VERSION "j1939-2025-03-v2.4-light"

NS_ :

BS_:

BU_:

BO_ 2364651518 HVESP3MS1: 8 Vector__XXX
 SG_ Hvesp3Module1OperationalStatus : 0|2@1+ (1,0) [0|3] "" Vector__XXX
 SG_ Hvesp3Module2OperationalStatus : 2|2@1+ (1,0) [0|3] "" Vector__XXX
 SG_ Hvesp3Module3OperationalStatus : 4|2@1+ (1,0) [0|3] "" Vector__XXX
 SG_ Hvesp3Module4OperationalStatus : 6|2@1+ (1,0) [0|3] "" Vector__XXX
 SG_ Hvesp3Module5OperationalStatus : 8|2@1+ (1,0) [0|3] "" Vector__XXX
 SG_ Hvesp3Module6OperationalStatus : 10|2@1+ (1,0) [0|3] "" Vector__XXX
 SG_ Hvesp3Module7OperationalStatus : 12|2@1+ (1,0) [0|3] "" Vector__XXX
 SG_ Hvesp3Module8OperationalStatus : 14|2@1+ (1,0) [0|3] "" Vector__XXX
 SG_ Hvesp3Module9OperationalStatus : 16|2@1+ (1,0) [0|3] "" Vector__XXX
 SG_ Hvesp3Module10OperationalStatus : 18|2@1+ (1,0) [0|3] "" Vector__XXX
 SG_ Hvesp3Module11OperationalStatus : 20|2@1+ (1,0) [0|3] "" Vector__XXX
 SG_ Hvesp3Module12OperationalStatus : 22|2@1+ (1,0) [0|3] "" Vector__XXX
 SG_ Hvesp3Module13OperationalStatus : 24|2@1+ (1,0) [0|3] "" Vector__XXX
 SG_ Hvesp3Module14OperationalStatus : 26|2@1+ (1,0) [0|3] "" Vector__XXX
 SG_ Hvesp3Module15OperationalStatus : 28|2@1+ (1,0) [0|3] "" Vector__XXX
 SG_ Hvesp3Module16OperationalStatus : 30|2@1+ (1,0) [0|3] "" Vector__XXX
 SG_ Hvesp3Module17OperationalStatus : 32|2@1+ (1,0) [0|3] "" Vector__XXX
 SG_ Hvesp3Module18OperationalStatus : 34|2@1+ (1,0) [0|3] "" Vector__XXX
 SG_ Hvesp3Module19OperationalStatus : 36|2@1+ (1,0) [0|3] "" Vector__XXX
 SG_ Hvesp3Module20OperationalStatus : 38|2@1+ (1,0) [0|3] "" Vector__XXX
 SG_ Hvesp3Module21OperationalStatus : 40|2@1+ (1,0) [0|3] "" Vector__XXX
 SG_ Hvesp3Module22OperationalStatus : 42|2@1+ (1,0) [0|3] "" Vector__XXX
 SG_ Hvesp3Module23OperationalStatus : 44|2@1+ (1,0) [0|3] "" Vector__XXX
 SG_ Hvesp3Module24OperationalStatus : 46|2@1+ (1,0) [0|3] "" Vector__XXX
 SG_ Hvesp3Module25OperationalStatus : 48|2@1+ (1,0) [0|3] "" Vector__XXX
 SG_ Hvesp3Module26OperationalStatus : 50|2@1+ (1,0) [0|3] "" Vector__XXX
 SG_ Hvesp3Module27OperationalStatus : 52|2@1+ (1,0) [0|3] "" Vector__XXX
 SG_ Hvesp3Module28OperationalStatus : 54|2@1+ (1,0) [0|3] "" Vector__XXX
 SG_ Hvesp3Module29OperationalStatus : 56|2@1+ (1,0) [0|3] "" Vector__XXX
 SG_ Hvesp3Module30OperationalStatus : 58|2@1+ (1,0) [0|3] "" Vector__XXX
 SG_ Hvesp3Module31OperationalStatus : 60|2@1+ (1,0) [0|3] "" Vector__XXX
 SG_ Hvesp3Module32OperationalStatus : 62|2@1+ (1,0) [0|3] "" Vector__XXX

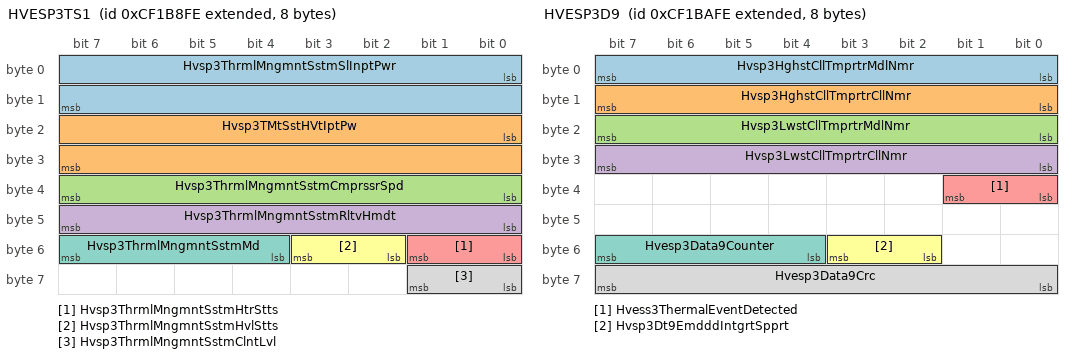
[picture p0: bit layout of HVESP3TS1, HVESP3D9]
BO_ 2364651774 HVESP3TS1: 8 Vector__XXX
 SG_ Hvsp3ThrmlMngmntSstmSlInptPwr : 0|16@1+ (0.5,0) [0|32127.5] "W" Vector__XXX
 SG_ Hvsp3TMtSstHVtIptPw : 16|16@1+ (0.5,0) [0|32127.5] "W" Vector__XXX
 SG_ Hvsp3ThrmlMngmntSstmCmprssrSpd : 32|8@1+ (32,0) [0|8000] "rpm" Vector__XXX
 SG_ Hvsp3ThrmlMngmntSstmRltvHmdt : 40|8@1+ (0.4,0) [0|100] "%" Vector__XXX
 SG_ Hvsp3ThrmlMngmntSstmHtrStts : 48|2@1+ (1,0) [0|3] "" Vector__XXX
 SG_ Hvsp3ThrmlMngmntSstmHvlStts : 50|2@1+ (1,0) [0|3] "" Vector__XXX
 SG_ Hvsp3ThrmlMngmntSstmMd : 52|4@1+ (1,0) [0|15] "" Vector__XXX
 SG_ Hvsp3ThrmlMngmntSstmClntLvl : 56|2@1+ (1,0) [0|3] "" Vector__XXX

BO_ 2364652030 HVESP3D8: 8 Vector__XXX
 SG_ Hvesp3AverageCellVoltage : 32|16@1+ (0.001,0) [0|64.255] "V" Vector__XXX
 SG_ Hvsp3HghstCllVltgMdlNmr : 0|8@1+ (1,0) [0|250] "count" Vector__XXX
 SG_ Hvsp3HghstCllVltgCllNmr : 8|8@1+ (1,0) [0|250] "count" Vector__XXX
 SG_ Hvsp3LwstCllVltgMdlNmr : 16|8@1+ (1,0) [0|250] "count" Vector__XXX
 SG_ Hvsp3LwstCllVltgCllNmr : 24|8@1+ (1,0) [0|250] "count" Vector__XXX

BO_ 2364652286 HVESP3D9: 8 Vector__XXX
 SG_ Hvsp3HghstCllTmprtrMdlNmr : 0|8@1+ (1,0) [0|250] "count" Vector__XXX
 SG_ Hvsp3HghstCllTmprtrCllNmr : 8|8@1+ (1,0) [0|250] "count" Vector__XXX
 SG_ Hvsp3LwstCllTmprtrMdlNmr : 16|8@1+ (1,0) [0|250] "count" Vector__XXX
 SG_ Hvsp3LwstCllTmprtrCllNmr : 24|8@1+ (1,0) [0|250] "count" Vector__XXX
 SG_ Hvess3ThermalEventDetected : 32|2@1+ (1,0) [0|3] "" Vector__XXX
 SG_ Hvsp3Dt9EmdddIntgrtSpprt : 50|2@1+ (1,0) [0|3] "" Vector__XXX
 SG_ Hvesp3Data9Counter : 52|4@1+ (1,0) [0|15] "" Vector__XXX
 SG_ Hvesp3Data9Crc : 56|8@1+ (1,0) [0|250] "count" Vector__XXX

BO_ 2364652542 HVESP3D10: 8 Vector__XXX
 SG_ Hvsp3HghstCllSttOfChrgMdlNmr : 0|8@1+ (1,0) [0|250] "count" Vector__XXX
 SG_ Hvsp3HghstCllSttOfChrgCllNmr : 8|8@1+ (1,0) [0|250] "count" Vector__XXX
 SG_ Hvsp3LwstCllSttOfChrgMdlNmr : 16|8@1+ (1,0) [0|250] "count" Vector__XXX
 SG_ Hvsp3LwstCllSttOfChrgCllNmr : 24|8@1+ (1,0) [0|250] "count" Vector__XXX
 SG_ Hvsp3HghVltgBsAtvIsltnTstRslts : 32|16@1+ (0.1,0) [0|6425.5] "OhmPerV" Vector__XXX
 SG_ Hvsp3HghVltgBsPssvIsltnTstRslts : 48|16@1+ (0.1,0) [0|6425.5] "OhmPerV" Vector__XXX

BO_ 2364652798 HVESP3D11: 8 Vector__XXX
 SG_ Hvesp3ActualChargeRate : 32|16@1+ (0.05,0) [0|3212.75] "kW" Vector__XXX
 SG_ Hvsp3BsVltgNgtvTChsssGrndVltg : 0|16@1+ (0.05,0) [0|3212.75] "V" Vector__XXX
 SG_ Hvsp3VltgLvlNgtvTChsssGrndVltg : 16|16@1+ (0.05,0) [0|3212.75] "V" Vector__XXX

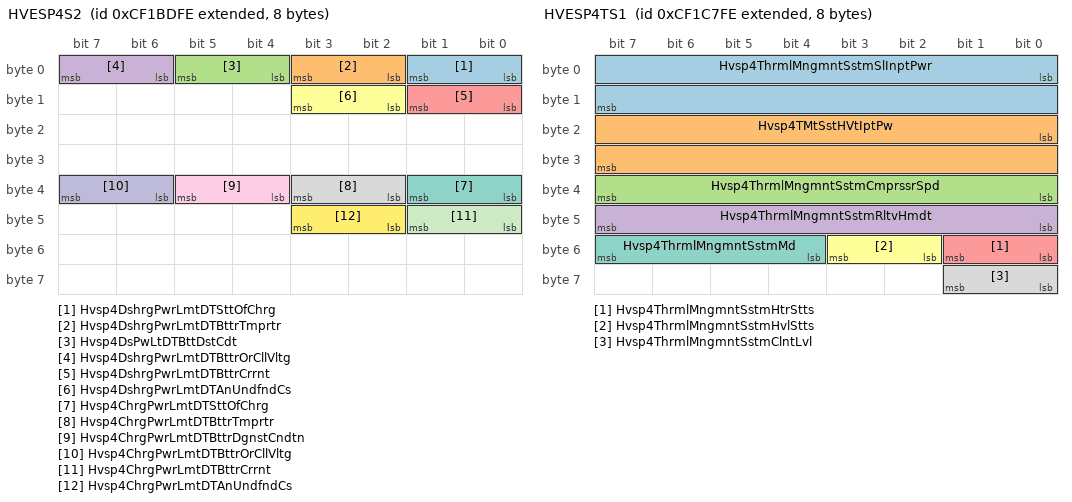
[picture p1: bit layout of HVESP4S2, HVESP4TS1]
BO_ 2364653054 HVESP4S2: 8 Vector__XXX
 SG_ Hvsp4DshrgPwrLmtDTSttOfChrg : 0|2@1+ (1,0) [0|3] "" Vector__XXX
 SG_ Hvsp4DshrgPwrLmtDTBttrTmprtr : 2|2@1+ (1,0) [0|3] "" Vector__XXX
 SG_ Hvsp4DsPwLtDTBttDstCdt : 4|2@1+ (1,0) [0|3] "" Vector__XXX
 SG_ Hvsp4DshrgPwrLmtDTBttrOrCllVltg : 6|2@1+ (1,0) [0|3] "" Vector__XXX
 SG_ Hvsp4DshrgPwrLmtDTBttrCrrnt : 8|2@1+ (1,0) [0|3] "" Vector__XXX
 SG_ Hvsp4DshrgPwrLmtDTAnUndfndCs : 10|2@1+ (1,0) [0|3] "" Vector__XXX
 SG_ Hvsp4ChrgPwrLmtDTSttOfChrg : 32|2@1+ (1,0) [0|3] "" Vector__XXX
 SG_ Hvsp4ChrgPwrLmtDTBttrTmprtr : 34|2@1+ (1,0) [0|3] "" Vector__XXX
 SG_ Hvsp4ChrgPwrLmtDTBttrDgnstCndtn : 36|2@1+ (1,0) [0|3] "" Vector__XXX
 SG_ Hvsp4ChrgPwrLmtDTBttrOrCllVltg : 38|2@1+ (1,0) [0|3] "" Vector__XXX
 SG_ Hvsp4ChrgPwrLmtDTBttrCrrnt : 40|2@1+ (1,0) [0|3] "" Vector__XXX
 SG_ Hvsp4ChrgPwrLmtDTAnUndfndCs : 42|2@1+ (1,0) [0|3] "" Vector__XXX

BO_ 2364653310 HVESP4D1: 8 Vector__XXX
 SG_ Hvesp4AvailableDischargePower : 0|16@1+ (0.05,0) [0|3212.75] "kW" Vector__XXX
 SG_ Hvesp4AvailableChargePower : 16|16@1+ (0.05,0) [0|3212.75] "kW" Vector__XXX
 SG_ Hvesp4VoltageLevel : 32|16@1+ (0.05,0) [0|3212.75] "V" Vector__XXX
 SG_ Hvesp4Current : 48|16@1+ (0.05,-1600) [-1600|1612.75] "A" Vector__XXX

BO_ 2364653566 HVESP4D2: 8 Vector__XXX
 SG_ Hvesp4FastUpdateStateOfCharge : 0|16@1+ (0.0015625,0) [0|100.3984375] "%" Vector__XXX
 SG_ Hvesp4HighestCellVoltage : 16|16@1+ (0.001,0) [0|64.255] "V" Vector__XXX
 SG_ Hvesp4LowestCellVoltage : 32|16@1+ (0.001,0) [0|64.255] "V" Vector__XXX
 SG_ Hvsp4CllVltgDffrntlStts : 48|4@1+ (1,0) [0|15] "" Vector__XXX

BO_ 2364653822 HVESP4D3: 8 Vector__XXX
 SG_ Hvesp4HighestCellTemperature : 0|16@1+ (0.03125,-273) [-273|1734.96875] "degC" Vector__XXX
 SG_ Hvesp4LowestCellTemperature : 16|16@1+ (0.03125,-273) [-273|1734.96875] "degC" Vector__XXX
 SG_ Hvesp4AverageCellTemperature : 32|16@1+ (0.03125,-273) [-273|1734.96875] "degC" Vector__XXX
 SG_ Hvsp4CllTmprtrDffrntlStts : 48|2@1+ (1,0) [0|3] "" Vector__XXX

BO_ 2364654078 HVESP4D4: 8 Vector__XXX
 SG_ Hvesp4DischargeCapacity : 0|16@1+ (0.01,0) [0|642.55] "Ah" Vector__XXX
 SG_ Hvesp4ChargeCapacity : 16|16@1+ (0.01,0) [0|642.55] "Ah" Vector__XXX
 SG_ Hvesp4CellBalancingCount : 32|16@1+ (1,0) [0|64255] "count" Vector__XXX

BO_ 2364654334 HVESP4D5: 8 Vector__XXX
 SG_ Hvesp4LowestCellStateOfCharge : 32|16@1+ (0.0015625,0) [0|100.3984375] "%" Vector__XXX
 SG_ Hvesp4HighestCellStateOfCharge : 48|16@1+ (0.0015625,0) [0|100.3984375] "%" Vector__XXX
 SG_ Hvsp4MxmmInstntnsDshrgCrrntLmt : 0|16@1+ (0.05,-1600) [-1600|0] "A" Vector__XXX
 SG_ Hvsp4MxmmInstntnsChrgCrrntLmt : 16|16@1+ (0.05,-1600) [0|1612.75] "A" Vector__XXX

BO_ 2364654590 HVESP4D6: 8 Vector__XXX
 SG_ Hvesp4BusVoltage : 0|16@1+ (0.05,0) [0|3212.75] "V" Vector__XXX
 SG_ Hvesp4IgnitionVoltage : 16|16@1+ (0.01,0) [0|642.55] "V" Vector__XXX
 SG_ Hvesp4IntakeCoolantTemperature : 32|8@1+ (1,-40) [-40|210] "degC" Vector__XXX
 SG_ Hvesp4OutletCoolantTemperature : 40|8@1+ (1,-40) [-40|210] "degC" Vector__XXX
 SG_ Hvesp4ElectronicsTemperature : 48|8@1+ (1,-40) [-40|210] "degC" Vector__XXX
 SG_ Hvesp4Temperature : 56|8@1+ (1,-40) [-40|210] "degC" Vector__XXX

BO_ 2364654846 HVESP4S1: 8 Vector__XXX
 SG_ Hvesp4HvilStatus : 20|2@1+ (1,0) [0|3] "" Vector__XXX
 SG_ Hvesp4InertiaSwitchStatus : 22|2@1+ (1,0) [0|3] "" Vector__XXX
 SG_ Hvesp4StateOfChargeStatus : 24|4@1+ (1,0) [0|15] "" Vector__XXX
 SG_ Hvesp4CellBalanceStatus : 28|2@1+ (1,0) [0|3] "" Vector__XXX
 SG_ Hvesp4CellBalancingActive : 30|2@1+ (1,0) [0|3] "" Vector__XXX
 SG_ Hvesp4InternalChargerStatus : 32|2@1+ (1,0) [0|3] "" Vector__XXX
 SG_ Hvesp4OperationalStatus : 44|4@1+ (1,0) [0|15] "" Vector__XXX
 SG_ Hvesp4Status1Counter : 52|4@1+ (1,0) [0|15] "" Vector__XXX
 SG_ Hvesp4Status1Crc : 56|8@1+ (1,0) [0|250] "count" Vector__XXX
 SG_ Hvsp4HghVltgBsPstvCnttrStt : 0|2@1+ (1,0) [0|3] "" Vector__XXX
 SG_ Hvsp4HghVltgBsNgtvCnttrStt : 2|2@1+ (1,0) [0|3] "" Vector__XXX
 SG_ Hvsp4HghVltgBsDsnntFrwrnng : 4|4@1+ (1,0) [0|15] "" Vector__XXX
 SG_ Hvsp4HghVltgBsPrChrgRlStt : 8|2@1+ (1,0) [0|3] "" Vector__XXX
 SG_ Hvsp4CntrOfPkCnttrStt : 10|2@1+ (1,0) [0|3] "" Vector__XXX
 SG_ Hvsp4HghVltgBsAtvIsltnTstStts : 12|4@1+ (1,0) [0|15] "" Vector__XXX
 SG_ Hvsp4HghVltgBsPssvIsltnTstStts : 16|4@1+ (1,0) [0|15] "" Vector__XXX
 SG_ Hvsp4HghVltgBsCnntnStts : 40|4@1+ (1,0) [0|15] "" Vector__XXX

BO_ 2364655102 HVESP4D7: 8 Vector__XXX
 SG_ Hvesp4DischargeEnergyCapacity : 0|24@1+ (0.001,0) [0|16449.535] "kWh" Vector__XXX
 SG_ Hvesp4ChargeEnergyCapacity : 24|24@1+ (0.001,0) [0|16449.535] "kWh" Vector__XXX
 SG_ Hvesp4MaximumChargeVoltageLimit : 48|16@1+ (0.05,0) [0|3212.75] "V" Vector__XXX

BO_ 2364655358 HVESP4MS1: 8 Vector__XXX
 SG_ Hvesp4Module1OperationalStatus : 0|2@1+ (1,0) [0|3] "" Vector__XXX
 SG_ Hvesp4Module2OperationalStatus : 2|2@1+ (1,0) [0|3] "" Vector__XXX
 SG_ Hvesp4Module3OperationalStatus : 4|2@1+ (1,0) [0|3] "" Vector__XXX
 SG_ Hvesp4Module4OperationalStatus : 6|2@1+ (1,0) [0|3] "" Vector__XXX
 SG_ Hvesp4Module5OperationalStatus : 8|2@1+ (1,0) [0|3] "" Vector__XXX
 SG_ Hvesp4Module6OperationalStatus : 10|2@1+ (1,0) [0|3] "" Vector__XXX
 SG_ Hvesp4Module7OperationalStatus : 12|2@1+ (1,0) [0|3] "" Vector__XXX
 SG_ Hvesp4Module8OperationalStatus : 14|2@1+ (1,0) [0|3] "" Vector__XXX
 SG_ Hvesp4Module9OperationalStatus : 16|2@1+ (1,0) [0|3] "" Vector__XXX
 SG_ Hvesp4Module10OperationalStatus : 18|2@1+ (1,0) [0|3] "" Vector__XXX
 SG_ Hvesp4Module11OperationalStatus : 20|2@1+ (1,0) [0|3] "" Vector__XXX
 SG_ Hvesp4Module12OperationalStatus : 22|2@1+ (1,0) [0|3] "" Vector__XXX
 SG_ Hvesp4Module13OperationalStatus : 24|2@1+ (1,0) [0|3] "" Vector__XXX
 SG_ Hvesp4Module14OperationalStatus : 26|2@1+ (1,0) [0|3] "" Vector__XXX
 SG_ Hvesp4Module15OperationalStatus : 28|2@1+ (1,0) [0|3] "" Vector__XXX
 SG_ Hvesp4Module16OperationalStatus : 30|2@1+ (1,0) [0|3] "" Vector__XXX
 SG_ Hvesp4Module17OperationalStatus : 32|2@1+ (1,0) [0|3] "" Vector__XXX
 SG_ Hvesp4Module18OperationalStatus : 34|2@1+ (1,0) [0|3] "" Vector__XXX
 SG_ Hvesp4Module19OperationalStatus : 36|2@1+ (1,0) [0|3] "" Vector__XXX
 SG_ Hvesp4Module20OperationalStatus : 38|2@1+ (1,0) [0|3] "" Vector__XXX
 SG_ Hvesp4Module21OperationalStatus : 40|2@1+ (1,0) [0|3] "" Vector__XXX
 SG_ Hvesp4Module22OperationalStatus : 42|2@1+ (1,0) [0|3] "" Vector__XXX
 SG_ Hvesp4Module23OperationalStatus : 44|2@1+ (1,0) [0|3] "" Vector__XXX
 SG_ Hvesp4Module24OperationalStatus : 46|2@1+ (1,0) [0|3] "" Vector__XXX
 SG_ Hvesp4Module25OperationalStatus : 48|2@1+ (1,0) [0|3] "" Vector__XXX
 SG_ Hvesp4Module26OperationalStatus : 50|2@1+ (1,0) [0|3] "" Vector__XXX
 SG_ Hvesp4Module27OperationalStatus : 52|2@1+ (1,0) [0|3] "" Vector__XXX
 SG_ Hvesp4Module28OperationalStatus : 54|2@1+ (1,0) [0|3] "" Vector__XXX
 SG_ Hvesp4Module29OperationalStatus : 56|2@1+ (1,0) [0|3] "" Vector__XXX
 SG_ Hvesp4Module30OperationalStatus : 58|2@1+ (1,0) [0|3] "" Vector__XXX
 SG_ Hvesp4Module31OperationalStatus : 60|2@1+ (1,0) [0|3] "" Vector__XXX
 SG_ Hvesp4Module32OperationalStatus : 62|2@1+ (1,0) [0|3] "" Vector__XXX

BO_ 2364655614 HVESP4TS1: 8 Vector__XXX
 SG_ Hvsp4ThrmlMngmntSstmSlInptPwr : 0|16@1+ (0.5,0) [0|32127.5] "W" Vector__XXX
 SG_ Hvsp4TMtSstHVtIptPw : 16|16@1+ (0.5,0) [0|32127.5] "W" Vector__XXX
 SG_ Hvsp4ThrmlMngmntSstmCmprssrSpd : 32|8@1+ (32,0) [0|8000] "rpm" Vector__XXX
 SG_ Hvsp4ThrmlMngmntSstmRltvHmdt : 40|8@1+ (0.4,0) [0|100] "%" Vector__XXX
 SG_ Hvsp4ThrmlMngmntSstmHtrStts : 48|2@1+ (1,0) [0|3] "" Vector__XXX
 SG_ Hvsp4ThrmlMngmntSstmHvlStts : 50|2@1+ (1,0) [0|3] "" Vector__XXX
 SG_ Hvsp4ThrmlMngmntSstmMd : 52|4@1+ (1,0) [0|15] "" Vector__XXX
 SG_ Hvsp4ThrmlMngmntSstmClntLvl : 56|2@1+ (1,0) [0|3] "" Vector__XXX

BO_ 2364655870 HVESP4D8: 8 Vector__XXX
 SG_ Hvesp4AverageCellVoltage : 32|16@1+ (0.001,0) [0|64.255] "V" Vector__XXX
 SG_ Hvsp4HghstCllVltgMdlNmr : 0|8@1+ (1,0) [0|250] "count" Vector__XXX
 SG_ Hvsp4HghstCllVltgCllNmr : 8|8@1+ (1,0) [0|250] "count" Vector__XXX
 SG_ Hvsp4LwstCllVltgMdlNmr : 16|8@1+ (1,0) [0|250] "count" Vector__XXX
 SG_ Hvsp4LwstCllVltgCllNmr : 24|8@1+ (1,0) [0|250] "count" Vector__XXX

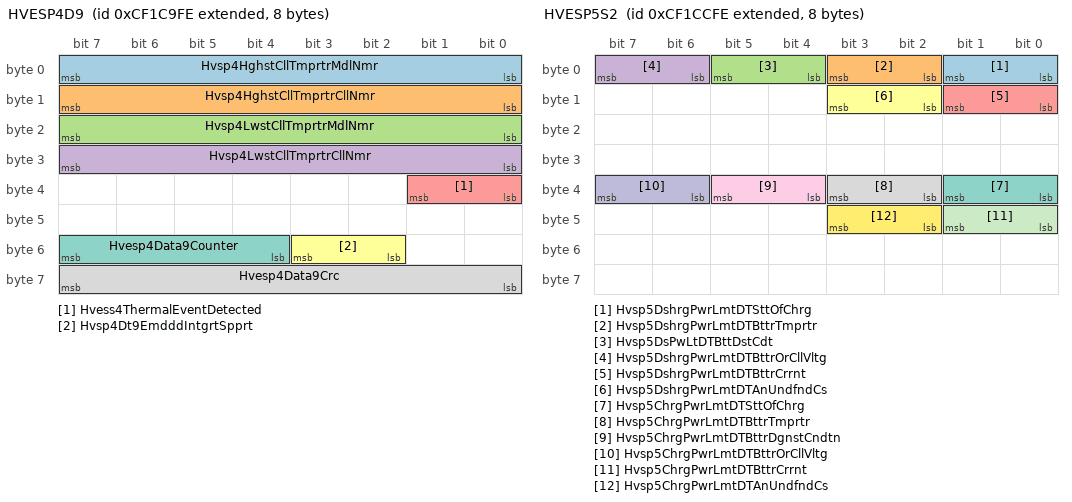
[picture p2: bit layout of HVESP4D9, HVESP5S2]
BO_ 2364656126 HVESP4D9: 8 Vector__XXX
 SG_ Hvsp4HghstCllTmprtrMdlNmr : 0|8@1+ (1,0) [0|250] "count" Vector__XXX
 SG_ Hvsp4HghstCllTmprtrCllNmr : 8|8@1+ (1,0) [0|250] "count" Vector__XXX
 SG_ Hvsp4LwstCllTmprtrMdlNmr : 16|8@1+ (1,0) [0|250] "count" Vector__XXX
 SG_ Hvsp4LwstCllTmprtrCllNmr : 24|8@1+ (1,0) [0|250] "count" Vector__XXX
 SG_ Hvess4ThermalEventDetected : 32|2@1+ (1,0) [0|3] "" Vector__XXX
 SG_ Hvsp4Dt9EmdddIntgrtSpprt : 50|2@1+ (1,0) [0|3] "" Vector__XXX
 SG_ Hvesp4Data9Counter : 52|4@1+ (1,0) [0|15] "" Vector__XXX
 SG_ Hvesp4Data9Crc : 56|8@1+ (1,0) [0|250] "count" Vector__XXX

BO_ 2364656382 HVESP4D10: 8 Vector__XXX
 SG_ Hvsp4HghstCllSttOfChrgMdlNmr : 0|8@1+ (1,0) [0|250] "count" Vector__XXX
 SG_ Hvsp4HghstCllSttOfChrgCllNmr : 8|8@1+ (1,0) [0|250] "count" Vector__XXX
 SG_ Hvsp4LwstCllSttOfChrgMdlNmr : 16|8@1+ (1,0) [0|250] "count" Vector__XXX
 SG_ Hvsp4LwstCllSttOfChrgCllNmr : 24|8@1+ (1,0) [0|250] "count" Vector__XXX
 SG_ Hvsp4HghVltgBsAtvIsltnTstRslts : 32|16@1+ (0.1,0) [0|6425.5] "OhmPerV" Vector__XXX
 SG_ Hvsp4HghVltgBsPssvIsltnTstRslts : 48|16@1+ (0.1,0) [0|6425.5] "OhmPerV" Vector__XXX

BO_ 2364656638 HVESP4D11: 8 Vector__XXX
 SG_ Hvesp4ActualChargeRate : 32|16@1+ (0.05,0) [0|3212.75] "kW" Vector__XXX
 SG_ Hvsp4BsVltgNgtvTChsssGrndVltg : 0|16@1+ (0.05,0) [0|3212.75] "V" Vector__XXX
 SG_ Hvsp4VltgLvlNgtvTChsssGrndVltg : 16|16@1+ (0.05,0) [0|3212.75] "V" Vector__XXX

BO_ 2364656894 HVESP5S2: 8 Vector__XXX
 SG_ Hvsp5DshrgPwrLmtDTSttOfChrg : 0|2@1+ (1,0) [0|3] "" Vector__XXX
 SG_ Hvsp5DshrgPwrLmtDTBttrTmprtr : 2|2@1+ (1,0) [0|3] "" Vector__XXX
 SG_ Hvsp5DsPwLtDTBttDstCdt : 4|2@1+ (1,0) [0|3] "" Vector__XXX
 SG_ Hvsp5DshrgPwrLmtDTBttrOrCllVltg : 6|2@1+ (1,0) [0|3] "" Vector__XXX
 SG_ Hvsp5DshrgPwrLmtDTBttrCrrnt : 8|2@1+ (1,0) [0|3] "" Vector__XXX
 SG_ Hvsp5DshrgPwrLmtDTAnUndfndCs : 10|2@1+ (1,0) [0|3] "" Vector__XXX
 SG_ Hvsp5ChrgPwrLmtDTSttOfChrg : 32|2@1+ (1,0) [0|3] "" Vector__XXX
 SG_ Hvsp5ChrgPwrLmtDTBttrTmprtr : 34|2@1+ (1,0) [0|3] "" Vector__XXX
 SG_ Hvsp5ChrgPwrLmtDTBttrDgnstCndtn : 36|2@1+ (1,0) [0|3] "" Vector__XXX
 SG_ Hvsp5ChrgPwrLmtDTBttrOrCllVltg : 38|2@1+ (1,0) [0|3] "" Vector__XXX
 SG_ Hvsp5ChrgPwrLmtDTBttrCrrnt : 40|2@1+ (1,0) [0|3] "" Vector__XXX
 SG_ Hvsp5ChrgPwrLmtDTAnUndfndCs : 42|2@1+ (1,0) [0|3] "" Vector__XXX

BO_ 2364657150 HVESP5D1: 8 Vector__XXX
 SG_ Hvesp5AvailableDischargePower : 0|16@1+ (0.05,0) [0|3212.75] "kW" Vector__XXX
 SG_ Hvesp5AvailableChargePower : 16|16@1+ (0.05,0) [0|3212.75] "kW" Vector__XXX
 SG_ Hvesp5VoltageLevel : 32|16@1+ (0.05,0) [0|3212.75] "V" Vector__XXX
 SG_ Hvesp5Current : 48|16@1+ (0.05,-1600) [-1600|1612.75] "A" Vector__XXX

BO_ 2364657406 HVESP5D2: 8 Vector__XXX
 SG_ Hvesp5FastUpdateStateOfCharge : 0|16@1+ (0.0015625,0) [0|100.3984375] "%" Vector__XXX
 SG_ Hvesp5HighestCellVoltage : 16|16@1+ (0.001,0) [0|64.255] "V" Vector__XXX
 SG_ Hvesp5LowestCellVoltage : 32|16@1+ (0.001,0) [0|64.255] "V" Vector__XXX
 SG_ Hvsp5CllVltgDffrntlStts : 48|4@1+ (1,0) [0|15] "" Vector__XXX

BO_ 2364657662 HVESP5D3: 8 Vector__XXX
 SG_ Hvesp5HighestCellTemperature : 0|16@1+ (0.03125,-273) [-273|1734.96875] "degC" Vector__XXX
 SG_ Hvesp5LowestCellTemperature : 16|16@1+ (0.03125,-273) [-273|1734.96875] "degC" Vector__XXX
 SG_ Hvesp5AverageCellTemperature : 32|16@1+ (0.03125,-273) [-273|1734.96875] "degC" Vector__XXX
 SG_ Hvsp5CllTmprtrDffrntlStts : 48|2@1+ (1,0) [0|3] "" Vector__XXX

BO_ 2364657918 HVESP5D4: 8 Vector__XXX
 SG_ Hvesp5DischargeCapacity : 0|16@1+ (0.01,0) [0|642.55] "Ah" Vector__XXX
 SG_ Hvesp5ChargeCapacity : 16|16@1+ (0.01,0) [0|642.55] "Ah" Vector__XXX
 SG_ Hvesp5CellBalancingCount : 32|16@1+ (1,0) [0|64255] "count" Vector__XXX

BO_ 2364658174 HVESP5D5: 8 Vector__XXX
 SG_ Hvesp5LowestCellStateOfCharge : 32|16@1+ (0.0015625,0) [0|100.3984375] "%" Vector__XXX
 SG_ Hvesp5HighestCellStateOfCharge : 48|16@1+ (0.0015625,0) [0|100.3984375] "%" Vector__XXX
 SG_ Hvsp5MxmmInstntnsDshrgCrrntLmt : 0|16@1+ (0.05,-1600) [-1600|0] "A" Vector__XXX
 SG_ Hvsp5MxmmInstntnsChrgCrrntLmt : 16|16@1+ (0.05,-1600) [0|1612.75] "A" Vector__XXX

BO_ 2364658430 HVESP5D6: 8 Vector__XXX
 SG_ Hvesp5BusVoltage : 0|16@1+ (0.05,0) [0|3212.75] "V" Vector__XXX
 SG_ Hvesp5IgnitionVoltage : 16|16@1+ (0.01,0) [0|642.55] "V" Vector__XXX
 SG_ Hvesp5IntakeCoolantTemperature : 32|8@1+ (1,-40) [-40|210] "degC" Vector__XXX
 SG_ Hvesp5OutletCoolantTemperature : 40|8@1+ (1,-40) [-40|210] "degC" Vector__XXX
 SG_ Hvesp5ElectronicsTemperature : 48|8@1+ (1,-40) [-40|210] "degC" Vector__XXX
 SG_ Hvesp5Temperature : 56|8@1+ (1,-40) [-40|210] "degC" Vector__XXX

BO_ 2364658686 HVESP5S1: 8 Vector__XXX
 SG_ Hvesp5HvilStatus : 20|2@1+ (1,0) [0|3] "" Vector__XXX
 SG_ Hvesp5InertiaSwitchStatus : 22|2@1+ (1,0) [0|3] "" Vector__XXX
 SG_ Hvesp5StateOfChargeStatus : 24|4@1+ (1,0) [0|15] "" Vector__XXX
 SG_ Hvesp5CellBalanceStatus : 28|2@1+ (1,0) [0|3] "" Vector__XXX
 SG_ Hvesp5CellBalancingActive : 30|2@1+ (1,0) [0|3] "" Vector__XXX
 SG_ Hvesp5InternalChargerStatus : 32|2@1+ (1,0) [0|3] "" Vector__XXX
 SG_ Hvesp5OperationalStatus : 44|4@1+ (1,0) [0|15] "" Vector__XXX
 SG_ Hvesp5Status1Counter : 52|4@1+ (1,0) [0|15] "" Vector__XXX
 SG_ Hvesp5Status1Crc : 56|8@1+ (1,0) [0|250] "count" Vector__XXX
 SG_ Hvsp5HghVltgBsPstvCnttrStt : 0|2@1+ (1,0) [0|3] "" Vector__XXX
 SG_ Hvsp5HghVltgBsNgtvCnttrStt : 2|2@1+ (1,0) [0|3] "" Vector__XXX
 SG_ Hvsp5HghVltgBsDsnntFrwrnng : 4|4@1+ (1,0) [0|15] "" Vector__XXX
 SG_ Hvsp5HghVltgBsPrChrgRlStt : 8|2@1+ (1,0) [0|3] "" Vector__XXX
 SG_ Hvsp5CntrOfPkCnttrStt : 10|2@1+ (1,0) [0|3] "" Vector__XXX
 SG_ Hvsp5HghVltgBsAtvIsltnTstStts : 12|4@1+ (1,0) [0|15] "" Vector__XXX
 SG_ Hvsp5HghVltgBsPssvIsltnTstStts : 16|4@1+ (1,0) [0|15] "" Vector__XXX
 SG_ Hvsp5HghVltgBsCnntnStts : 40|4@1+ (1,0) [0|15] "" Vector__XXX

BO_ 2364658942 HVESP5D7: 8 Vector__XXX
 SG_ Hvesp5DischargeEnergyCapacity : 0|24@1+ (0.001,0) [0|16449.535] "kWh" Vector__XXX
 SG_ Hvesp5ChargeEnergyCapacity : 24|24@1+ (0.001,0) [0|16449.535] "kWh" Vector__XXX
 SG_ Hvesp5MaximumChargeVoltageLimit : 48|16@1+ (0.05,0) [0|3212.75] "V" Vector__XXX

BO_ 2364659198 HVESP5MS1: 8 Vector__XXX
 SG_ Hvesp5Module1OperationalStatus : 0|2@1+ (1,0) [0|3] "" Vector__XXX
 SG_ Hvesp5Module2OperationalStatus : 2|2@1+ (1,0) [0|3] "" Vector__XXX
 SG_ Hvesp5Module3OperationalStatus : 4|2@1+ (1,0) [0|3] "" Vector__XXX
 SG_ Hvesp5Module4OperationalStatus : 6|2@1+ (1,0) [0|3] "" Vector__XXX
 SG_ Hvesp5Module5OperationalStatus : 8|2@1+ (1,0) [0|3] "" Vector__XXX
 SG_ Hvesp5Module6OperationalStatus : 10|2@1+ (1,0) [0|3] "" Vector__XXX
 SG_ Hvesp5Module7OperationalStatus : 12|2@1+ (1,0) [0|3] "" Vector__XXX
 SG_ Hvesp5Module8OperationalStatus : 14|2@1+ (1,0) [0|3] "" Vector__XXX
 SG_ Hvesp5Module9OperationalStatus : 16|2@1+ (1,0) [0|3] "" Vector__XXX
 SG_ Hvesp5Module10OperationalStatus : 18|2@1+ (1,0) [0|3] "" Vector__XXX
 SG_ Hvesp5Module11OperationalStatus : 20|2@1+ (1,0) [0|3] "" Vector__XXX
 SG_ Hvesp5Module12OperationalStatus : 22|2@1+ (1,0) [0|3] "" Vector__XXX
 SG_ Hvesp5Module13OperationalStatus : 24|2@1+ (1,0) [0|3] "" Vector__XXX
 SG_ Hvesp5Module14OperationalStatus : 26|2@1+ (1,0) [0|3] "" Vector__XXX
 SG_ Hvesp5Module15OperationalStatus : 28|2@1+ (1,0) [0|3] "" Vector__XXX
 SG_ Hvesp5Module16OperationalStatus : 30|2@1+ (1,0) [0|3] "" Vector__XXX
 SG_ Hvesp5Module17OperationalStatus : 32|2@1+ (1,0) [0|3] "" Vector__XXX
 SG_ Hvesp5Module18OperationalStatus : 34|2@1+ (1,0) [0|3] "" Vector__XXX
 SG_ Hvesp5Module19OperationalStatus : 36|2@1+ (1,0) [0|3] "" Vector__XXX
 SG_ Hvesp5Module20OperationalStatus : 38|2@1+ (1,0) [0|3] "" Vector__XXX
 SG_ Hvesp5Module21OperationalStatus : 40|2@1+ (1,0) [0|3] "" Vector__XXX
 SG_ Hvesp5Module22OperationalStatus : 42|2@1+ (1,0) [0|3] "" Vector__XXX
 SG_ Hvesp5Module23OperationalStatus : 44|2@1+ (1,0) [0|3] "" Vector__XXX
 SG_ Hvesp5Module24OperationalStatus : 46|2@1+ (1,0) [0|3] "" Vector__XXX
 SG_ Hvesp5Module25OperationalStatus : 48|2@1+ (1,0) [0|3] "" Vector__XXX
 SG_ Hvesp5Module26OperationalStatus : 50|2@1+ (1,0) [0|3] "" Vector__XXX
 SG_ Hvesp5Module27OperationalStatus : 52|2@1+ (1,0) [0|3] "" Vector__XXX
 SG_ Hvesp5Module28OperationalStatus : 54|2@1+ (1,0) [0|3] "" Vector__XXX
 SG_ Hvesp5Module29OperationalStatus : 56|2@1+ (1,0) [0|3] "" Vector__XXX
 SG_ Hvesp5Module30OperationalStatus : 58|2@1+ (1,0) [0|3] "" Vector__XXX
 SG_ Hvesp5Module31OperationalStatus : 60|2@1+ (1,0) [0|3] "" Vector__XXX
 SG_ Hvesp5Module32OperationalStatus : 62|2@1+ (1,0) [0|3] "" Vector__XXX

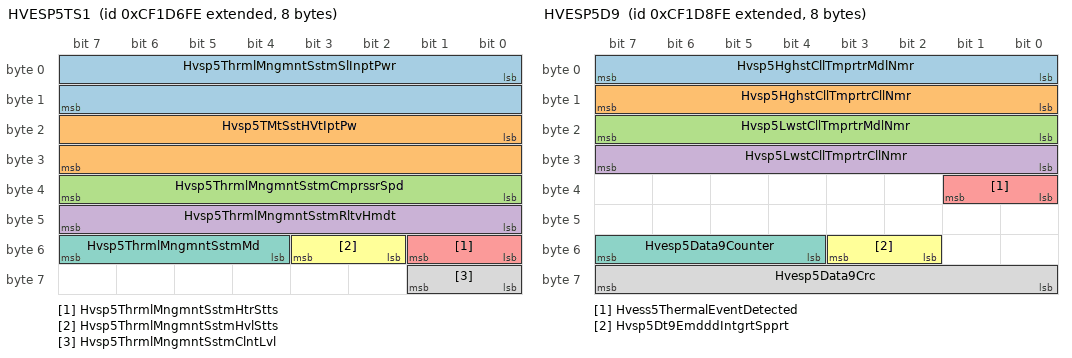
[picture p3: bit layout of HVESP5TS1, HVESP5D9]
BO_ 2364659454 HVESP5TS1: 8 Vector__XXX
 SG_ Hvsp5ThrmlMngmntSstmSlInptPwr : 0|16@1+ (0.5,0) [0|32127.5] "W" Vector__XXX
 SG_ Hvsp5TMtSstHVtIptPw : 16|16@1+ (0.5,0) [0|32127.5] "W" Vector__XXX
 SG_ Hvsp5ThrmlMngmntSstmCmprssrSpd : 32|8@1+ (32,0) [0|8000] "rpm" Vector__XXX
 SG_ Hvsp5ThrmlMngmntSstmRltvHmdt : 40|8@1+ (0.4,0) [0|100] "%" Vector__XXX
 SG_ Hvsp5ThrmlMngmntSstmHtrStts : 48|2@1+ (1,0) [0|3] "" Vector__XXX
 SG_ Hvsp5ThrmlMngmntSstmHvlStts : 50|2@1+ (1,0) [0|3] "" Vector__XXX
 SG_ Hvsp5ThrmlMngmntSstmMd : 52|4@1+ (1,0) [0|15] "" Vector__XXX
 SG_ Hvsp5ThrmlMngmntSstmClntLvl : 56|2@1+ (1,0) [0|3] "" Vector__XXX

BO_ 2364659710 HVESP5D8: 8 Vector__XXX
 SG_ Hvesp5AverageCellVoltage : 32|16@1+ (0.001,0) [0|64.255] "V" Vector__XXX
 SG_ Hvsp5HghstCllVltgMdlNmr : 0|8@1+ (1,0) [0|250] "count" Vector__XXX
 SG_ Hvsp5HghstCllVltgCllNmr : 8|8@1+ (1,0) [0|250] "count" Vector__XXX
 SG_ Hvsp5LwstCllVltgMdlNmr : 16|8@1+ (1,0) [0|250] "count" Vector__XXX
 SG_ Hvsp5LwstCllVltgCllNmr : 24|8@1+ (1,0) [0|250] "count" Vector__XXX

BO_ 2364659966 HVESP5D9: 8 Vector__XXX
 SG_ Hvsp5HghstCllTmprtrMdlNmr : 0|8@1+ (1,0) [0|250] "count" Vector__XXX
 SG_ Hvsp5HghstCllTmprtrCllNmr : 8|8@1+ (1,0) [0|250] "count" Vector__XXX
 SG_ Hvsp5LwstCllTmprtrMdlNmr : 16|8@1+ (1,0) [0|250] "count" Vector__XXX
 SG_ Hvsp5LwstCllTmprtrCllNmr : 24|8@1+ (1,0) [0|250] "count" Vector__XXX
 SG_ Hvess5ThermalEventDetected : 32|2@1+ (1,0) [0|3] "" Vector__XXX
 SG_ Hvsp5Dt9EmdddIntgrtSpprt : 50|2@1+ (1,0) [0|3] "" Vector__XXX
 SG_ Hvesp5Data9Counter : 52|4@1+ (1,0) [0|15] "" Vector__XXX
 SG_ Hvesp5Data9Crc : 56|8@1+ (1,0) [0|250] "count" Vector__XXX

BO_ 2364660222 HVESP5D10: 8 Vector__XXX
 SG_ Hvsp5HghstCllSttOfChrgMdlNmr : 0|8@1+ (1,0) [0|250] "count" Vector__XXX
 SG_ Hvsp5HghstCllSttOfChrgCllNmr : 8|8@1+ (1,0) [0|250] "count" Vector__XXX
 SG_ Hvsp5LwstCllSttOfChrgMdlNmr : 16|8@1+ (1,0) [0|250] "count" Vector__XXX
 SG_ Hvsp5LwstCllSttOfChrgCllNmr : 24|8@1+ (1,0) [0|250] "count" Vector__XXX
 SG_ Hvsp5HghVltgBsAtvIsltnTstRslts : 32|16@1+ (0.1,0) [0|6425.5] "OhmPerV" Vector__XXX
 SG_ Hvsp5HghVltgBsPssvIsltnTstRslts : 48|16@1+ (0.1,0) [0|6425.5] "OhmPerV" Vector__XXX

BO_ 2364660478 HVESP5D11: 8 Vector__XXX
 SG_ Hvesp5ActualChargeRate : 32|16@1+ (0.05,0) [0|3212.75] "kW" Vector__XXX
 SG_ Hvsp5BsVltgNgtvTChsssGrndVltg : 0|16@1+ (0.05,0) [0|3212.75] "V" Vector__XXX
 SG_ Hvsp5VltgLvlNgtvTChsssGrndVltg : 16|16@1+ (0.05,0) [0|3212.75] "V" Vector__XXX

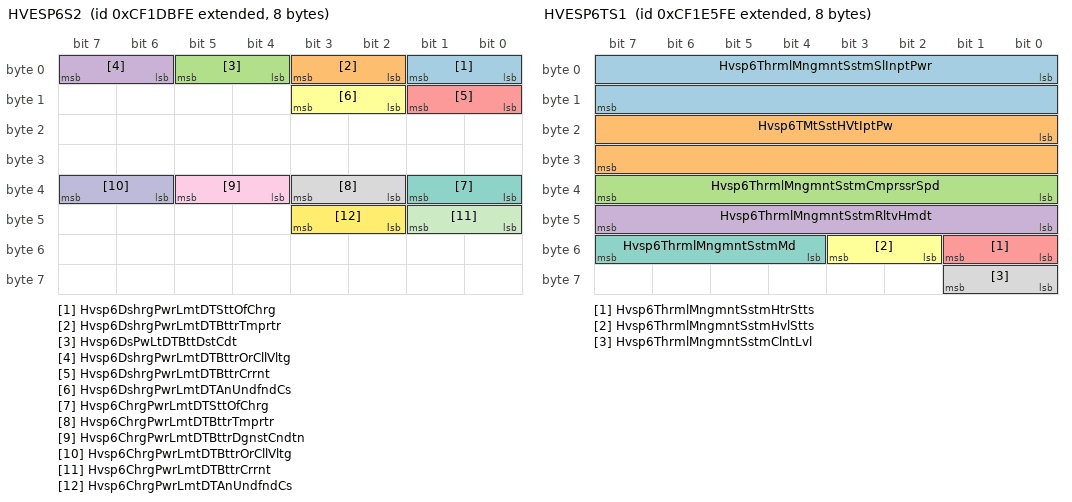
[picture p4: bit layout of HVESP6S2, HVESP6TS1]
BO_ 2364660734 HVESP6S2: 8 Vector__XXX
 SG_ Hvsp6DshrgPwrLmtDTSttOfChrg : 0|2@1+ (1,0) [0|3] "" Vector__XXX
 SG_ Hvsp6DshrgPwrLmtDTBttrTmprtr : 2|2@1+ (1,0) [0|3] "" Vector__XXX
 SG_ Hvsp6DsPwLtDTBttDstCdt : 4|2@1+ (1,0) [0|3] "" Vector__XXX
 SG_ Hvsp6DshrgPwrLmtDTBttrOrCllVltg : 6|2@1+ (1,0) [0|3] "" Vector__XXX
 SG_ Hvsp6DshrgPwrLmtDTBttrCrrnt : 8|2@1+ (1,0) [0|3] "" Vector__XXX
 SG_ Hvsp6DshrgPwrLmtDTAnUndfndCs : 10|2@1+ (1,0) [0|3] "" Vector__XXX
 SG_ Hvsp6ChrgPwrLmtDTSttOfChrg : 32|2@1+ (1,0) [0|3] "" Vector__XXX
 SG_ Hvsp6ChrgPwrLmtDTBttrTmprtr : 34|2@1+ (1,0) [0|3] "" Vector__XXX
 SG_ Hvsp6ChrgPwrLmtDTBttrDgnstCndtn : 36|2@1+ (1,0) [0|3] "" Vector__XXX
 SG_ Hvsp6ChrgPwrLmtDTBttrOrCllVltg : 38|2@1+ (1,0) [0|3] "" Vector__XXX
 SG_ Hvsp6ChrgPwrLmtDTBttrCrrnt : 40|2@1+ (1,0) [0|3] "" Vector__XXX
 SG_ Hvsp6ChrgPwrLmtDTAnUndfndCs : 42|2@1+ (1,0) [0|3] "" Vector__XXX

BO_ 2364660990 HVESP6D1: 8 Vector__XXX
 SG_ Hvesp6AvailableDischargePower : 0|16@1+ (0.05,0) [0|3212.75] "kW" Vector__XXX
 SG_ Hvesp6AvailableChargePower : 16|16@1+ (0.05,0) [0|3212.75] "kW" Vector__XXX
 SG_ Hvesp6VoltageLevel : 32|16@1+ (0.05,0) [0|3212.75] "V" Vector__XXX
 SG_ Hvesp6Current : 48|16@1+ (0.05,-1600) [-1600|1612.75] "A" Vector__XXX

BO_ 2364661246 HVESP6D2: 8 Vector__XXX
 SG_ Hvesp6FastUpdateStateOfCharge : 0|16@1+ (0.0015625,0) [0|100.3984375] "%" Vector__XXX
 SG_ Hvesp6HighestCellVoltage : 16|16@1+ (0.001,0) [0|64.255] "V" Vector__XXX
 SG_ Hvesp6LowestCellVoltage : 32|16@1+ (0.001,0) [0|64.255] "V" Vector__XXX
 SG_ Hvsp6CllVltgDffrntlStts : 48|4@1+ (1,0) [0|15] "" Vector__XXX

BO_ 2364661502 HVESP6D3: 8 Vector__XXX
 SG_ Hvesp6HighestCellTemperature : 0|16@1+ (0.03125,-273) [-273|1734.96875] "degC" Vector__XXX
 SG_ Hvesp6LowestCellTemperature : 16|16@1+ (0.03125,-273) [-273|1734.96875] "degC" Vector__XXX
 SG_ Hvesp6AverageCellTemperature : 32|16@1+ (0.03125,-273) [-273|1734.96875] "degC" Vector__XXX
 SG_ Hvsp6CllTmprtrDffrntlStts : 48|2@1+ (1,0) [0|3] "" Vector__XXX

BO_ 2364661758 HVESP6D4: 8 Vector__XXX
 SG_ Hvesp6DischargeCapacity : 0|16@1+ (0.01,0) [0|642.55] "Ah" Vector__XXX
 SG_ Hvesp6ChargeCapacity : 16|16@1+ (0.01,0) [0|642.55] "Ah" Vector__XXX
 SG_ Hvesp6CellBalancingCount : 32|16@1+ (1,0) [0|64255] "count" Vector__XXX

BO_ 2364662014 HVESP6D5: 8 Vector__XXX
 SG_ Hvesp6LowestCellStateOfCharge : 32|16@1+ (0.0015625,0) [0|100.3984375] "%" Vector__XXX
 SG_ Hvesp6HighestCellStateOfCharge : 48|16@1+ (0.0015625,0) [0|100.3984375] "%" Vector__XXX
 SG_ Hvsp6MxmmInstntnsDshrgCrrntLmt : 0|16@1+ (0.05,-1600) [-1600|0] "A" Vector__XXX
 SG_ Hvsp6MxmmInstntnsChrgCrrntLmt : 16|16@1+ (0.05,-1600) [0|1612.75] "A" Vector__XXX

BO_ 2364662270 HVESP6D6: 8 Vector__XXX
 SG_ Hvesp6BusVoltage : 0|16@1+ (0.05,0) [0|3212.75] "V" Vector__XXX
 SG_ Hvesp6IgnitionVoltage : 16|16@1+ (0.01,0) [0|642.55] "V" Vector__XXX
 SG_ Hvesp6IntakeCoolantTemperature : 32|8@1+ (1,-40) [-40|210] "degC" Vector__XXX
 SG_ Hvesp6OutletCoolantTemperature : 40|8@1+ (1,-40) [-40|210] "degC" Vector__XXX
 SG_ Hvesp6ElectronicsTemperature : 48|8@1+ (1,-40) [-40|210] "degC" Vector__XXX
 SG_ Hvesp6Temperature : 56|8@1+ (1,-40) [-40|210] "degC" Vector__XXX

BO_ 2364662526 HVESP6S1: 8 Vector__XXX
 SG_ Hvesp6HvilStatus : 20|2@1+ (1,0) [0|3] "" Vector__XXX
 SG_ Hvesp6InertiaSwitchStatus : 22|2@1+ (1,0) [0|3] "" Vector__XXX
 SG_ Hvesp6StateOfChargeStatus : 24|4@1+ (1,0) [0|15] "" Vector__XXX
 SG_ Hvesp6CellBalanceStatus : 28|2@1+ (1,0) [0|3] "" Vector__XXX
 SG_ Hvesp6CellBalancingActive : 30|2@1+ (1,0) [0|3] "" Vector__XXX
 SG_ Hvesp6InternalChargerStatus : 32|2@1+ (1,0) [0|3] "" Vector__XXX
 SG_ Hvesp6OperationalStatus : 44|4@1+ (1,0) [0|15] "" Vector__XXX
 SG_ Hvesp6Status1Counter : 52|4@1+ (1,0) [0|15] "" Vector__XXX
 SG_ Hvesp6Status1Crc : 56|8@1+ (1,0) [0|250] "count" Vector__XXX
 SG_ Hvsp6HghVltgBsPstvCnttrStt : 0|2@1+ (1,0) [0|3] "" Vector__XXX
 SG_ Hvsp6HghVltgBsNgtvCnttrStt : 2|2@1+ (1,0) [0|3] "" Vector__XXX
 SG_ Hvsp6HghVltgBsDsnntFrwrnng : 4|4@1+ (1,0) [0|15] "" Vector__XXX
 SG_ Hvsp6HghVltgBsPrChrgRlStt : 8|2@1+ (1,0) [0|3] "" Vector__XXX
 SG_ Hvsp6CntrOfPkCnttrStt : 10|2@1+ (1,0) [0|3] "" Vector__XXX
 SG_ Hvsp6HghVltgBsAtvIsltnTstStts : 12|4@1+ (1,0) [0|15] "" Vector__XXX
 SG_ Hvsp6HghVltgBsPssvIsltnTstStts : 16|4@1+ (1,0) [0|15] "" Vector__XXX
 SG_ Hvsp6HghVltgBsCnntnStts : 40|4@1+ (1,0) [0|15] "" Vector__XXX

BO_ 2364662782 HVESP6D7: 8 Vector__XXX
 SG_ Hvesp6DischargeEnergyCapacity : 0|24@1+ (0.001,0) [0|16449.535] "kWh" Vector__XXX
 SG_ Hvesp6ChargeEnergyCapacity : 24|24@1+ (0.001,0) [0|16449.535] "kWh" Vector__XXX
 SG_ Hvesp6MaximumChargeVoltageLimit : 48|16@1+ (0.05,0) [0|3212.75] "V" Vector__XXX

BO_ 2364663038 HVESP6MS1: 8 Vector__XXX
 SG_ Hvesp6Module1OperationalStatus : 0|2@1+ (1,0) [0|3] "" Vector__XXX
 SG_ Hvesp6Module2OperationalStatus : 2|2@1+ (1,0) [0|3] "" Vector__XXX
 SG_ Hvesp6Module3OperationalStatus : 4|2@1+ (1,0) [0|3] "" Vector__XXX
 SG_ Hvesp6Module4OperationalStatus : 6|2@1+ (1,0) [0|3] "" Vector__XXX
 SG_ Hvesp6Module5OperationalStatus : 8|2@1+ (1,0) [0|3] "" Vector__XXX
 SG_ Hvesp6Module6OperationalStatus : 10|2@1+ (1,0) [0|3] "" Vector__XXX
 SG_ Hvesp6Module7OperationalStatus : 12|2@1+ (1,0) [0|3] "" Vector__XXX
 SG_ Hvesp6Module8OperationalStatus : 14|2@1+ (1,0) [0|3] "" Vector__XXX
 SG_ Hvesp6Module9OperationalStatus : 16|2@1+ (1,0) [0|3] "" Vector__XXX
 SG_ Hvesp6Module10OperationalStatus : 18|2@1+ (1,0) [0|3] "" Vector__XXX
 SG_ Hvesp6Module11OperationalStatus : 20|2@1+ (1,0) [0|3] "" Vector__XXX
 SG_ Hvesp6Module12OperationalStatus : 22|2@1+ (1,0) [0|3] "" Vector__XXX
 SG_ Hvesp6Module13OperationalStatus : 24|2@1+ (1,0) [0|3] "" Vector__XXX
 SG_ Hvesp6Module14OperationalStatus : 26|2@1+ (1,0) [0|3] "" Vector__XXX
 SG_ Hvesp6Module15OperationalStatus : 28|2@1+ (1,0) [0|3] "" Vector__XXX
 SG_ Hvesp6Module16OperationalStatus : 30|2@1+ (1,0) [0|3] "" Vector__XXX
 SG_ Hvesp6Module17OperationalStatus : 32|2@1+ (1,0) [0|3] "" Vector__XXX
 SG_ Hvesp6Module18OperationalStatus : 34|2@1+ (1,0) [0|3] "" Vector__XXX
 SG_ Hvesp6Module19OperationalStatus : 36|2@1+ (1,0) [0|3] "" Vector__XXX
 SG_ Hvesp6Module20OperationalStatus : 38|2@1+ (1,0) [0|3] "" Vector__XXX
 SG_ Hvesp6Module21OperationalStatus : 40|2@1+ (1,0) [0|3] "" Vector__XXX
 SG_ Hvesp6Module22OperationalStatus : 42|2@1+ (1,0) [0|3] "" Vector__XXX
 SG_ Hvesp6Module23OperationalStatus : 44|2@1+ (1,0) [0|3] "" Vector__XXX
 SG_ Hvesp6Module24OperationalStatus : 46|2@1+ (1,0) [0|3] "" Vector__XXX
 SG_ Hvesp6Module25OperationalStatus : 48|2@1+ (1,0) [0|3] "" Vector__XXX
 SG_ Hvesp6Module26OperationalStatus : 50|2@1+ (1,0) [0|3] "" Vector__XXX
 SG_ Hvesp6Module27OperationalStatus : 52|2@1+ (1,0) [0|3] "" Vector__XXX
 SG_ Hvesp6Module28OperationalStatus : 54|2@1+ (1,0) [0|3] "" Vector__XXX
 SG_ Hvesp6Module29OperationalStatus : 56|2@1+ (1,0) [0|3] "" Vector__XXX
 SG_ Hvesp6Module30OperationalStatus : 58|2@1+ (1,0) [0|3] "" Vector__XXX
 SG_ Hvesp6Module31OperationalStatus : 60|2@1+ (1,0) [0|3] "" Vector__XXX
 SG_ Hvesp6Module32OperationalStatus : 62|2@1+ (1,0) [0|3] "" Vector__XXX

BO_ 2364663294 HVESP6TS1: 8 Vector__XXX
 SG_ Hvsp6ThrmlMngmntSstmSlInptPwr : 0|16@1+ (0.5,0) [0|32127.5] "W" Vector__XXX
 SG_ Hvsp6TMtSstHVtIptPw : 16|16@1+ (0.5,0) [0|32127.5] "W" Vector__XXX
 SG_ Hvsp6ThrmlMngmntSstmCmprssrSpd : 32|8@1+ (32,0) [0|8000] "rpm" Vector__XXX
 SG_ Hvsp6ThrmlMngmntSstmRltvHmdt : 40|8@1+ (0.4,0) [0|100] "%" Vector__XXX
 SG_ Hvsp6ThrmlMngmntSstmHtrStts : 48|2@1+ (1,0) [0|3] "" Vector__XXX
 SG_ Hvsp6ThrmlMngmntSstmHvlStts : 50|2@1+ (1,0) [0|3] "" Vector__XXX
 SG_ Hvsp6ThrmlMngmntSstmMd : 52|4@1+ (1,0) [0|15] "" Vector__XXX
 SG_ Hvsp6ThrmlMngmntSstmClntLvl : 56|2@1+ (1,0) [0|3] "" Vector__XXX

BO_ 2364663550 HVESP6D8: 8 Vector__XXX
 SG_ Hvesp6AverageCellVoltage : 32|16@1+ (0.001,0) [0|64.255] "V" Vector__XXX
 SG_ Hvsp6HghstCllVltgMdlNmr : 0|8@1+ (1,0) [0|250] "count" Vector__XXX
 SG_ Hvsp6HghstCllVltgCllNmr : 8|8@1+ (1,0) [0|250] "count" Vector__XXX
 SG_ Hvsp6LwstCllVltgMdlNmr : 16|8@1+ (1,0) [0|250] "count" Vector__XXX
 SG_ Hvsp6LwstCllVltgCllNmr : 24|8@1+ (1,0) [0|250] "count" Vector__XXX

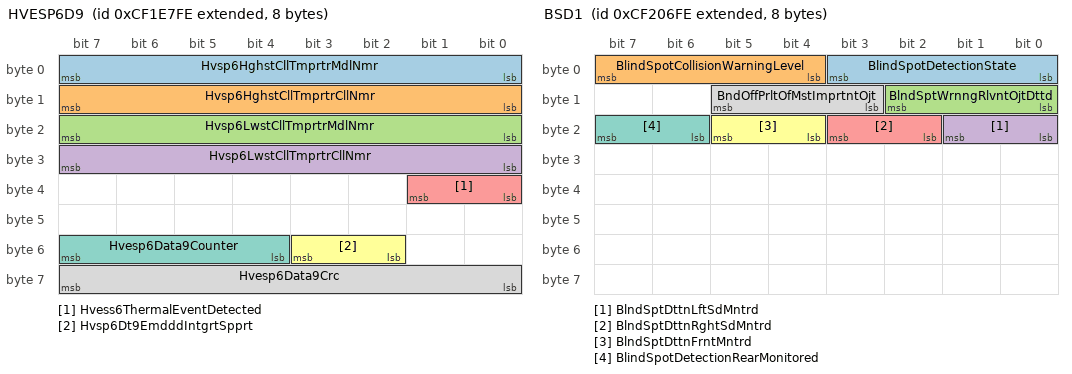
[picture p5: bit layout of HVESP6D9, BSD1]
BO_ 2364663806 HVESP6D9: 8 Vector__XXX
 SG_ Hvsp6HghstCllTmprtrMdlNmr : 0|8@1+ (1,0) [0|250] "count" Vector__XXX
 SG_ Hvsp6HghstCllTmprtrCllNmr : 8|8@1+ (1,0) [0|250] "count" Vector__XXX
 SG_ Hvsp6LwstCllTmprtrMdlNmr : 16|8@1+ (1,0) [0|250] "count" Vector__XXX
 SG_ Hvsp6LwstCllTmprtrCllNmr : 24|8@1+ (1,0) [0|250] "count" Vector__XXX
 SG_ Hvess6ThermalEventDetected : 32|2@1+ (1,0) [0|3] "" Vector__XXX
 SG_ Hvsp6Dt9EmdddIntgrtSpprt : 50|2@1+ (1,0) [0|3] "" Vector__XXX
 SG_ Hvesp6Data9Counter : 52|4@1+ (1,0) [0|15] "" Vector__XXX
 SG_ Hvesp6Data9Crc : 56|8@1+ (1,0) [0|250] "count" Vector__XXX

BO_ 2364664062 HVESP6D10: 8 Vector__XXX
 SG_ Hvsp6HghstCllSttOfChrgMdlNmr : 0|8@1+ (1,0) [0|250] "count" Vector__XXX
 SG_ Hvsp6HghstCllSttOfChrgCllNmr : 8|8@1+ (1,0) [0|250] "count" Vector__XXX
 SG_ Hvsp6LwstCllSttOfChrgMdlNmr : 16|8@1+ (1,0) [0|250] "count" Vector__XXX
 SG_ Hvsp6LwstCllSttOfChrgCllNmr : 24|8@1+ (1,0) [0|250] "count" Vector__XXX
 SG_ Hvsp6HghVltgBsAtvIsltnTstRslts : 32|16@1+ (0.1,0) [0|6425.5] "OhmPerV" Vector__XXX
 SG_ Hvsp6HghVltgBsPssvIsltnTstRslts : 48|16@1+ (0.1,0) [0|6425.5] "OhmPerV" Vector__XXX

BO_ 2364664318 HVESP6D11: 8 Vector__XXX
 SG_ Hvesp6ActualChargeRate : 32|16@1+ (0.05,0) [0|3212.75] "kW" Vector__XXX
 SG_ Hvsp6BsVltgNgtvTChsssGrndVltg : 0|16@1+ (0.05,0) [0|3212.75] "V" Vector__XXX
 SG_ Hvsp6VltgLvlNgtvTChsssGrndVltg : 16|16@1+ (0.05,0) [0|3212.75] "V" Vector__XXX

BO_ 2364664574 MG3IMF1: 8 Vector__XXX
 SG_ MtrGnrtr3InvrtrMdFdk1Cntr : 8|4@1+ (1,0) [0|15] "" Vector__XXX
 SG_ MtrGnrtr3InvrtrCntrlLmtsOvrrdMd : 12|4@1+ (1,0) [0|15] "" Vector__XXX
 SG_ MtrGnrtr3InvrtrCntrlStpntMd : 16|5@1+ (1,0) [0|31] "" Vector__XXX
 SG_ MtrGnrtr3InvrtrMdFdk1Cr : 0|8@1+ (1,0) [0|250] "count" Vector__XXX
 SG_ MtrGnrtr3InvrtrHvlStts : 21|2@1+ (1,0) [0|3] "" Vector__XXX

BO_ 2565991422 MG3ILAP: 8 Vector__XXX
 SG_ MtrGnrtr3InvrtrLmtsAtvPwrCntr : 8|4@1+ (1,0) [0|15] "" Vector__XXX
 SG_ MtGt3IvtLtsAtvMPwMx : 12|12@1+ (0.0625,-125) [-125|125.9375] "%" Vector__XXX
 SG_ MtGt3IvtLtsAtvMPwM : 24|12@1+ (0.0625,-125) [-125|125.9375] "%" Vector__XXX
 SG_ MtrGnrtr3InvrtrLmtsAtvPwrCr : 0|8@1+ (1,0) [0|250] "count" Vector__XXX
 SG_ MtGt3IvtLtsAtvDSdPwMx : 36|12@1+ (0.0625,-125) [-125|125.9375] "%" Vector__XXX
 SG_ MtGt3IvtLtsAtvDSdPwM : 48|12@1+ (0.0625,-125) [-125|125.9375] "%" Vector__XXX

BO_ 2565991678 MG3ILAM: 8 Vector__XXX
 SG_ MtrGnrtr3InvrtrLmtsAtvMhnlCntr : 8|4@1+ (1,0) [0|15] "" Vector__XXX
 SG_ MtrGnrtr3InvrtrLmtsAtvTrqMxmm : 12|12@1+ (0.0625,-125) [-125|125.9375] "%" Vector__XXX
 SG_ MtrGnrtr3InvrtrLmtsAtvTrqMnmm : 24|12@1+ (0.0625,-125) [-125|125.9375] "%" Vector__XXX
 SG_ MtrGnrtr3InvrtrLmtsAtvSpdMxmm : 36|12@1+ (0.0625,-125) [-125|125.9375] "%" Vector__XXX
 SG_ MtrGnrtr3InvrtrLmtsAtvSpdMnmm : 48|12@1+ (0.0625,-125) [-125|125.9375] "%" Vector__XXX
 SG_ MtrGnrtr3InvrtrLmtsAtvMhnlCr : 0|8@1+ (1,0) [0|250] "count" Vector__XXX

BO_ 2565991934 MG3ILADC: 8 Vector__XXX
 SG_ MtrGnrtr3InvrtrLmtsAtvDSdCr : 0|8@1+ (1,0) [0|250] "count" Vector__XXX
 SG_ MtrGnrtr3InvrtrLmtsAtvDSdCntr : 8|4@1+ (1,0) [0|15] "" Vector__XXX
 SG_ MtGt3IvtLtsAtvDSdVtMx : 12|12@1+ (0.0625,-125) [-125|125.9375] "%" Vector__XXX
 SG_ MtGt3IvtLtsAtvDSdVtM : 24|12@1+ (0.0625,-125) [-125|125.9375] "%" Vector__XXX
 SG_ MtGt3IvtLtsAtvDSdCtMx : 36|12@1+ (0.0625,-125) [-125|125.9375] "%" Vector__XXX
 SG_ MtGt3IvtLtsAtvDSdCtM : 48|12@1+ (0.0625,-125) [-125|125.9375] "%" Vector__XXX

BO_ 2565992190 MG3ILV: 8 Vector__XXX
 SG_ MtrGnrtr3InvrtrSwthdIgntnVltg : 0|16@1+ (0.05,0) [0|3212.75] "V" Vector__XXX
 SG_ MtrGnrtr3InvrtrUnswthdSlVltg : 16|16@1+ (0.05,0) [0|3212.75] "V" Vector__XXX

BO_ 2565992446 MG3IS2: 8 Vector__XXX
 SG_ MtrGnrtr3InvrtrStts2Cntr : 8|4@1+ (1,0) [0|15] "" Vector__XXX
 SG_ MtrGnrtr3AvllMxmmTrq : 12|12@1+ (0.0625,-125) [-125|125.9375] "%" Vector__XXX
 SG_ MtrGnrtr3AvllMnmmTrq : 24|12@1+ (0.0625,-125) [-125|125.9375] "%" Vector__XXX
 SG_ MtrGnrtr3InvrtrStts2Cr : 0|8@1+ (1,0) [0|250] "count" Vector__XXX

BO_ 2565992702 MG3IRLA1: 8 Vector__XXX
 SG_ MtrGnrtr3InvrtrRtLmtsAtv1Cntr : 8|4@1+ (1,0) [0|15] "" Vector__XXX
 SG_ MtGt3IvtRtLtsAtvAstSpdRtLt : 12|12@1+ (0.25,0) [0|1003.75] "%/s" Vector__XXX
 SG_ MtGt3IvtRtLtsAtvAstTqRtLt : 24|12@1+ (2,0) [0|8030] "%/s" Vector__XXX
 SG_ MtrGnrtr3InvrtrRtLmtsAtv1Cr : 0|8@1+ (1,0) [0|250] "count" Vector__XXX

BO_ 2364666366 MG4IMF1: 8 Vector__XXX
 SG_ MtrGnrtr4InvrtrMdFdk1Cntr : 8|4@1+ (1,0) [0|15] "" Vector__XXX
 SG_ MtrGnrtr4InvrtrCntrlLmtsOvrrdMd : 12|4@1+ (1,0) [0|15] "" Vector__XXX
 SG_ MtrGnrtr4InvrtrCntrlStpntMd : 16|5@1+ (1,0) [0|31] "" Vector__XXX
 SG_ MtrGnrtr4InvrtrMdFdk1Cr : 0|8@1+ (1,0) [0|250] "count" Vector__XXX
 SG_ MtrGnrtr4InvrtrHvlStts : 21|2@1+ (1,0) [0|3] "" Vector__XXX

BO_ 2565993214 MG4ILAP: 8 Vector__XXX
 SG_ MtrGnrtr4InvrtrLmtsAtvPwrCntr : 8|4@1+ (1,0) [0|15] "" Vector__XXX
 SG_ MtGt4IvtLtsAtvMPwMx : 12|12@1+ (0.0625,-125) [-125|125.9375] "%" Vector__XXX
 SG_ MtGt4IvtLtsAtvMPwM : 24|12@1+ (0.0625,-125) [-125|125.9375] "%" Vector__XXX
 SG_ MtrGnrtr4InvrtrLmtsAtvPwrCr : 0|8@1+ (1,0) [0|250] "count" Vector__XXX
 SG_ MtGt4IvtLtsAtvDSdPwMx : 36|12@1+ (0.0625,-125) [-125|125.9375] "%" Vector__XXX
 SG_ MtGt4IvtLtsAtvDSdPwM : 48|12@1+ (0.0625,-125) [-125|125.9375] "%" Vector__XXX

BO_ 2565993470 MG4ILAM: 8 Vector__XXX
 SG_ MtrGnrtr4InvrtrLmtsAtvMhnlCntr : 8|4@1+ (1,0) [0|15] "" Vector__XXX
 SG_ MtrGnrtr4InvrtrLmtsAtvTrqMxmm : 12|12@1+ (0.0625,-125) [-125|125.9375] "%" Vector__XXX
 SG_ MtrGnrtr4InvrtrLmtsAtvTrqMnmm : 24|12@1+ (0.0625,-125) [-125|125.9375] "%" Vector__XXX
 SG_ MtrGnrtr4InvrtrLmtsAtvSpdMxmm : 36|12@1+ (0.0625,-125) [-125|125.9375] "%" Vector__XXX
 SG_ MtrGnrtr4InvrtrLmtsAtvSpdMnmm : 48|12@1+ (0.0625,-125) [-125|125.9375] "%" Vector__XXX
 SG_ MtrGnrtr4InvrtrLmtsAtvMhnlCr : 0|8@1+ (1,0) [0|250] "count" Vector__XXX

BO_ 2565993726 MG4ILADC: 8 Vector__XXX
 SG_ MtrGnrtr4InvrtrLmtsAtvDSdCr : 0|8@1+ (1,0) [0|250] "count" Vector__XXX
 SG_ MtrGnrtr4InvrtrLmtsAtvDSdCntr : 8|4@1+ (1,0) [0|15] "" Vector__XXX
 SG_ MtGt4IvtLtsAtvDSdVtMx : 12|12@1+ (0.0625,-125) [-125|125.9375] "%" Vector__XXX
 SG_ MtGt4IvtLtsAtvDSdVtM : 24|12@1+ (0.0625,-125) [-125|125.9375] "%" Vector__XXX
 SG_ MtGt4IvtLtsAtvDSdCtMx : 36|12@1+ (0.0625,-125) [-125|125.9375] "%" Vector__XXX
 SG_ MtGt4IvtLtsAtvDSdCtM : 48|12@1+ (0.0625,-125) [-125|125.9375] "%" Vector__XXX

BO_ 2565993982 MG4ILV: 8 Vector__XXX
 SG_ MtrGnrtr4InvrtrSwthdIgntnVltg : 0|16@1+ (0.05,0) [0|3212.75] "V" Vector__XXX
 SG_ MtrGnrtr4InvrtrUnswthdSlVltg : 16|16@1+ (0.05,0) [0|3212.75] "V" Vector__XXX

BO_ 2565994238 MG4IS2: 8 Vector__XXX
 SG_ MtrGnrtr4InvrtrStts2Cntr : 8|4@1+ (1,0) [0|15] "" Vector__XXX
 SG_ MtrGnrtr4AvllMxmmTrq : 12|12@1+ (0.0625,-125) [-125|125.9375] "%" Vector__XXX
 SG_ MtrGnrtr4AvllMnmmTrq : 24|12@1+ (0.0625,-125) [-125|125.9375] "%" Vector__XXX
 SG_ MtrGnrtr4InvrtrStts2Cr : 0|8@1+ (1,0) [0|250] "count" Vector__XXX

BO_ 2565994494 MG4IRLA1: 8 Vector__XXX
 SG_ MtrGnrtr4InvrtrRtLmtsAtv1Cntr : 8|4@1+ (1,0) [0|15] "" Vector__XXX
 SG_ MtGt4IvtRtLtsAtvAstSpdRtLt : 12|12@1+ (0.25,0) [0|1003.75] "%/s" Vector__XXX
 SG_ MtGt4IvtRtLtsAtvAstTqRtLt : 24|12@1+ (2,0) [0|8030] "%/s" Vector__XXX
 SG_ MtrGnrtr4InvrtrRtLmtsAtv1Cr : 0|8@1+ (1,0) [0|250] "count" Vector__XXX

BO_ 2364668158 MG5IMF1: 8 Vector__XXX
 SG_ MtrGnrtr5InvrtrMdFdk1Cntr : 8|4@1+ (1,0) [0|15] "" Vector__XXX
 SG_ MtrGnrtr5InvrtrCntrlLmtsOvrrdMd : 12|4@1+ (1,0) [0|15] "" Vector__XXX
 SG_ MtrGnrtr5InvrtrCntrlStpntMd : 16|5@1+ (1,0) [0|31] "" Vector__XXX
 SG_ MtrGnrtr5InvrtrMdFdk1Cr : 0|8@1+ (1,0) [0|250] "count" Vector__XXX
 SG_ MtrGnrtr5InvrtrHvlStts : 21|2@1+ (1,0) [0|3] "" Vector__XXX

BO_ 2565995006 MG5ILAP: 8 Vector__XXX
 SG_ MtrGnrtr5InvrtrLmtsAtvPwrCntr : 8|4@1+ (1,0) [0|15] "" Vector__XXX
 SG_ MtGt5IvtLtsAtvMPwMx : 12|12@1+ (0.0625,-125) [-125|125.9375] "%" Vector__XXX
 SG_ MtGt5IvtLtsAtvMPwM : 24|12@1+ (0.0625,-125) [-125|125.9375] "%" Vector__XXX
 SG_ MtrGnrtr5InvrtrLmtsAtvPwrCr : 0|8@1+ (1,0) [0|250] "count" Vector__XXX
 SG_ MtGt5IvtLtsAtvDSdPwMx : 36|12@1+ (0.0625,-125) [-125|125.9375] "%" Vector__XXX
 SG_ MtGt5IvtLtsAtvDSdPwM : 48|12@1+ (0.0625,-125) [-125|125.9375] "%" Vector__XXX

BO_ 2565995262 MG5ILAM: 8 Vector__XXX
 SG_ MtrGnrtr5InvrtrLmtsAtvMhnlCntr : 8|4@1+ (1,0) [0|15] "" Vector__XXX
 SG_ MtrGnrtr5InvrtrLmtsAtvTrqMxmm : 12|12@1+ (0.0625,-125) [-125|125.9375] "%" Vector__XXX
 SG_ MtrGnrtr5InvrtrLmtsAtvTrqMnmm : 24|12@1+ (0.0625,-125) [-125|125.9375] "%" Vector__XXX
 SG_ MtrGnrtr5InvrtrLmtsAtvSpdMxmm : 36|12@1+ (0.0625,-125) [-125|125.9375] "%" Vector__XXX
 SG_ MtrGnrtr5InvrtrLmtsAtvSpdMnmm : 48|12@1+ (0.0625,-125) [-125|125.9375] "%" Vector__XXX
 SG_ MtrGnrtr5InvrtrLmtsAtvMhnlCr : 0|8@1+ (1,0) [0|250] "count" Vector__XXX

BO_ 2565995518 MG5ILADC: 8 Vector__XXX
 SG_ MtrGnrtr5InvrtrLmtsAtvDSdCr : 0|8@1+ (1,0) [0|250] "count" Vector__XXX
 SG_ MtrGnrtr5InvrtrLmtsAtvDSdCntr : 8|4@1+ (1,0) [0|15] "" Vector__XXX
 SG_ MtGt5IvtLtsAtvDSdVtMx : 12|12@1+ (0.0625,-125) [-125|125.9375] "%" Vector__XXX
 SG_ MtGt5IvtLtsAtvDSdVtM : 24|12@1+ (0.0625,-125) [-125|125.9375] "%" Vector__XXX
 SG_ MtGt5IvtLtsAtvDSdCtMx : 36|12@1+ (0.0625,-125) [-125|125.9375] "%" Vector__XXX
 SG_ MtGt5IvtLtsAtvDSdCtM : 48|12@1+ (0.0625,-125) [-125|125.9375] "%" Vector__XXX

BO_ 2565995774 MG5ILV: 8 Vector__XXX
 SG_ MtrGnrtr5InvrtrSwthdIgntnVltg : 0|16@1+ (0.05,0) [0|3212.75] "V" Vector__XXX
 SG_ MtrGnrtr5InvrtrUnswthdSlVltg : 16|16@1+ (0.05,0) [0|3212.75] "V" Vector__XXX

BO_ 2565996030 MG5IS2: 8 Vector__XXX
 SG_ MtrGnrtr5InvrtrStts2Cntr : 8|4@1+ (1,0) [0|15] "" Vector__XXX
 SG_ MtrGnrtr5AvllMxmmTrq : 12|12@1+ (0.0625,-125) [-125|125.9375] "%" Vector__XXX
 SG_ MtrGnrtr5AvllMnmmTrq : 24|12@1+ (0.0625,-125) [-125|125.9375] "%" Vector__XXX
 SG_ MtrGnrtr5InvrtrStts2Cr : 0|8@1+ (1,0) [0|250] "count" Vector__XXX

BO_ 2565996286 MG5IRLA1: 8 Vector__XXX
 SG_ MtrGnrtr5InvrtrRtLmtsAtv1Cntr : 8|4@1+ (1,0) [0|15] "" Vector__XXX
 SG_ MtGt5IvtRtLtsAtvAstSpdRtLt : 12|12@1+ (0.25,0) [0|1003.75] "%/s" Vector__XXX
 SG_ MtGt5IvtRtLtsAtvAstTqRtLt : 24|12@1+ (2,0) [0|8030] "%/s" Vector__XXX
 SG_ MtrGnrtr5InvrtrRtLmtsAtv1Cr : 0|8@1+ (1,0) [0|250] "count" Vector__XXX

BO_ 2364669950 MG6IMF1: 8 Vector__XXX
 SG_ MtrGnrtr6InvrtrMdFdk1Cntr : 8|4@1+ (1,0) [0|15] "" Vector__XXX
 SG_ MtrGnrtr6InvrtrCntrlLmtsOvrrdMd : 12|4@1+ (1,0) [0|15] "" Vector__XXX
 SG_ MtrGnrtr6InvrtrCntrlStpntMd : 16|5@1+ (1,0) [0|31] "" Vector__XXX
 SG_ MtrGnrtr6InvrtrMdFdk1Cr : 0|8@1+ (1,0) [0|250] "count" Vector__XXX
 SG_ MtrGnrtr6InvrtrHvlStts : 21|2@1+ (1,0) [0|3] "" Vector__XXX

BO_ 2565996798 MG6ILAP: 8 Vector__XXX
 SG_ MtrGnrtr6InvrtrLmtsAtvPwrCntr : 8|4@1+ (1,0) [0|15] "" Vector__XXX
 SG_ MtGt6IvtLtsAtvMPwMx : 12|12@1+ (0.0625,-125) [-125|125.9375] "%" Vector__XXX
 SG_ MtGt6IvtLtsAtvMPwM : 24|12@1+ (0.0625,-125) [-125|125.9375] "%" Vector__XXX
 SG_ MtrGnrtr6InvrtrLmtsAtvPwrCr : 0|8@1+ (1,0) [0|250] "count" Vector__XXX
 SG_ MtGt6IvtLtsAtvDSdPwMx : 36|12@1+ (0.0625,-125) [-125|125.9375] "%" Vector__XXX
 SG_ MtGt6IvtLtsAtvDSdPwM : 48|12@1+ (0.0625,-125) [-125|125.9375] "%" Vector__XXX

BO_ 2565997054 MG6ILAM: 8 Vector__XXX
 SG_ MtrGnrtr6InvrtrLmtsAtvMhnlCntr : 8|4@1+ (1,0) [0|15] "" Vector__XXX
 SG_ MtrGnrtr6InvrtrLmtsAtvTrqMxmm : 12|12@1+ (0.0625,-125) [-125|125.9375] "%" Vector__XXX
 SG_ MtrGnrtr6InvrtrLmtsAtvTrqMnmm : 24|12@1+ (0.0625,-125) [-125|125.9375] "%" Vector__XXX
 SG_ MtrGnrtr6InvrtrLmtsAtvSpdMxmm : 36|12@1+ (0.0625,-125) [-125|125.9375] "%" Vector__XXX
 SG_ MtrGnrtr6InvrtrLmtsAtvSpdMnmm : 48|12@1+ (0.0625,-125) [-125|125.9375] "%" Vector__XXX
 SG_ MtrGnrtr6InvrtrLmtsAtvMhnlCr : 0|8@1+ (1,0) [0|250] "count" Vector__XXX

BO_ 2565997310 MG6ILADC: 8 Vector__XXX
 SG_ MtrGnrtr6InvrtrLmtsAtvDSdCr : 0|8@1+ (1,0) [0|250] "count" Vector__XXX
 SG_ MtrGnrtr6InvrtrLmtsAtvDSdCntr : 8|4@1+ (1,0) [0|15] "" Vector__XXX
 SG_ MtGt6IvtLtsAtvDSdVtMx : 12|12@1+ (0.0625,-125) [-125|125.9375] "%" Vector__XXX
 SG_ MtGt6IvtLtsAtvDSdVtM : 24|12@1+ (0.0625,-125) [-125|125.9375] "%" Vector__XXX
 SG_ MtGt6IvtLtsAtvDSdCtMx : 36|12@1+ (0.0625,-125) [-125|125.9375] "%" Vector__XXX
 SG_ MtGt6IvtLtsAtvDSdCtM : 48|12@1+ (0.0625,-125) [-125|125.9375] "%" Vector__XXX

BO_ 2565997566 MG6ILV: 8 Vector__XXX
 SG_ MtrGnrtr6InvrtrSwthdIgntnVltg : 0|16@1+ (0.05,0) [0|3212.75] "V" Vector__XXX
 SG_ MtrGnrtr6InvrtrUnswthdSlVltg : 16|16@1+ (0.05,0) [0|3212.75] "V" Vector__XXX

BO_ 2565997822 MG6IS2: 8 Vector__XXX
 SG_ MtrGnrtr6InvrtrStts2Cntr : 8|4@1+ (1,0) [0|15] "" Vector__XXX
 SG_ MtrGnrtr6AvllMxmmTrq : 12|12@1+ (0.0625,-125) [-125|125.9375] "%" Vector__XXX
 SG_ MtrGnrtr6AvllMnmmTrq : 24|12@1+ (0.0625,-125) [-125|125.9375] "%" Vector__XXX
 SG_ MtrGnrtr6InvrtrStts2Cr : 0|8@1+ (1,0) [0|250] "count" Vector__XXX

BO_ 2565998078 MG6IRLA1: 8 Vector__XXX
 SG_ MtrGnrtr6InvrtrRtLmtsAtv1Cntr : 8|4@1+ (1,0) [0|15] "" Vector__XXX
 SG_ MtGt6IvtRtLtsAtvAstSpdRtLt : 12|12@1+ (0.25,0) [0|1003.75] "%/s" Vector__XXX
 SG_ MtGt6IvtRtLtsAtvAstTqRtLt : 24|12@1+ (2,0) [0|8030] "%/s" Vector__XXX
 SG_ MtrGnrtr6InvrtrRtLmtsAtv1Cr : 0|8@1+ (1,0) [0|250] "count" Vector__XXX

BO_ 2364671742 BSD1: 8 Vector__XXX
 SG_ BlindSpotDetectionState : 0|4@1+ (1,0) [0|15] "" Vector__XXX
 SG_ BlindSpotCollisionWarningLevel : 4|4@1+ (1,0) [0|15] "" Vector__XXX
 SG_ BlndSptWrnngRlvntOjtDttd : 8|3@1+ (1,0) [0|7] "" Vector__XXX
 SG_ BlndSptDttnLftSdMntrd : 16|2@1+ (1,0) [0|3] "" Vector__XXX
 SG_ BlndSptDttnRghtSdMntrd : 18|2@1+ (1,0) [0|3] "" Vector__XXX
 SG_ BlndSptDttnFrntMntrd : 20|2@1+ (1,0) [0|3] "" Vector__XXX
 SG_ BlindSpotDetectionRearMonitored : 22|2@1+ (1,0) [0|3] "" Vector__XXX
 SG_ BndOffPrltOfMstImprtntOjt : 11|3@1+ (1,0) [0|7] "" Vector__XXX

BO_ 2364671998 WINCH1: 8 Vector__XXX
 SG_ WinchMotorEncoderPosition : 0|16@1+ (1,0) [0|32767] "count" Vector__XXX
 SG_ WinchRevolutionCounter : 16|16@1+ (1,-32128) [-32128|32127] "count" Vector__XXX
 SG_ WinchMotorSpeed : 32|16@1+ (0.125,0) [0|8031.875] "rpm" Vector__XXX
 SG_ WinchMotorDirection : 48|2@1+ (1,0) [0|3] "" Vector__XXX
 SG_ WinchMotorOverspeed : 50|2@1+ (1,0) [0|3] "" Vector__XXX

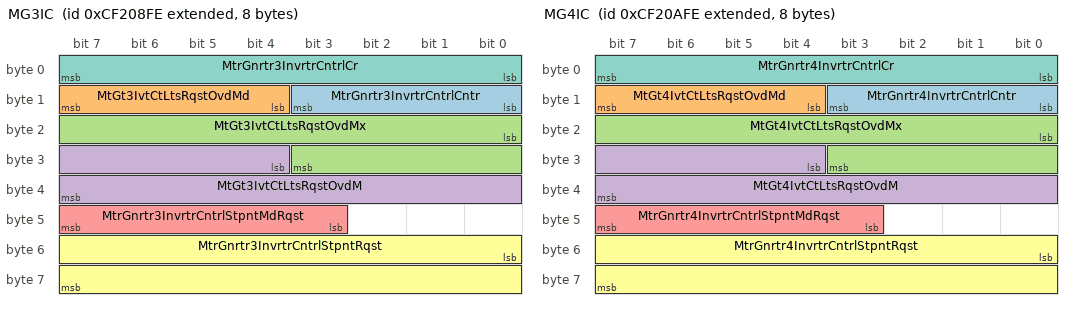
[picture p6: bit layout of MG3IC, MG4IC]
BO_ 2364672254 MG3IC: 8 Vector__XXX
 SG_ MtrGnrtr3InvrtrCntrlCntr : 8|4@1+ (1,0) [0|15] "" Vector__XXX
 SG_ MtGt3IvtCtLtsRqstOvdMd : 12|4@1+ (1,0) [0|15] "" Vector__XXX
 SG_ MtGt3IvtCtLtsRqstOvdMx : 16|12@1+ (0.0625,-125) [-125|125.9375] "%" Vector__XXX
 SG_ MtGt3IvtCtLtsRqstOvdM : 28|12@1+ (0.0625,-125) [-125|125.9375] "%" Vector__XXX
 SG_ MtrGnrtr3InvrtrCntrlStpntMdRqst : 43|5@1+ (1,0) [0|31] "" Vector__XXX
 SG_ MtrGnrtr3InvrtrCntrlStpntRqst : 48|16@1+ (0.00390625,-125) [-125|125.99609375] "%" Vector__XXX
 SG_ MtrGnrtr3InvrtrCntrlCr : 0|8@1+ (1,0) [0|250] "count" Vector__XXX

BO_ 2565999102 MG3IRLR1: 8 Vector__XXX
 SG_ MtrGnrtr3InvrtrRtLmtsRqst1Cntr : 8|4@1+ (1,0) [0|15] "" Vector__XXX
 SG_ MtGt3IvtRtLtsRqstAstSpdRtLt : 12|12@1+ (0.25,0) [0|1003.75] "%/s" Vector__XXX
 SG_ MtGt3IvtRtLtsRqstAstTqRtLt : 24|12@1+ (2,0) [0|8030] "%/s" Vector__XXX
 SG_ MtrGnrtr3InvrtrRtLmtsRqst1Cr : 0|8@1+ (1,0) [0|250] "count" Vector__XXX

BO_ 2364672766 MG4IC: 8 Vector__XXX
 SG_ MtrGnrtr4InvrtrCntrlCntr : 8|4@1+ (1,0) [0|15] "" Vector__XXX
 SG_ MtGt4IvtCtLtsRqstOvdMd : 12|4@1+ (1,0) [0|15] "" Vector__XXX
 SG_ MtGt4IvtCtLtsRqstOvdMx : 16|12@1+ (0.0625,-125) [-125|125.9375] "%" Vector__XXX
 SG_ MtGt4IvtCtLtsRqstOvdM : 28|12@1+ (0.0625,-125) [-125|125.9375] "%" Vector__XXX
 SG_ MtrGnrtr4InvrtrCntrlStpntMdRqst : 43|5@1+ (1,0) [0|31] "" Vector__XXX
 SG_ MtrGnrtr4InvrtrCntrlStpntRqst : 48|16@1+ (0.00390625,-125) [-125|125.99609375] "%" Vector__XXX
 SG_ MtrGnrtr4InvrtrCntrlCr : 0|8@1+ (1,0) [0|250] "count" Vector__XXX

BO_ 2565999614 MG4IRLR1: 8 Vector__XXX
 SG_ MtrGnrtr4InvrtrRtLmtsRqst1Cntr : 8|4@1+ (1,0) [0|15] "" Vector__XXX
 SG_ MtGt4IvtRtLtsRqstAstSpdRtLt : 12|12@1+ (0.25,0) [0|1003.75] "%/s" Vector__XXX
 SG_ MtGt4IvtRtLtsRqstAstTqRtLt : 24|12@1+ (2,0) [0|8030] "%/s" Vector__XXX
 SG_ MtrGnrtr4InvrtrRtLmtsRqst1Cr : 0|8@1+ (1,0) [0|250] "count" Vector__XXX

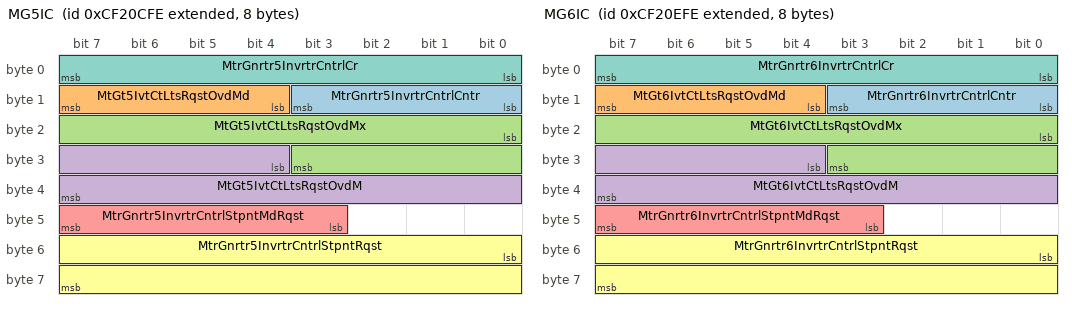
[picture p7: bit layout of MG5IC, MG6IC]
BO_ 2364673278 MG5IC: 8 Vector__XXX
 SG_ MtrGnrtr5InvrtrCntrlCntr : 8|4@1+ (1,0) [0|15] "" Vector__XXX
 SG_ MtGt5IvtCtLtsRqstOvdMd : 12|4@1+ (1,0) [0|15] "" Vector__XXX
 SG_ MtGt5IvtCtLtsRqstOvdMx : 16|12@1+ (0.0625,-125) [-125|125.9375] "%" Vector__XXX
 SG_ MtGt5IvtCtLtsRqstOvdM : 28|12@1+ (0.0625,-125) [-125|125.9375] "%" Vector__XXX
 SG_ MtrGnrtr5InvrtrCntrlStpntMdRqst : 43|5@1+ (1,0) [0|31] "" Vector__XXX
 SG_ MtrGnrtr5InvrtrCntrlStpntRqst : 48|16@1+ (0.00390625,-125) [-125|125.99609375] "%" Vector__XXX
 SG_ MtrGnrtr5InvrtrCntrlCr : 0|8@1+ (1,0) [0|250] "count" Vector__XXX

BO_ 2566000126 MG5IRLR1: 8 Vector__XXX
 SG_ MtrGnrtr5InvrtrRtLmtsRqst1Cntr : 8|4@1+ (1,0) [0|15] "" Vector__XXX
 SG_ MtGt5IvtRtLtsRqstAstSpdRtLt : 12|12@1+ (0.25,0) [0|1003.75] "%/s" Vector__XXX
 SG_ MtGt5IvtRtLtsRqstAstTqRtLt : 24|12@1+ (2,0) [0|8030] "%/s" Vector__XXX
 SG_ MtrGnrtr5InvrtrRtLmtsRqst1Cr : 0|8@1+ (1,0) [0|250] "count" Vector__XXX

BO_ 2364673790 MG6IC: 8 Vector__XXX
 SG_ MtrGnrtr6InvrtrCntrlCntr : 8|4@1+ (1,0) [0|15] "" Vector__XXX
 SG_ MtGt6IvtCtLtsRqstOvdMd : 12|4@1+ (1,0) [0|15] "" Vector__XXX
 SG_ MtGt6IvtCtLtsRqstOvdMx : 16|12@1+ (0.0625,-125) [-125|125.9375] "%" Vector__XXX
 SG_ MtGt6IvtCtLtsRqstOvdM : 28|12@1+ (0.0625,-125) [-125|125.9375] "%" Vector__XXX
 SG_ MtrGnrtr6InvrtrCntrlStpntMdRqst : 43|5@1+ (1,0) [0|31] "" Vector__XXX
 SG_ MtrGnrtr6InvrtrCntrlStpntRqst : 48|16@1+ (0.00390625,-125) [-125|125.99609375] "%" Vector__XXX
 SG_ MtrGnrtr6InvrtrCntrlCr : 0|8@1+ (1,0) [0|250] "count" Vector__XXX

BO_ 2566000638 MG6IRLR1: 8 Vector__XXX
 SG_ MtrGnrtr6InvrtrRtLmtsRqst1Cntr : 8|4@1+ (1,0) [0|15] "" Vector__XXX
 SG_ MtGt6IvtRtLtsRqstAstSpdRtLt : 12|12@1+ (0.25,0) [0|1003.75] "%/s" Vector__XXX
 SG_ MtGt6IvtRtLtsRqstAstTqRtLt : 24|12@1+ (2,0) [0|8030] "%/s" Vector__XXX
 SG_ MtrGnrtr6InvrtrRtLmtsRqst1Cr : 0|8@1+ (1,0) [0|250] "count" Vector__XXX

BO_ 2566574078 EVCCD1: 12 Vector__XXX
 SG_ EvccControlPilotMaximumVoltage : 0|16@1+ (0.05,-1606) [-1606|1606.75] "V" Vector__XXX
 SG_ EvccControlPilotMinimumVoltage : 16|16@1+ (0.05,-1606) [-1606|1606.75] "V" Vector__XXX
 SG_ EvccControlPilotPwmFrequency : 32|16@1+ (1,0) [0|64255] "Hz" Vector__XXX
 SG_ EvccControlPilotDutyCycle : 48|8@1+ (0.5,0) [0|100] "%" Vector__XXX
 SG_ EvccControlPilotState : 56|4@1+ (1,0) [0|15] "" Vector__XXX
 SG_ EvccControlPilotSubState : 60|4@1+ (1,0) [0|15] "" Vector__XXX
 SG_ EvccProximityCircuitVoltage : 64|16@1+ (0.01,0) [0|642.55] "V" Vector__XXX
 SG_ EvccInletConnectorTemperature : 80|8@1+ (1,-40) [-40|210] "degC" Vector__XXX
 SG_ EvccCompatibilityCode : 88|4@1+ (1,0) [0|15] "" Vector__XXX

BO_ 2499465470 CDC2: 8 Vector__XXX
 SG_ Mirror1LeftRightSelection : 0|3@1+ (1,0) [0|7] "" Vector__XXX
 SG_ Mirror2LeftRightSelection : 3|3@1+ (1,0) [0|7] "" Vector__XXX
 SG_ MirrorPrimarySecondarySelection : 8|3@1+ (1,0) [0|7] "" Vector__XXX

BO_ 2499465726 EAI2: 8 Vector__XXX
 SG_ EngnClndrTmprtrAvrg : 0|16@1+ (0.03125,-273) [-273|1734.96875] "degC" Vector__XXX
 SG_ EngnClndrBnk1TmprtrAvrg : 16|16@1+ (0.03125,-273) [-273|1734.96875] "degC" Vector__XXX
 SG_ EngnClndrBnk2TmprtrAvrg : 32|16@1+ (0.03125,-273) [-273|1734.96875] "degC" Vector__XXX

BO_ 2566574846 TCI81: 8 Vector__XXX
 SG_ EngnTrhrgr3OlTmprtr : 0|16@1+ (0.03125,-273) [-273|1734.96875] "degC" Vector__XXX
 SG_ EngnTrhrgr4OlTmprtr : 16|16@1+ (0.03125,-273) [-273|1734.96875] "degC" Vector__XXX
 SG_ EngnTrhrgr5OlTmprtr : 32|16@1+ (0.03125,-273) [-273|1734.96875] "degC" Vector__XXX
 SG_ EngnTrhrgr6OlTmprtr : 48|16@1+ (0.03125,-273) [-273|1734.96875] "degC" Vector__XXX

BO_ 2566575102 ADSC1: 8 Vector__XXX
 SG_ Ts1CntrlPrpsP7InhtCmmnd : 0|2@1+ (1,0) [0|3] "" Vector__XXX
 SG_ AdsVehicleSpeedControlConsent : 2|2@1+ (1,0) [0|3] "" Vector__XXX
 SG_ Adsc1EmbeddedIntegritySupport : 50|2@1+ (1,0) [0|3] "" Vector__XXX
 SG_ Adsc1Counter : 52|4@1+ (1,0) [0|15] "" Vector__XXX
 SG_ Adsc1Crc : 56|8@1+ (1,0) [0|250] "count" Vector__XXX

BO_ 2566575358 EVSEACS2: 8 Vector__XXX
 SG_ EvseAcRmsCurrent : 0|16@1+ (0.05,-1600) [-1600|1612.75] "A" Vector__XXX
 SG_ EvseAcRmsVoltage : 16|16@1+ (0.05,0) [0|3212.75] "V" Vector__XXX

BO_ 2566575614 EVSEACS1: 8 Vector__XXX
 SG_ EvseAcRmsCurrentLimitL1 : 0|16@1+ (0.0625,0) [0|4015.9375] "A" Vector__XXX
 SG_ EvseAcRmsCurrentLimitL2 : 16|16@1+ (0.0625,0) [0|4015.9375] "A" Vector__XXX
 SG_ EvseAcRmsCurrentLimitL3 : 32|16@1+ (0.0625,0) [0|4015.9375] "A" Vector__XXX
 SG_ EvseAcRmsCurrentLimitNeutral : 48|16@1+ (0.0625,0) [0|4015.9375] "A" Vector__XXX

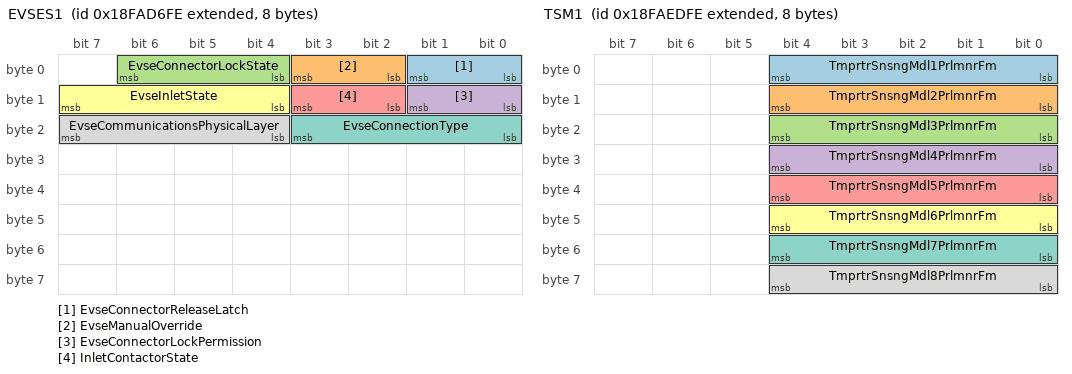
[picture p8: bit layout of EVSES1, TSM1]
BO_ 2566575870 EVSES1: 8 Vector__XXX
 SG_ EvseConnectorReleaseLatch : 0|2@1+ (1,0) [0|3] "" Vector__XXX
 SG_ EvseManualOverride : 2|2@1+ (1,0) [0|3] "" Vector__XXX
 SG_ EvseConnectorLockState : 4|3@1+ (1,0) [0|7] "" Vector__XXX
 SG_ EvseConnectorLockPermission : 8|2@1+ (1,0) [0|3] "" Vector__XXX
 SG_ InletContactorState : 10|2@1+ (1,0) [0|3] "" Vector__XXX
 SG_ EvseInletState : 12|4@1+ (1,0) [0|15] "" Vector__XXX
 SG_ EvseConnectionType : 16|4@1+ (1,0) [0|15] "" Vector__XXX
 SG_ EvseCommunicationsPhysicalLayer : 20|4@1+ (1,0) [0|15] "" Vector__XXX

BO_ 2566581758 TSM1: 8 Vector__XXX
 SG_ TmprtrSnsngMdl1PrlmnrFm : 0|5@1+ (1,0) [0|31] "" Vector__XXX
 SG_ TmprtrSnsngMdl2PrlmnrFm : 8|5@1+ (1,0) [0|31] "" Vector__XXX
 SG_ TmprtrSnsngMdl3PrlmnrFm : 16|5@1+ (1,0) [0|31] "" Vector__XXX
 SG_ TmprtrSnsngMdl4PrlmnrFm : 24|5@1+ (1,0) [0|31] "" Vector__XXX
 SG_ TmprtrSnsngMdl5PrlmnrFm : 32|5@1+ (1,0) [0|31] "" Vector__XXX
 SG_ TmprtrSnsngMdl6PrlmnrFm : 40|5@1+ (1,0) [0|31] "" Vector__XXX
 SG_ TmprtrSnsngMdl7PrlmnrFm : 48|5@1+ (1,0) [0|31] "" Vector__XXX
 SG_ TmprtrSnsngMdl8PrlmnrFm : 56|5@1+ (1,0) [0|31] "" Vector__XXX

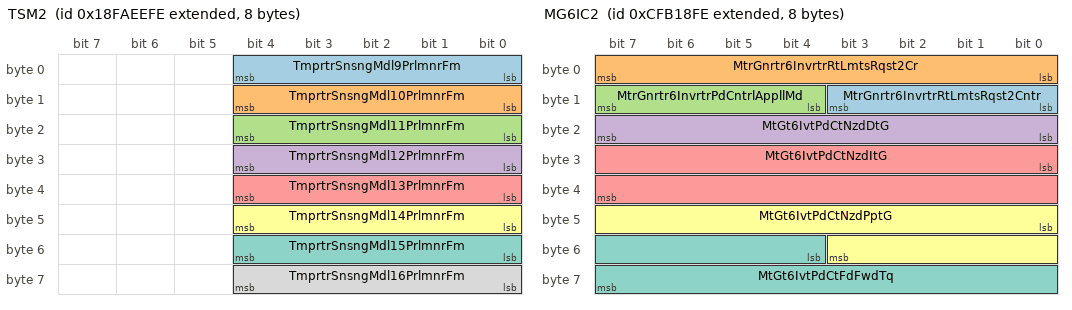
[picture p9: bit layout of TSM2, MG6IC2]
BO_ 2566582014 TSM2: 8 Vector__XXX
 SG_ TmprtrSnsngMdl9PrlmnrFm : 0|5@1+ (1,0) [0|31] "" Vector__XXX
 SG_ TmprtrSnsngMdl10PrlmnrFm : 8|5@1+ (1,0) [0|31] "" Vector__XXX
 SG_ TmprtrSnsngMdl11PrlmnrFm : 16|5@1+ (1,0) [0|31] "" Vector__XXX
 SG_ TmprtrSnsngMdl12PrlmnrFm : 24|5@1+ (1,0) [0|31] "" Vector__XXX
 SG_ TmprtrSnsngMdl13PrlmnrFm : 32|5@1+ (1,0) [0|31] "" Vector__XXX
 SG_ TmprtrSnsngMdl14PrlmnrFm : 40|5@1+ (1,0) [0|31] "" Vector__XXX
 SG_ TmprtrSnsngMdl15PrlmnrFm : 48|5@1+ (1,0) [0|31] "" Vector__XXX
 SG_ TmprtrSnsngMdl16PrlmnrFm : 56|5@1+ (1,0) [0|31] "" Vector__XXX

BO_ 2566582270 A2SCRSI3: 8 Vector__XXX
 SG_ Aftrtrtmnt2SrNrmlzdCnvrsnEffn : 0|8@1+ (0.4,0) [0|100] "%" Vector__XXX

BO_ 2566582526 A1SCRSI3: 8 Vector__XXX
 SG_ Aftrtrtmnt1SrNrmlzdCnvrsnEffn : 0|8@1+ (0.4,0) [0|100] "%" Vector__XXX
 SG_ Atttt1DsExstFdUsdTsOptC : 8|16@1+ (0.1,0) [0|6425.5] "l" Vector__XXX

BO_ 2566582782 PSATL: 12 Vector__XXX
 SG_ HrdLftmPrplsnSstmAtvTm : 0|32@1+ (1,0) [0|4211081215] "s" Vector__XXX
 SG_ HrdLftmIdlPrplsnSstmAtvTm : 32|32@1+ (1,0) [0|4211081215] "s" Vector__XXX
 SG_ HrdLftmUrnPrplsnSstmAtvTm : 64|32@1+ (1,0) [0|4211081215] "s" Vector__XXX

BO_ 2566583038 PSATS: 8 Vector__XXX
 SG_ HrdStrd100HrRntPrplsnSstmAtvTm : 0|16@1+ (10,0) [0|642550] "s" Vector__XXX
 SG_ HrdStrd100HrIdlPrplsnSstmAtvTm : 16|16@1+ (10,0) [0|642550] "s" Vector__XXX
 SG_ HrdStrd100HrUrnPrplsnSstmAtvTm : 32|16@1+ (10,0) [0|642550] "s" Vector__XXX

BO_ 2566583294 PSATA: 8 Vector__XXX
 SG_ HrdAtv100HrPrplsnSstmAtvTm : 0|16@1+ (10,0) [0|642550] "s" Vector__XXX
 SG_ HrdAtv100HrIdlPrplsnSstmAtvTm : 16|16@1+ (10,0) [0|642550] "s" Vector__XXX
 SG_ HrdAtv100HrUrnPrplsnSstmAtvTm : 32|16@1+ (10,0) [0|642550] "s" Vector__XXX

BO_ 2566583550 HCDIOL: 32 Vector__XXX
 SG_ HdLtDstTvdICDptOptWtEO : 0|32@1+ (5,0) [0|21055406075] "m" Vector__XXX
 SG_ HdLtDstTvdICDptOptWtER : 32|32@1+ (5,0) [0|21055406075] "m" Vector__XXX
 SG_ HdLtDstTvdIDvStCIsOpt : 64|32@1+ (5,0) [0|21055406075] "m" Vector__XXX
 SG_ HrdLftmFlCnsmdInChrgDpltngOprtn : 96|32@1+ (0.5,0) [0|2105540607.5] "l" Vector__XXX
 SG_ HdLtFCsdIDvStCIsOpt : 128|32@1+ (0.5,0) [0|2105540607.5] "l" Vector__XXX
 SG_ HdLtGdECsdICDptOptWtEO : 160|32@1+ (1,0) [0|4211081215] "kWh" Vector__XXX
 SG_ HdLtGdECsdICDptOptWtER : 192|32@1+ (1,0) [0|4211081215] "kWh" Vector__XXX
 SG_ HrdLftmGrdEnrgIntThBttr : 224|32@1+ (1,0) [0|4211081215] "kWh" Vector__XXX

BO_ 2566583806 HCDIOS: 16 Vector__XXX
 SG_ HdStd100HDstTvdICDptOptWtEO : 0|16@1+ (0.25,0) [0|16063.75] "km" Vector__XXX
 SG_ HdStd100HDstTvdICDptOptWtER : 16|16@1+ (0.25,0) [0|16063.75] "km" Vector__XXX
 SG_ HdStd100HDstTvdIDvStCIsOpt : 32|16@1+ (0.25,0) [0|16063.75] "km" Vector__XXX
 SG_ HdStd100HFCsdICDptOpt : 48|16@1+ (0.5,0) [0|32127.5] "l" Vector__XXX
 SG_ HdStd100HFCsdIDvStCIsOpt : 64|16@1+ (0.5,0) [0|32127.5] "l" Vector__XXX
 SG_ HdStd100HGdECsdICDptOptWtEO : 80|16@1+ (1,0) [0|64255] "kWh" Vector__XXX
 SG_ HdStd100HGdECsdICDptOptWtER : 96|16@1+ (1,0) [0|64255] "kWh" Vector__XXX
 SG_ HrdStrd100HrGrdEnrgIntThBttr : 112|16@1+ (1,0) [0|64255] "kWh" Vector__XXX

BO_ 2566584062 HCDIOA: 16 Vector__XXX
 SG_ HdAtv100HDstTvdICDptOptWtEO : 0|16@1+ (0.25,0) [0|16063.75] "km" Vector__XXX
 SG_ HdAtv100HDstTvdICDptOptWtER : 16|16@1+ (0.25,0) [0|16063.75] "km" Vector__XXX
 SG_ HdAtv100HDstTvdIDvStCIsOpt : 32|16@1+ (0.25,0) [0|16063.75] "km" Vector__XXX
 SG_ HdAtv100HFCsdICDptOpt : 48|16@1+ (0.5,0) [0|32127.5] "l" Vector__XXX
 SG_ HdAtv100HFCsdIDvStCIsOpt : 64|16@1+ (0.5,0) [0|32127.5] "l" Vector__XXX
 SG_ HdAtv100HGdECsdICDptOptWtEO : 80|16@1+ (1,0) [0|64255] "kWh" Vector__XXX
 SG_ HdAtv100HGdECsdICDptOptWtER : 96|16@1+ (1,0) [0|64255] "kWh" Vector__XXX
 SG_ HrdAtv100HrGrdEnrgIntThBttr : 112|16@1+ (1,0) [0|64255] "kWh" Vector__XXX

BO_ 2566584318 AT1HI3: 32 Vector__XXX
 SG_ Atttt1TtERtWtNDDv : 192|32@1+ (1,0) [0|4211081215] "s" Vector__XXX
 SG_ Atttt1DpRtCptSttEVDst1 : 0|32@1+ (5,0) [0|21055406075] "m" Vector__XXX
 SG_ Atttt1DpRtCptEdEVDst1 : 32|32@1+ (5,0) [0|21055406075] "m" Vector__XXX
 SG_ Atttt1DpRtCptSttEVDst2 : 64|32@1+ (5,0) [0|21055406075] "m" Vector__XXX
 SG_ Atttt1DpRtCptEdEVDst2 : 96|32@1+ (0.125,0) [0|526385151.875] "km" Vector__XXX
 SG_ Atttt1DpRtCptSttEVDst3 : 128|32@1+ (5,0) [0|21055406075] "m" Vector__XXX
 SG_ Atttt1DpRtCptEdEVDst3 : 160|32@1+ (5,0) [0|21055406075] "m" Vector__XXX
 SG_ Atttt1TtTSItTptBw200Css : 224|32@1+ (1,0) [0|4211081215] "s" Vector__XXX

BO_ 2566584830 ATNXMS2: 8 Vector__XXX
 SG_ Aftrtrtmnt1Sr2InltNxMssFlw : 0|16@1+ (0.0001,0) [0|6.4255] "g/s" Vector__XXX
 SG_ Aftrtrtmnt1Sr2OtltNxMssFlw : 16|16@1+ (0.0001,0) [0|6.4255] "g/s" Vector__XXX
 SG_ Aftrtrtmnt1Sr2MdldNh3StrgLvl : 32|16@1+ (1,0) [0|64255] "mg/l" Vector__XXX
 SG_ Aftrtrtmnt1Sr2TrgtNh3StrgLvl : 48|16@1+ (1,0) [0|64255] "mg/l" Vector__XXX

BO_ 2566585086 ATNXMS1: 8 Vector__XXX
 SG_ Aftrtrtmnt1Sr1EngnExhstNxMssFlw : 0|16@1+ (0.0001,0) [0|6.4255] "g/s" Vector__XXX
 SG_ Aftrtrtmnt1Sr1TlppNxMssFlw : 16|16@1+ (0.0001,0) [0|6.4255] "g/s" Vector__XXX
 SG_ Aftrtrtmnt1Sr1MdldAtlStrgLvl : 32|16@1+ (1,0) [0|64255] "mg/l" Vector__XXX
 SG_ Aftrtrtmnt1Sr1TrgtNh3StrgLvl : 48|16@1+ (1,0) [0|64255] "mg/l" Vector__XXX

BO_ 2566585342 EVAP1: 8 Vector__XXX
 SG_ EvapSystemPurgePressure : 0|16@1+ (4,0) [0|257020] "Pa" Vector__XXX
 SG_ EvapSystemVaporPressure : 16|16@1+ (4,0) [0|257020] "Pa" Vector__XXX
 SG_ EvapSystemPurgeValveCommand : 32|8@1+ (0.4,0) [0|100] "%" Vector__XXX
 SG_ EvapSystemPurgeValvePosition : 40|8@1+ (0.4,0) [0|100] "%" Vector__XXX

BO_ 2566585598 GHGTL: 52 Vector__XXX
 SG_ GhgTrkngLftmEngnRnTm : 0|32@1+ (1,0) [0|4211081215] "s" Vector__XXX
 SG_ GhgTrkngLftmVhlDstn : 32|32@1+ (5,0) [0|21055406075] "m" Vector__XXX
 SG_ GhgTrkngLftmVhlFlCnsmptn : 64|32@1+ (0.05,0) [0|210554060.75] "l" Vector__XXX
 SG_ GhgTrkngLftmEngnFlCnsmptn : 96|32@1+ (0.05,0) [0|210554060.75] "l" Vector__XXX
 SG_ GhgTrkngLftmEngnOtptEnrg : 128|32@1+ (1,0) [0|4211081215] "kWh" Vector__XXX
 SG_ GhgTrkngLftmPstvKntEnrgNmrtr : 160|32@1+ (5,0) [0|21055406075] "(km*km)/(h*h)" Vector__XXX
 SG_ GhgTrkngLftmUrnSpdRnTm : 192|32@1+ (1,0) [0|4211081215] "s" Vector__XXX
 SG_ GhgTrackingLifetimeIdleRunTime : 224|32@1+ (1,0) [0|4211081215] "s" Vector__XXX
 SG_ GhgTrkngLftmEngnIdlFlCnsmptn : 256|32@1+ (0.05,0) [0|210554060.75] "l" Vector__XXX
 SG_ GhgTrkngLftmEngnPwrTkOffRnTm : 288|32@1+ (1,0) [0|4211081215] "s" Vector__XXX
 SG_ GhgTrkngLftmStpStrtThnlgRnTm : 384|32@1+ (1,0) [0|4211081215] "s" Vector__XXX
 SG_ GTLtEPwTOFCspt : 320|32@1+ (0.05,0) [0|210554060.75] "l" Vector__XXX
 SG_ GTLtAttEStdwTAtvtCt : 352|32@1+ (1,0) [0|4211081215] "count" Vector__XXX

BO_ 2566585854 GHGTS1: 28 Vector__XXX
 SG_ GhgTrkngStrd100HrEngnRnTm : 0|16@1+ (10,0) [0|642550] "s" Vector__XXX
 SG_ GhgTrkngStrd100HrVhlDstn : 16|16@1+ (0.25,0) [0|16063.75] "km" Vector__XXX
 SG_ GhgTrkngStrd100HrVhlFlCnsmptn : 32|16@1+ (0.5,0) [0|32127.5] "l" Vector__XXX
 SG_ GhgTrkngStrd100HrEngnFlCnsmptn : 48|16@1+ (0.5,0) [0|32127.5] "l" Vector__XXX
 SG_ GhgTrkngStrd100HrEngnOtptEnrg : 64|16@1+ (1,0) [0|64255] "kWh" Vector__XXX
 SG_ GhgTrkngStrd100HrUrnSpdRnTm : 112|16@1+ (10,0) [0|642550] "s" Vector__XXX
 SG_ GhgTrkngStrd100HrIdlRnTm : 128|16@1+ (10,0) [0|642550] "s" Vector__XXX
 SG_ GTStd100HPstvKtENt : 80|32@1+ (1,0) [0|4211081215] "(km*km)/(h*h)" Vector__XXX
 SG_ GTStd100HEIdFCspt : 144|16@1+ (0.5,0) [0|32127.5] "l" Vector__XXX
 SG_ GTStd100HEPwTORT : 160|16@1+ (10,0) [0|642550] "s" Vector__XXX
 SG_ GTStd100HEPwTOFCspt : 176|16@1+ (0.5,0) [0|32127.5] "l" Vector__XXX
 SG_ GTStd100HAttEStdwTAtvtCt : 192|16@1+ (1,0) [0|64255] "count" Vector__XXX
 SG_ GTStd100HStpSttTRT : 208|16@1+ (10,0) [0|642550] "s" Vector__XXX

BO_ 2566586110 GHGTA1: 28 Vector__XXX
 SG_ GhgTrkngAtv100HrEngnRnTm : 0|16@1+ (10,0) [0|642550] "s" Vector__XXX
 SG_ GhgTrkngAtv100HrVhlDstn : 16|16@1+ (0.25,0) [0|16063.75] "km" Vector__XXX
 SG_ GhgTrkngAtv100HrVhlFlCnsmptn : 32|16@1+ (0.5,0) [0|32127.5] "l" Vector__XXX
 SG_ GhgTrkngAtv100HrEngnFlCnsmptn : 48|16@1+ (0.5,0) [0|32127.5] "l" Vector__XXX
 SG_ GhgTrkngAtv100HrEngnOtptEnrg : 64|16@1+ (1,0) [0|64255] "kWh" Vector__XXX
 SG_ GhgTrkngAtv100HrUrnSpdRnTm : 112|16@1+ (10,0) [0|642550] "s" Vector__XXX
 SG_ GhgTrkngAtv100HrIdlRnTm : 128|16@1+ (10,0) [0|642550] "s" Vector__XXX
 SG_ GTAtv100HPstvKtENt : 80|32@1+ (1,0) [0|4211081215] "(km*km)/(h*h)" Vector__XXX
 SG_ GTAtv100HEIdFCspt : 144|16@1+ (0.5,0) [0|32127.5] "l" Vector__XXX
 SG_ GTAtv100HEPwTORT : 160|16@1+ (10,0) [0|642550] "s" Vector__XXX
 SG_ GTAtv100HEPwTOFCspt : 176|16@1+ (0.5,0) [0|32127.5] "l" Vector__XXX
 SG_ GTAtv100HAttEStdwTAtvtCt : 192|16@1+ (1,0) [0|64255] "count" Vector__XXX
 SG_ GTAtv100HStpSttTRT : 208|16@1+ (10,0) [0|642550] "s" Vector__XXX

BO_ 2566587134 NTFCEA: 68 Vector__XXX
 SG_ NxTEAtvtLtFCsptB1Tt : 0|32@1+ (0.05,0) [0|210554060.75] "l" Vector__XXX
 SG_ NxTrkngEngnAtvtLftmFlCnsmptnBn2 : 32|32@1+ (0.05,0) [0|210554060.75] "l" Vector__XXX
 SG_ NxTrkngEngnAtvtLftmFlCnsmptnBn3 : 64|32@1+ (0.05,0) [0|210554060.75] "l" Vector__XXX
 SG_ NxTrkngEngnAtvtLftmFlCnsmptnBn4 : 96|32@1+ (0.05,0) [0|210554060.75] "l" Vector__XXX
 SG_ NxTrkngEngnAtvtLftmFlCnsmptnBn5 : 128|32@1+ (0.05,0) [0|210554060.75] "l" Vector__XXX
 SG_ NxTrkngEngnAtvtLftmFlCnsmptnBn6 : 160|32@1+ (0.05,0) [0|210554060.75] "l" Vector__XXX
 SG_ NxTrkngEngnAtvtLftmFlCnsmptnBn7 : 192|32@1+ (0.05,0) [0|210554060.75] "l" Vector__XXX
 SG_ NxTrkngEngnAtvtLftmFlCnsmptnBn8 : 224|32@1+ (0.05,0) [0|210554060.75] "l" Vector__XXX
 SG_ NxTrkngEngnAtvtLftmFlCnsmptnBn9 : 256|32@1+ (0.05,0) [0|210554060.75] "l" Vector__XXX
 SG_ NxTEAtvtLtFCsptB10 : 288|32@1+ (0.05,0) [0|210554060.75] "l" Vector__XXX
 SG_ NxTEAtvtLtFCsptB11 : 320|32@1+ (0.05,0) [0|210554060.75] "l" Vector__XXX
 SG_ NxTEAtvtLtFCsptB12 : 352|32@1+ (0.05,0) [0|210554060.75] "l" Vector__XXX
 SG_ NxTEAtvtLtFCsptB13 : 384|32@1+ (0.05,0) [0|210554060.75] "l" Vector__XXX
 SG_ NxTEAtvtLtFCsptB14 : 416|32@1+ (0.05,0) [0|210554060.75] "l" Vector__XXX
 SG_ NxTEAtvtLtFCsptB15NtB : 448|32@1+ (0.05,0) [0|210554060.75] "l" Vector__XXX
 SG_ NxTEAtvtLtFCsptB16RB : 480|32@1+ (0.05,0) [0|210554060.75] "l" Vector__XXX
 SG_ NxTEAtvtLtFCsptB17MOB : 512|32@1+ (0.05,0) [0|210554060.75] "l" Vector__XXX

BO_ 2566587390 NTEHEA: 68 Vector__XXX
 SG_ NxTEAtvtLtERTB1Tt : 0|32@1+ (1,0) [0|4211081215] "s" Vector__XXX
 SG_ NxTrkngEngnAtvtLftmEngnRnTmBn2 : 32|32@1+ (1,0) [0|4211081215] "s" Vector__XXX
 SG_ NxTrkngEngnAtvtLftmEngnRnTmBn3 : 64|32@1+ (1,0) [0|4211081215] "s" Vector__XXX
 SG_ NxTrkngEngnAtvtLftmEngnRnTmBn4 : 96|32@1+ (1,0) [0|4211081215] "s" Vector__XXX
 SG_ NxTrkngEngnAtvtLftmEngnRnTmBn5 : 128|32@1+ (1,0) [0|4211081215] "s" Vector__XXX
 SG_ NxTrkngEngnAtvtLftmEngnRnTmBn6 : 160|32@1+ (1,0) [0|4211081215] "s" Vector__XXX
 SG_ NxTrkngEngnAtvtLftmEngnRnTmBn7 : 192|32@1+ (1,0) [0|4211081215] "s" Vector__XXX
 SG_ NxTrkngEngnAtvtLftmEngnRnTmBn8 : 224|32@1+ (1,0) [0|4211081215] "s" Vector__XXX
 SG_ NxTrkngEngnAtvtLftmEngnRnTmBn9 : 256|32@1+ (1,0) [0|4211081215] "s" Vector__XXX
 SG_ NxTrkngEngnAtvtLftmEngnRnTmBn10 : 288|32@1+ (1,0) [0|4211081215] "s" Vector__XXX
 SG_ NxTrkngEngnAtvtLftmEngnRnTmBn11 : 320|32@1+ (1,0) [0|4211081215] "s" Vector__XXX
 SG_ NxTrkngEngnAtvtLftmEngnRnTmBn12 : 352|32@1+ (1,0) [0|4211081215] "s" Vector__XXX
 SG_ NxTrkngEngnAtvtLftmEngnRnTmBn13 : 384|32@1+ (1,0) [0|4211081215] "s" Vector__XXX
 SG_ NxTrkngEngnAtvtLftmEngnRnTmBn14 : 416|32@1+ (1,0) [0|4211081215] "s" Vector__XXX
 SG_ NxTEAtvtLtERTB15NtB : 448|32@1+ (1,0) [0|4211081215] "s" Vector__XXX
 SG_ NxTEAtvtLtERTB16RB : 480|32@1+ (1,0) [0|4211081215] "s" Vector__XXX
 SG_ NxTEAtvtLtERTB17MOB : 512|32@1+ (1,0) [0|4211081215] "s" Vector__XXX

BO_ 2566587646 NTVMEA: 68 Vector__XXX
 SG_ NxTEAtvtLtVDstB1Tt : 0|32@1+ (5,0) [0|21055406075] "m" Vector__XXX
 SG_ NxTrkngEngnAtvtLftmVhlDstnBn2 : 32|32@1+ (5,0) [0|21055406075] "m" Vector__XXX
 SG_ NxTrkngEngnAtvtLftmVhlDstnBn3 : 64|32@1+ (5,0) [0|21055406075] "m" Vector__XXX
 SG_ NxTrkngEngnAtvtLftmVhlDstnBn4 : 96|32@1+ (5,0) [0|21055406075] "m" Vector__XXX
 SG_ NxTrkngEngnAtvtLftmVhlDstnBn5 : 128|32@1+ (5,0) [0|21055406075] "m" Vector__XXX
 SG_ NxTrkngEngnAtvtLftmVhlDstnBn6 : 160|32@1+ (5,0) [0|21055406075] "m" Vector__XXX
 SG_ NxTrkngEngnAtvtLftmVhlDstnBn7 : 192|32@1+ (5,0) [0|21055406075] "m" Vector__XXX
 SG_ NxTrkngEngnAtvtLftmVhlDstnBn8 : 224|32@1+ (5,0) [0|21055406075] "m" Vector__XXX
 SG_ NxTrkngEngnAtvtLftmVhlDstnBn9 : 256|32@1+ (5,0) [0|21055406075] "m" Vector__XXX
 SG_ NxTrkngEngnAtvtLftmVhlDstnBn10 : 288|32@1+ (5,0) [0|21055406075] "m" Vector__XXX
 SG_ NxTrkngEngnAtvtLftmVhlDstnBn11 : 320|32@1+ (5,0) [0|21055406075] "m" Vector__XXX
 SG_ NxTrkngEngnAtvtLftmVhlDstnBn12 : 352|32@1+ (5,0) [0|21055406075] "m" Vector__XXX
 SG_ NxTrkngEngnAtvtLftmVhlDstnBn13 : 384|32@1+ (5,0) [0|21055406075] "m" Vector__XXX
 SG_ NxTrkngEngnAtvtLftmVhlDstnBn14 : 416|32@1+ (5,0) [0|21055406075] "m" Vector__XXX
 SG_ NxTEAtvtLtVDstB15NtB : 448|32@1+ (5,0) [0|21055406075] "m" Vector__XXX
 SG_ NxTEAtvtLtVDstB16RB : 480|32@1+ (5,0) [0|21055406075] "m" Vector__XXX
 SG_ NxTEAtvtLtVDstB17MOB : 512|32@1+ (5,0) [0|21055406075] "m" Vector__XXX

BO_ 2566587902 NTEEEA: 68 Vector__XXX
 SG_ NxTEAtvtLtEOtptEB1Tt : 0|32@1+ (1,0) [0|4211081215] "kWh" Vector__XXX
 SG_ NxTEAtvtLtEOtptEB2 : 32|32@1+ (1,0) [0|4211081215] "kWh" Vector__XXX
 SG_ NxTEAtvtLtEOtptEB3 : 64|32@1+ (1,0) [0|4211081215] "kWh" Vector__XXX
 SG_ NxTEAtvtLtEOtptEB4 : 96|32@1+ (1,0) [0|4211081215] "kWh" Vector__XXX
 SG_ NxTEAtvtLtEOtptEB5 : 128|32@1+ (1,0) [0|4211081215] "kWh" Vector__XXX
 SG_ NxTEAtvtLtEOtptEB6 : 160|32@1+ (1,0) [0|4211081215] "kWh" Vector__XXX
 SG_ NxTEAtvtLtEOtptEB7 : 192|32@1+ (1,0) [0|4211081215] "kWh" Vector__XXX
 SG_ NxTEAtvtLtEOtptEB8 : 224|32@1+ (1,0) [0|4211081215] "kWh" Vector__XXX
 SG_ NxTEAtvtLtEOtptEB9 : 256|32@1+ (1,0) [0|4211081215] "kWh" Vector__XXX
 SG_ NxTEAtvtLtEOtptEB10 : 288|32@1+ (1,0) [0|4211081215] "kWh" Vector__XXX
 SG_ NxTEAtvtLtEOtptEB11 : 320|32@1+ (1,0) [0|4211081215] "kWh" Vector__XXX
 SG_ NxTEAtvtLtEOtptEB12 : 352|32@1+ (1,0) [0|4211081215] "kWh" Vector__XXX
 SG_ NxTEAtvtLtEOtptEB13 : 384|32@1+ (1,0) [0|4211081215] "kWh" Vector__XXX
 SG_ NxTEAtvtLtEOtptEB14 : 416|32@1+ (1,0) [0|4211081215] "kWh" Vector__XXX
 SG_ NxTEAtvtLtEOtptEB15NtB : 448|32@1+ (1,0) [0|4211081215] "kWh" Vector__XXX
 SG_ NxTEAtvtLtEOtptEB16RB : 480|32@1+ (1,0) [0|4211081215] "kWh" Vector__XXX
 SG_ NxTEAtvtLtEOtptEB17MOB : 512|32@1+ (1,0) [0|4211081215] "kWh" Vector__XXX

BO_ 2566588158 NTFCV: 68 Vector__XXX
 SG_ NxTrkngVldNxLftmFlCnsmptnBn1Ttl : 0|32@1+ (0.05,0) [0|210554060.75] "l" Vector__XXX
 SG_ NxTrkngVldNxLftmFlCnsmptnBn2 : 32|32@1+ (0.05,0) [0|210554060.75] "l" Vector__XXX
 SG_ NxTrkngVldNxLftmFlCnsmptnBn3 : 64|32@1+ (0.05,0) [0|210554060.75] "l" Vector__XXX
 SG_ NxTrkngVldNxLftmFlCnsmptnBn4 : 96|32@1+ (0.05,0) [0|210554060.75] "l" Vector__XXX
 SG_ NxTrkngVldNxLftmFlCnsmptnBn5 : 128|32@1+ (0.05,0) [0|210554060.75] "l" Vector__XXX
 SG_ NxTrkngVldNxLftmFlCnsmptnBn6 : 160|32@1+ (0.05,0) [0|210554060.75] "l" Vector__XXX
 SG_ NxTrkngVldNxLftmFlCnsmptnBn7 : 192|32@1+ (0.05,0) [0|210554060.75] "l" Vector__XXX
 SG_ NxTrkngVldNxLftmFlCnsmptnBn8 : 224|32@1+ (0.05,0) [0|210554060.75] "l" Vector__XXX
 SG_ NxTrkngVldNxLftmFlCnsmptnBn9 : 256|32@1+ (0.05,0) [0|210554060.75] "l" Vector__XXX
 SG_ NxTrkngVldNxLftmFlCnsmptnBn10 : 288|32@1+ (0.05,0) [0|210554060.75] "l" Vector__XXX
 SG_ NxTrkngVldNxLftmFlCnsmptnBn11 : 320|32@1+ (0.05,0) [0|210554060.75] "l" Vector__XXX
 SG_ NxTrkngVldNxLftmFlCnsmptnBn12 : 352|32@1+ (0.05,0) [0|210554060.75] "l" Vector__XXX
 SG_ NxTrkngVldNxLftmFlCnsmptnBn13 : 384|32@1+ (0.05,0) [0|210554060.75] "l" Vector__XXX
 SG_ NxTrkngVldNxLftmFlCnsmptnBn14 : 416|32@1+ (0.05,0) [0|210554060.75] "l" Vector__XXX
 SG_ NxTVdNxLtFCsptB15NtB : 448|32@1+ (0.05,0) [0|210554060.75] "l" Vector__XXX
 SG_ NxTVdNxLtFCsptB16RB : 480|32@1+ (0.05,0) [0|210554060.75] "l" Vector__XXX
 SG_ NxTVdNxLtFCsptB17MOB : 512|32@1+ (0.05,0) [0|210554060.75] "l" Vector__XXX

BO_ 2566588414 NTEHV: 68 Vector__XXX
 SG_ NxTrkngVldNxLftmEngnRnTmBn1Ttl : 0|32@1+ (1,0) [0|4211081215] "s" Vector__XXX
 SG_ NxTrkngVldNxLftmEngnRnTmBn2 : 32|32@1+ (1,0) [0|4211081215] "s" Vector__XXX
 SG_ NxTrkngVldNxLftmEngnRnTmBn3 : 64|32@1+ (1,0) [0|4211081215] "s" Vector__XXX
 SG_ NxTrkngVldNxLftmEngnRnTmBn4 : 96|32@1+ (1,0) [0|4211081215] "s" Vector__XXX
 SG_ NxTrkngVldNxLftmEngnRnTmBn5 : 128|32@1+ (1,0) [0|4211081215] "s" Vector__XXX
 SG_ NxTrkngVldNxLftmEngnRnTmBn6 : 160|32@1+ (1,0) [0|4211081215] "s" Vector__XXX
 SG_ NxTrkngVldNxLftmEngnRnTmBn7 : 192|32@1+ (1,0) [0|4211081215] "s" Vector__XXX
 SG_ NxTrkngVldNxLftmEngnRnTmBn8 : 224|32@1+ (1,0) [0|4211081215] "s" Vector__XXX
 SG_ NxTrkngVldNxLftmEngnRnTmBn9 : 256|32@1+ (1,0) [0|4211081215] "s" Vector__XXX
 SG_ NxTrkngVldNxLftmEngnRnTmBn10 : 288|32@1+ (1,0) [0|4211081215] "s" Vector__XXX
 SG_ NxTrkngVldNxLftmEngnRnTmBn11 : 320|32@1+ (1,0) [0|4211081215] "s" Vector__XXX
 SG_ NxTrkngVldNxLftmEngnRnTmBn12 : 352|32@1+ (1,0) [0|4211081215] "s" Vector__XXX
 SG_ NxTrkngVldNxLftmEngnRnTmBn13 : 384|32@1+ (1,0) [0|4211081215] "s" Vector__XXX
 SG_ NxTrkngVldNxLftmEngnRnTmBn14 : 416|32@1+ (1,0) [0|4211081215] "s" Vector__XXX
 SG_ NxTVdNxLtERTB15NtB : 448|32@1+ (1,0) [0|4211081215] "s" Vector__XXX
 SG_ NxTVdNxLtERTB16RB : 480|32@1+ (1,0) [0|4211081215] "s" Vector__XXX
 SG_ NxTVdNxLtERTB17MOB : 512|32@1+ (1,0) [0|4211081215] "s" Vector__XXX

BO_ 2566588670 NTVMV: 68 Vector__XXX
 SG_ NxTrkngVldNxLftmVhlDstnBn1Ttl : 0|32@1+ (5,0) [0|21055406075] "m" Vector__XXX
 SG_ NxTrkngVldNxLftmVhlDstnBn2 : 32|32@1+ (5,0) [0|21055406075] "m" Vector__XXX
 SG_ NxTrkngVldNxLftmVhlDstnBn3 : 64|32@1+ (5,0) [0|21055406075] "m" Vector__XXX
 SG_ NxTrkngVldNxLftmVhlDstnBn4 : 96|32@1+ (5,0) [0|21055406075] "m" Vector__XXX
 SG_ NxTrkngVldNxLftmVhlDstnBn5 : 128|32@1+ (5,0) [0|21055406075] "m" Vector__XXX
 SG_ NxTrkngVldNxLftmVhlDstnBn6 : 160|32@1+ (5,0) [0|21055406075] "m" Vector__XXX
 SG_ NxTrkngVldNxLftmVhlDstnBn7 : 192|32@1+ (5,0) [0|21055406075] "m" Vector__XXX
 SG_ NxTrkngVldNxLftmVhlDstnBn8 : 224|32@1+ (5,0) [0|21055406075] "m" Vector__XXX
 SG_ NxTrkngVldNxLftmVhlDstnBn9 : 256|32@1+ (5,0) [0|21055406075] "m" Vector__XXX
 SG_ NxTrkngVldNxLftmVhlDstnBn10 : 288|32@1+ (5,0) [0|21055406075] "m" Vector__XXX
 SG_ NxTrkngVldNxLftmVhlDstnBn11 : 320|32@1+ (5,0) [0|21055406075] "m" Vector__XXX
 SG_ NxTrkngVldNxLftmVhlDstnBn12 : 352|32@1+ (5,0) [0|21055406075] "m" Vector__XXX
 SG_ NxTrkngVldNxLftmVhlDstnBn13 : 384|32@1+ (5,0) [0|21055406075] "m" Vector__XXX
 SG_ NxTrkngVldNxLftmVhlDstnBn14 : 416|32@1+ (5,0) [0|21055406075] "m" Vector__XXX
 SG_ NxTrkngVldNxLftmVhlDstnBn15NtBn : 448|32@1+ (5,0) [0|21055406075] "m" Vector__XXX
 SG_ NxTVdNxLtVDstB16RB : 480|32@1+ (5,0) [0|21055406075] "m" Vector__XXX
 SG_ NxTVdNxLtVDstB17MOB : 512|32@1+ (5,0) [0|21055406075] "m" Vector__XXX

BO_ 2566588926 NTEEV: 68 Vector__XXX
 SG_ NxTVdNxLtEOtptEB1Tt : 0|32@1+ (1,0) [0|4211081215] "kWh" Vector__XXX
 SG_ NxTrkngVldNxLftmEngnOtptEnrgBn2 : 32|32@1+ (1,0) [0|4211081215] "kWh" Vector__XXX
 SG_ NxTrkngVldNxLftmEngnOtptEnrgBn3 : 64|32@1+ (1,0) [0|4211081215] "kWh" Vector__XXX
 SG_ NxTrkngVldNxLftmEngnOtptEnrgBn4 : 96|32@1+ (1,0) [0|4211081215] "kWh" Vector__XXX
 SG_ NxTrkngVldNxLftmEngnOtptEnrgBn5 : 128|32@1+ (1,0) [0|4211081215] "kWh" Vector__XXX
 SG_ NxTrkngVldNxLftmEngnOtptEnrgBn6 : 160|32@1+ (1,0) [0|4211081215] "kWh" Vector__XXX
 SG_ NxTrkngVldNxLftmEngnOtptEnrgBn7 : 192|32@1+ (1,0) [0|4211081215] "kWh" Vector__XXX
 SG_ NxTrkngVldNxLftmEngnOtptEnrgBn8 : 224|32@1+ (1,0) [0|4211081215] "kWh" Vector__XXX
 SG_ NxTrkngVldNxLftmEngnOtptEnrgBn9 : 256|32@1+ (1,0) [0|4211081215] "kWh" Vector__XXX
 SG_ NxTVdNxLtEOtptEB10 : 288|32@1+ (1,0) [0|4211081215] "kWh" Vector__XXX
 SG_ NxTVdNxLtEOtptEB11 : 320|32@1+ (1,0) [0|4211081215] "kWh" Vector__XXX
 SG_ NxTVdNxLtEOtptEB12 : 352|32@1+ (1,0) [0|4211081215] "kWh" Vector__XXX
 SG_ NxTVdNxLtEOtptEB13 : 384|32@1+ (1,0) [0|4211081215] "kWh" Vector__XXX
 SG_ NxTVdNxLtEOtptEB14 : 416|32@1+ (1,0) [0|4211081215] "kWh" Vector__XXX
 SG_ NxTVdNxLtEOtptEB15NtB : 448|32@1+ (1,0) [0|4211081215] "kWh" Vector__XXX
 SG_ NxTVdNxLtEOtptEB16RB : 480|32@1+ (1,0) [0|4211081215] "kWh" Vector__XXX
 SG_ NxTVdNxLtEOtptEB17MOB : 512|32@1+ (1,0) [0|4211081215] "kWh" Vector__XXX

BO_ 2566589182 NTENV: 68 Vector__XXX
 SG_ NxTVdNxLtEOtNxMssB1Tt : 0|32@1+ (1,0) [0|4211081215] "g" Vector__XXX
 SG_ NxTrkngVldNxLftmEngnOtNxMssBn2 : 32|32@1+ (1,0) [0|4211081215] "g" Vector__XXX
 SG_ NxTrkngVldNxLftmEngnOtNxMssBn3 : 64|32@1+ (1,0) [0|4211081215] "g" Vector__XXX
 SG_ NxTrkngVldNxLftmEngnOtNxMssBn4 : 96|32@1+ (1,0) [0|4211081215] "g" Vector__XXX
 SG_ NxTrkngVldNxLftmEngnOtNxMssBn5 : 128|32@1+ (1,0) [0|4211081215] "g" Vector__XXX
 SG_ NxTrkngVldNxLftmEngnOtNxMssBn6 : 160|32@1+ (1,0) [0|4211081215] "g" Vector__XXX
 SG_ NxTrkngVldNxLftmEngnOtNxMssBn7 : 192|32@1+ (1,0) [0|4211081215] "g" Vector__XXX
 SG_ NxTrkngVldNxLftmEngnOtNxMssBn8 : 224|32@1+ (1,0) [0|4211081215] "g" Vector__XXX
 SG_ NxTrkngVldNxLftmEngnOtNxMssBn9 : 256|32@1+ (1,0) [0|4211081215] "g" Vector__XXX
 SG_ NxTrkngVldNxLftmEngnOtNxMssBn10 : 288|32@1+ (1,0) [0|4211081215] "g" Vector__XXX
 SG_ NxTrkngVldNxLftmEngnOtNxMssBn11 : 320|32@1+ (1,0) [0|4211081215] "g" Vector__XXX
 SG_ NxTrkngVldNxLftmEngnOtNxMssBn12 : 352|32@1+ (1,0) [0|4211081215] "g" Vector__XXX
 SG_ NxTrkngVldNxLftmEngnOtNxMssBn13 : 384|32@1+ (1,0) [0|4211081215] "g" Vector__XXX
 SG_ NxTrkngVldNxLftmEngnOtNxMssBn14 : 416|32@1+ (1,0) [0|4211081215] "g" Vector__XXX
 SG_ NxTVdNxLtEOtNxMssB15NtB : 448|32@1+ (1,0) [0|4211081215] "g" Vector__XXX
 SG_ NxTVdNxLtEOtNxMssB16RB : 480|32@1+ (1,0) [0|4211081215] "g" Vector__XXX
 SG_ NxTVdNxLtEOtNxMssB17MOB : 512|32@1+ (1,0) [0|4211081215] "g" Vector__XXX

BO_ 2566589438 NTSNV: 68 Vector__XXX
 SG_ NxTVdNxLtSstOtNxMssB1Tt : 0|32@1+ (1,0) [0|4211081215] "g" Vector__XXX
 SG_ NxTrkngVldNxLftmSstmOtNxMssBn2 : 32|32@1+ (1,0) [0|4211081215] "g" Vector__XXX
 SG_ NxTrkngVldNxLftmSstmOtNxMssBn3 : 64|32@1+ (1,0) [0|4211081215] "g" Vector__XXX
 SG_ NxTrkngVldNxLftmSstmOtNxMssBn4 : 96|32@1+ (1,0) [0|4211081215] "g" Vector__XXX
 SG_ NxTrkngVldNxLftmSstmOtNxMssBn5 : 128|32@1+ (1,0) [0|4211081215] "g" Vector__XXX
 SG_ NxTrkngVldNxLftmSstmOtNxMssBn6 : 160|32@1+ (1,0) [0|4211081215] "g" Vector__XXX
 SG_ NxTrkngVldNxLftmSstmOtNxMssBn7 : 192|32@1+ (1,0) [0|4211081215] "g" Vector__XXX
 SG_ NxTrkngVldNxLftmSstmOtNxMssBn8 : 224|32@1+ (1,0) [0|4211081215] "g" Vector__XXX
 SG_ NxTrkngVldNxLftmSstmOtNxMssBn9 : 256|32@1+ (1,0) [0|4211081215] "g" Vector__XXX
 SG_ NxTrkngVldNxLftmSstmOtNxMssBn10 : 288|32@1+ (1,0) [0|4211081215] "g" Vector__XXX
 SG_ NxTrkngVldNxLftmSstmOtNxMssBn11 : 320|32@1+ (1,0) [0|4211081215] "g" Vector__XXX
 SG_ NxTrkngVldNxLftmSstmOtNxMssBn12 : 352|32@1+ (1,0) [0|4211081215] "g" Vector__XXX
 SG_ NxTrkngVldNxLftmSstmOtNxMssBn13 : 384|32@1+ (1,0) [0|4211081215] "g" Vector__XXX
 SG_ NxTrkngVldNxLftmSstmOtNxMssBn14 : 416|32@1+ (1,0) [0|4211081215] "g" Vector__XXX
 SG_ NxTVdNxLtSstOtNxMssB15NtB : 448|32@1+ (1,0) [0|4211081215] "g" Vector__XXX
 SG_ NxTVdNxLtSstOtNxMssB16RB : 480|32@1+ (1,0) [0|4211081215] "g" Vector__XXX
 SG_ NxTVdNxLtSstOtNxMssB17MOB : 512|32@1+ (1,0) [0|4211081215] "g" Vector__XXX

BO_ 2566589694 NTFCS: 34 Vector__XXX
 SG_ NxTrkngStrd100HrFlCnsmptnBn1Ttl : 0|16@1+ (0.5,0) [0|32127.5] "l" Vector__XXX
 SG_ NxTrkngStrd100HrFlCnsmptnBn2 : 16|16@1+ (0.5,0) [0|32127.5] "l" Vector__XXX
 SG_ NxTrkngStrd100HrFlCnsmptnBn3 : 32|16@1+ (0.5,0) [0|32127.5] "l" Vector__XXX
 SG_ NxTrkngStrd100HrFlCnsmptnBn4 : 48|16@1+ (0.5,0) [0|32127.5] "l" Vector__XXX
 SG_ NxTrkngStrd100HrFlCnsmptnBn5 : 64|16@1+ (0.5,0) [0|32127.5] "l" Vector__XXX
 SG_ NxTrkngStrd100HrFlCnsmptnBn6 : 80|16@1+ (0.5,0) [0|32127.5] "l" Vector__XXX
 SG_ NxTrkngStrd100HrFlCnsmptnBn7 : 96|16@1+ (0.5,0) [0|32127.5] "l" Vector__XXX
 SG_ NxTrkngStrd100HrFlCnsmptnBn8 : 112|16@1+ (0.5,0) [0|32127.5] "l" Vector__XXX
 SG_ NxTrkngStrd100HrFlCnsmptnBn9 : 128|16@1+ (0.5,0) [0|32127.5] "l" Vector__XXX
 SG_ NxTrkngStrd100HrFlCnsmptnBn10 : 144|16@1+ (0.5,0) [0|32127.5] "l" Vector__XXX
 SG_ NxTrkngStrd100HrFlCnsmptnBn11 : 160|16@1+ (0.5,0) [0|32127.5] "l" Vector__XXX
 SG_ NxTrkngStrd100HrFlCnsmptnBn12 : 176|16@1+ (0.5,0) [0|32127.5] "l" Vector__XXX
 SG_ NxTrkngStrd100HrFlCnsmptnBn13 : 192|16@1+ (0.5,0) [0|32127.5] "l" Vector__XXX
 SG_ NxTrkngStrd100HrFlCnsmptnBn14 : 208|16@1+ (0.5,0) [0|32127.5] "l" Vector__XXX
 SG_ NxTStd100HFCsptB15NtB : 224|16@1+ (0.5,0) [0|32127.5] "l" Vector__XXX
 SG_ NxTStd100HFCsptB16RB : 240|16@1+ (0.5,0) [0|32127.5] "l" Vector__XXX
 SG_ NxTStd100HFCsptB17MOB : 256|16@1+ (0.5,0) [0|32127.5] "l" Vector__XXX

BO_ 2566589950 NTEHS: 34 Vector__XXX
 SG_ NxTrkngStrd100HrEngnRnTmBn1Ttl : 0|16@1+ (10,0) [0|642550] "s" Vector__XXX
 SG_ NxTrkngStrd100HrEngnRnTmBn2 : 16|16@1+ (10,0) [0|642550] "s" Vector__XXX
 SG_ NxTrkngStrd100HrEngnRnTmBn3 : 32|16@1+ (10,0) [0|642550] "s" Vector__XXX
 SG_ NxTrkngStrd100HrEngnRnTmBn4 : 48|16@1+ (10,0) [0|642550] "s" Vector__XXX
 SG_ NxTrkngStrd100HrEngnRnTmBn5 : 64|16@1+ (10,0) [0|642550] "s" Vector__XXX
 SG_ NxTrkngStrd100HrEngnRnTmBn6 : 80|16@1+ (10,0) [0|642550] "s" Vector__XXX
 SG_ NxTrkngStrd100HrEngnRnTmBn7 : 96|16@1+ (10,0) [0|642550] "s" Vector__XXX
 SG_ NxTrkngStrd100HrEngnRnTmBn8 : 112|16@1+ (10,0) [0|642550] "s" Vector__XXX
 SG_ NxTrkngStrd100HrEngnRnTmBn9 : 128|16@1+ (10,0) [0|642550] "s" Vector__XXX
 SG_ NxTrkngStrd100HrEngnRnTmBn10 : 144|16@1+ (10,0) [0|642550] "s" Vector__XXX
 SG_ NxTrkngStrd100HrEngnRnTmBn11 : 160|16@1+ (10,0) [0|642550] "s" Vector__XXX
 SG_ NxTrkngStrd100HrEngnRnTmBn12 : 176|16@1+ (10,0) [0|642550] "s" Vector__XXX
 SG_ NxTrkngStrd100HrEngnRnTmBn13 : 192|16@1+ (10,0) [0|642550] "s" Vector__XXX
 SG_ NxTrkngStrd100HrEngnRnTmBn14 : 208|16@1+ (10,0) [0|642550] "s" Vector__XXX
 SG_ NxTStd100HERTB15NtB : 224|16@1+ (10,0) [0|642550] "s" Vector__XXX
 SG_ NxTStd100HERTB16RB : 240|16@1+ (10,0) [0|642550] "s" Vector__XXX
 SG_ NxTStd100HERTB17MOB : 256|16@1+ (10,0) [0|642550] "s" Vector__XXX

BO_ 2566590206 NTVMS: 34 Vector__XXX
 SG_ NxTrkngStrd100HrVhlDstnBn1Ttl : 0|16@1+ (0.25,0) [0|16063.75] "km" Vector__XXX
 SG_ NxTrkngStrd100HrVhlDstnBn2 : 16|16@1+ (0.25,0) [0|16063.75] "km" Vector__XXX
 SG_ NxTrkngStrd100HrVhlDstnBn3 : 32|16@1+ (0.25,0) [0|16063.75] "km" Vector__XXX
 SG_ NxTrkngStrd100HrVhlDstnBn4 : 48|16@1+ (0.25,0) [0|16063.75] "km" Vector__XXX
 SG_ NxTrkngStrd100HrVhlDstnBn5 : 64|16@1+ (0.25,0) [0|16063.75] "km" Vector__XXX
 SG_ NxTrkngStrd100HrVhlDstnBn6 : 80|16@1+ (0.25,0) [0|16063.75] "km" Vector__XXX
 SG_ NxTrkngStrd100HrVhlDstnBn7 : 96|16@1+ (0.25,0) [0|16063.75] "km" Vector__XXX
 SG_ NxTrkngStrd100HrVhlDstnBn8 : 112|16@1+ (0.25,0) [0|16063.75] "km" Vector__XXX
 SG_ NxTrkngStrd100HrVhlDstnBn9 : 128|16@1+ (0.25,0) [0|16063.75] "km" Vector__XXX
 SG_ NxTrkngStrd100HrVhlDstnBn10 : 144|16@1+ (0.25,0) [0|16063.75] "km" Vector__XXX
 SG_ NxTrkngStrd100HrVhlDstnBn11 : 160|16@1+ (0.25,0) [0|16063.75] "km" Vector__XXX
 SG_ NxTrkngStrd100HrVhlDstnBn12 : 176|16@1+ (0.25,0) [0|16063.75] "km" Vector__XXX
 SG_ NxTrkngStrd100HrVhlDstnBn13 : 192|16@1+ (0.25,0) [0|16063.75] "km" Vector__XXX
 SG_ NxTrkngStrd100HrVhlDstnBn14 : 208|16@1+ (0.25,0) [0|16063.75] "km" Vector__XXX
 SG_ NxTrkngStrd100HrVhlDstnBn15NtBn : 224|16@1+ (0.25,0) [0|16063.75] "km" Vector__XXX
 SG_ NxTStd100HVDstB16RB : 240|16@1+ (0.25,0) [0|16063.75] "km" Vector__XXX
 SG_ NxTStd100HVDstB17MOB : 256|16@1+ (0.25,0) [0|16063.75] "km" Vector__XXX

BO_ 2566590462 NTEES: 34 Vector__XXX
 SG_ NxTStd100HEOtptEB1Tt : 0|16@1+ (1,0) [0|64255] "kWh" Vector__XXX
 SG_ NxTrkngStrd100HrEngnOtptEnrgBn2 : 16|16@1+ (1,0) [0|64255] "kWh" Vector__XXX
 SG_ NxTrkngStrd100HrEngnOtptEnrgBn3 : 32|16@1+ (1,0) [0|64255] "kWh" Vector__XXX
 SG_ NxTrkngStrd100HrEngnOtptEnrgBn4 : 48|16@1+ (1,0) [0|64255] "kWh" Vector__XXX
 SG_ NxTrkngStrd100HrEngnOtptEnrgBn5 : 64|16@1+ (1,0) [0|64255] "kWh" Vector__XXX
 SG_ NxTrkngStrd100HrEngnOtptEnrgBn6 : 80|16@1+ (1,0) [0|64255] "kWh" Vector__XXX
 SG_ NxTrkngStrd100HrEngnOtptEnrgBn7 : 96|16@1+ (1,0) [0|64255] "kWh" Vector__XXX
 SG_ NxTrkngStrd100HrEngnOtptEnrgBn8 : 112|16@1+ (1,0) [0|64255] "kWh" Vector__XXX
 SG_ NxTrkngStrd100HrEngnOtptEnrgBn9 : 128|16@1+ (1,0) [0|64255] "kWh" Vector__XXX
 SG_ NxTStd100HEOtptEB10 : 144|16@1+ (1,0) [0|64255] "kWh" Vector__XXX
 SG_ NxTStd100HEOtptEB11 : 160|16@1+ (1,0) [0|64255] "kWh" Vector__XXX
 SG_ NxTStd100HEOtptEB12 : 176|16@1+ (1,0) [0|64255] "kWh" Vector__XXX
 SG_ NxTStd100HEOtptEB13 : 192|16@1+ (1,0) [0|64255] "kWh" Vector__XXX
 SG_ NxTStd100HEOtptEB14 : 208|16@1+ (1,0) [0|64255] "kWh" Vector__XXX
 SG_ NxTStd100HEOtptEB15NtB : 224|16@1+ (1,0) [0|64255] "kWh" Vector__XXX
 SG_ NxTStd100HEOtptEB16RB : 240|16@1+ (1,0) [0|64255] "kWh" Vector__XXX
 SG_ NxTStd100HEOtptEB17MOB : 256|16@1+ (1,0) [0|64255] "kWh" Vector__XXX

BO_ 2566590718 NTENS: 68 Vector__XXX
 SG_ NxTStd100HEOtNxMssB1Tt : 0|32@1+ (0.0005,0) [0|2105540.6075] "g" Vector__XXX
 SG_ NxTrkngStrd100HrEngnOtNxMssBn2 : 32|32@1+ (0.0005,0) [0|2105540.6075] "g" Vector__XXX
 SG_ NxTrkngStrd100HrEngnOtNxMssBn3 : 64|32@1+ (0.0005,0) [0|2105540.6075] "g" Vector__XXX
 SG_ NxTrkngStrd100HrEngnOtNxMssBn4 : 96|32@1+ (0.0005,0) [0|2105540.6075] "g" Vector__XXX
 SG_ NxTrkngStrd100HrEngnOtNxMssBn5 : 128|32@1+ (0.0005,0) [0|2105540.6075] "g" Vector__XXX
 SG_ NxTrkngStrd100HrEngnOtNxMssBn6 : 160|32@1+ (0.0005,0) [0|2105540.6075] "g" Vector__XXX
 SG_ NxTrkngStrd100HrEngnOtNxMssBn7 : 192|32@1+ (0.0005,0) [0|2105540.6075] "g" Vector__XXX
 SG_ NxTrkngStrd100HrEngnOtNxMssBn8 : 224|32@1+ (0.0005,0) [0|2105540.6075] "g" Vector__XXX
 SG_ NxTrkngStrd100HrEngnOtNxMssBn9 : 256|32@1+ (0.0005,0) [0|2105540.6075] "g" Vector__XXX
 SG_ NxTrkngStrd100HrEngnOtNxMssBn10 : 288|32@1+ (0.0005,0) [0|2105540.6075] "g" Vector__XXX
 SG_ NxTrkngStrd100HrEngnOtNxMssBn11 : 320|32@1+ (0.0005,0) [0|2105540.6075] "g" Vector__XXX
 SG_ NxTrkngStrd100HrEngnOtNxMssBn12 : 352|32@1+ (0.0005,0) [0|2105540.6075] "g" Vector__XXX
 SG_ NxTrkngStrd100HrEngnOtNxMssBn13 : 384|32@1+ (0.0005,0) [0|2105540.6075] "g" Vector__XXX
 SG_ NxTrkngStrd100HrEngnOtNxMssBn14 : 416|32@1+ (0.0005,0) [0|2105540.6075] "g" Vector__XXX
 SG_ NxTStd100HEOtNxMssB15NtB : 448|32@1+ (0.0005,0) [0|2105540.6075] "g" Vector__XXX
 SG_ NxTStd100HEOtNxMssB16RB : 480|32@1+ (0.0005,0) [0|2105540.6075] "g" Vector__XXX
 SG_ NxTStd100HEOtNxMssB17MOB : 512|32@1+ (0.0005,0) [0|2105540.6075] "g" Vector__XXX

BO_ 2566590974 NTSNS: 68 Vector__XXX
 SG_ NxTStd100HSstOtNxMssB1Tt : 0|32@1+ (0.0002,0) [0|842216.243] "g" Vector__XXX
 SG_ NxTrkngStrd100HrSstmOtNxMssBn2 : 32|32@1+ (0.0002,0) [0|842216.243] "g" Vector__XXX
 SG_ NxTrkngStrd100HrSstmOtNxMssBn3 : 64|32@1+ (0.0002,0) [0|842216.243] "g" Vector__XXX
 SG_ NxTrkngStrd100HrSstmOtNxMssBn4 : 96|32@1+ (0.0002,0) [0|842216.243] "g" Vector__XXX
 SG_ NxTrkngStrd100HrSstmOtNxMssBn5 : 128|32@1+ (0.0002,0) [0|842216.243] "g" Vector__XXX
 SG_ NxTrkngStrd100HrSstmOtNxMssBn6 : 160|32@1+ (0.0002,0) [0|842216.243] "g" Vector__XXX
 SG_ NxTrkngStrd100HrSstmOtNxMssBn7 : 192|32@1+ (0.0002,0) [0|842216.243] "g" Vector__XXX
 SG_ NxTrkngStrd100HrSstmOtNxMssBn8 : 224|32@1+ (0.0002,0) [0|842216.243] "g" Vector__XXX
 SG_ NxTrkngStrd100HrSstmOtNxMssBn9 : 256|32@1+ (0.0002,0) [0|842216.243] "g" Vector__XXX
 SG_ NxTrkngStrd100HrSstmOtNxMssBn10 : 288|32@1+ (0.0002,0) [0|842216.243] "g" Vector__XXX
 SG_ NxTrkngStrd100HrSstmOtNxMssBn11 : 320|32@1+ (0.0002,0) [0|842216.243] "g" Vector__XXX
 SG_ NxTrkngStrd100HrSstmOtNxMssBn12 : 352|32@1+ (0.0002,0) [0|842216.243] "g" Vector__XXX
 SG_ NxTrkngStrd100HrSstmOtNxMssBn13 : 384|32@1+ (0.0002,0) [0|842216.243] "g" Vector__XXX
 SG_ NxTrkngStrd100HrSstmOtNxMssBn14 : 416|32@1+ (0.0002,0) [0|842216.243] "g" Vector__XXX
 SG_ NxTStd100HSstOtNxMssB15NtB : 448|32@1+ (0.0002,0) [0|842216.243] "g" Vector__XXX
 SG_ NxTStd100HSstOtNxMssB16RB : 480|32@1+ (0.0002,0) [0|842216.243] "g" Vector__XXX
 SG_ NxTStd100HSstOtNxMssB17MOB : 512|32@1+ (0.0002,0) [0|842216.243] "g" Vector__XXX

BO_ 2566591230 NTFCA: 34 Vector__XXX
 SG_ NxTrkngAtv100HrFlCnsmptnBn1Ttl : 0|16@1+ (0.5,0) [0|32127.5] "l" Vector__XXX
 SG_ NxTrkngAtv100HrFlCnsmptnBn2 : 16|16@1+ (0.5,0) [0|32127.5] "l" Vector__XXX
 SG_ NxTrkngAtv100HrFlCnsmptnBn3 : 32|16@1+ (0.5,0) [0|32127.5] "l" Vector__XXX
 SG_ NxTrkngAtv100HrFlCnsmptnBn4 : 48|16@1+ (0.5,0) [0|32127.5] "l" Vector__XXX
 SG_ NxTrkngAtv100HrFlCnsmptnBn5 : 64|16@1+ (0.5,0) [0|32127.5] "l" Vector__XXX
 SG_ NxTrkngAtv100HrFlCnsmptnBn6 : 80|16@1+ (0.5,0) [0|32127.5] "l" Vector__XXX
 SG_ NxTrkngAtv100HrFlCnsmptnBn7 : 96|16@1+ (0.5,0) [0|32127.5] "l" Vector__XXX
 SG_ NxTrkngAtv100HrFlCnsmptnBn8 : 112|16@1+ (0.5,0) [0|32127.5] "l" Vector__XXX
 SG_ NxTrkngAtv100HrFlCnsmptnBn9 : 128|16@1+ (0.5,0) [0|32127.5] "l" Vector__XXX
 SG_ NxTrkngAtv100HrFlCnsmptnBn10 : 144|16@1+ (0.5,0) [0|32127.5] "l" Vector__XXX
 SG_ NxTrkngAtv100HrFlCnsmptnBn11 : 160|16@1+ (0.5,0) [0|32127.5] "l" Vector__XXX
 SG_ NxTrkngAtv100HrFlCnsmptnBn12 : 176|16@1+ (0.5,0) [0|32127.5] "l" Vector__XXX
 SG_ NxTrkngAtv100HrFlCnsmptnBn13 : 192|16@1+ (0.5,0) [0|32127.5] "l" Vector__XXX
 SG_ NxTrkngAtv100HrFlCnsmptnBn14 : 208|16@1+ (0.5,0) [0|32127.5] "l" Vector__XXX
 SG_ NxTAtv100HFCsptB15NtB : 224|16@1+ (0.5,0) [0|32127.5] "l" Vector__XXX
 SG_ NxTAtv100HFCsptB16RB : 240|16@1+ (0.5,0) [0|32127.5] "l" Vector__XXX
 SG_ NxTAtv100HFCsptB17MOB : 256|16@1+ (0.5,0) [0|32127.5] "l" Vector__XXX

BO_ 2566591486 NTEHA: 34 Vector__XXX
 SG_ NxTrkngAtv100HrEngnRnTmBn1Ttl : 0|16@1+ (10,0) [0|642550] "s" Vector__XXX
 SG_ NxTrkngAtv100HrEngnRnTmBn2 : 16|16@1+ (10,0) [0|642550] "s" Vector__XXX
 SG_ NxTrkngAtv100HrEngnRnTmBn3 : 32|16@1+ (10,0) [0|642550] "s" Vector__XXX
 SG_ NxTrkngAtv100HrEngnRnTmBn4 : 48|16@1+ (10,0) [0|642550] "s" Vector__XXX
 SG_ NxTrkngAtv100HrEngnRnTmBn5 : 64|16@1+ (10,0) [0|642550] "s" Vector__XXX
 SG_ NxTrkngAtv100HrEngnRnTmBn6 : 80|16@1+ (10,0) [0|642550] "s" Vector__XXX
 SG_ NxTrkngAtv100HrEngnRnTmBn7 : 96|16@1+ (10,0) [0|642550] "s" Vector__XXX
 SG_ NxTrkngAtv100HrEngnRnTmBn8 : 112|16@1+ (10,0) [0|642550] "s" Vector__XXX
 SG_ NxTrkngAtv100HrEngnRnTmBn9 : 128|16@1+ (10,0) [0|642550] "s" Vector__XXX
 SG_ NxTrkngAtv100HrEngnRnTmBn10 : 144|16@1+ (10,0) [0|642550] "s" Vector__XXX
 SG_ NxTrkngAtv100HrEngnRnTmBn11 : 160|16@1+ (10,0) [0|642550] "s" Vector__XXX
 SG_ NxTrkngAtv100HrEngnRnTmBn12 : 176|16@1+ (10,0) [0|642550] "s" Vector__XXX
 SG_ NxTrkngAtv100HrEngnRnTmBn13 : 192|16@1+ (10,0) [0|642550] "s" Vector__XXX
 SG_ NxTrkngAtv100HrEngnRnTmBn14 : 208|16@1+ (10,0) [0|642550] "s" Vector__XXX
 SG_ NxTrkngAtv100HrEngnRnTmBn15NtBn : 224|16@1+ (10,0) [0|642550] "s" Vector__XXX
 SG_ NxTAtv100HERTB16RB : 240|16@1+ (10,0) [0|642550] "s" Vector__XXX
 SG_ NxTAtv100HERTB17MOB : 256|16@1+ (10,0) [0|642550] "s" Vector__XXX

BO_ 2566591742 NTVMA: 34 Vector__XXX
 SG_ NxTrkngAtv100HrVhlDstnBn1Ttl : 0|16@1+ (0.25,0) [0|16063.75] "km" Vector__XXX
 SG_ NxTrkngAtv100HrVhlDstnBn2 : 16|16@1+ (0.25,0) [0|16063.75] "km" Vector__XXX
 SG_ NxTrkngAtv100HrVhlDstnBn3 : 32|16@1+ (0.25,0) [0|16063.75] "km" Vector__XXX
 SG_ NxTrkngAtv100HrVhlDstnBn4 : 48|16@1+ (0.25,0) [0|16063.75] "km" Vector__XXX
 SG_ NxTrkngAtv100HrVhlDstnBn5 : 64|16@1+ (0.25,0) [0|16063.75] "km" Vector__XXX
 SG_ NxTrkngAtv100HrVhlDstnBn6 : 80|16@1+ (0.25,0) [0|16063.75] "km" Vector__XXX
 SG_ NxTrkngAtv100HrVhlDstnBn7 : 96|16@1+ (0.25,0) [0|16063.75] "km" Vector__XXX
 SG_ NxTrkngAtv100HrVhlDstnBn8 : 112|16@1+ (0.25,0) [0|16063.75] "km" Vector__XXX
 SG_ NxTrkngAtv100HrVhlDstnBn9 : 128|16@1+ (0.25,0) [0|16063.75] "km" Vector__XXX
 SG_ NxTrkngAtv100HrVhlDstnBn10 : 144|16@1+ (0.25,0) [0|16063.75] "km" Vector__XXX
 SG_ NxTrkngAtv100HrVhlDstnBn11 : 160|16@1+ (0.25,0) [0|16063.75] "km" Vector__XXX
 SG_ NxTrkngAtv100HrVhlDstnBn12 : 176|16@1+ (0.25,0) [0|16063.75] "km" Vector__XXX
 SG_ NxTrkngAtv100HrVhlDstnBn13 : 192|16@1+ (0.25,0) [0|16063.75] "km" Vector__XXX
 SG_ NxTrkngAtv100HrVhlDstnBn14 : 208|16@1+ (0.25,0) [0|16063.75] "km" Vector__XXX
 SG_ NxTrkngAtv100HrVhlDstnBn15NtBn : 224|16@1+ (0.25,0) [0|16063.75] "km" Vector__XXX
 SG_ NxTrkngAtv100HrVhlDstnBn16RgnBn : 240|16@1+ (0.25,0) [0|16063.75] "km" Vector__XXX
 SG_ NxTAtv100HVDstB17MOB : 256|16@1+ (0.25,0) [0|16063.75] "km" Vector__XXX

BO_ 2566591998 NTEEA: 34 Vector__XXX
 SG_ NxTAtv100HEOtptEB1Tt : 0|16@1+ (1,0) [0|64255] "kWh" Vector__XXX
 SG_ NxTrkngAtv100HrEngnOtptEnrgBn2 : 16|16@1+ (1,0) [0|64255] "kWh" Vector__XXX
 SG_ NxTrkngAtv100HrEngnOtptEnrgBn3 : 32|16@1+ (1,0) [0|64255] "kWh" Vector__XXX
 SG_ NxTrkngAtv100HrEngnOtptEnrgBn4 : 48|16@1+ (1,0) [0|64255] "kWh" Vector__XXX
 SG_ NxTrkngAtv100HrEngnOtptEnrgBn5 : 64|16@1+ (1,0) [0|64255] "kWh" Vector__XXX
 SG_ NxTrkngAtv100HrEngnOtptEnrgBn6 : 80|16@1+ (1,0) [0|64255] "kWh" Vector__XXX
 SG_ NxTrkngAtv100HrEngnOtptEnrgBn7 : 96|16@1+ (1,0) [0|64255] "kWh" Vector__XXX
 SG_ NxTrkngAtv100HrEngnOtptEnrgBn8 : 112|16@1+ (1,0) [0|64255] "kWh" Vector__XXX
 SG_ NxTrkngAtv100HrEngnOtptEnrgBn9 : 128|16@1+ (1,0) [0|64255] "kWh" Vector__XXX
 SG_ NxTrkngAtv100HrEngnOtptEnrgBn10 : 144|16@1+ (1,0) [0|64255] "kWh" Vector__XXX
 SG_ NxTrkngAtv100HrEngnOtptEnrgBn11 : 160|16@1+ (1,0) [0|64255] "kWh" Vector__XXX
 SG_ NxTrkngAtv100HrEngnOtptEnrgBn12 : 176|16@1+ (1,0) [0|64255] "kWh" Vector__XXX
 SG_ NxTrkngAtv100HrEngnOtptEnrgBn13 : 192|16@1+ (1,0) [0|64255] "kWh" Vector__XXX
 SG_ NxTrkngAtv100HrEngnOtptEnrgBn14 : 208|16@1+ (1,0) [0|64255] "kWh" Vector__XXX
 SG_ NxTAtv100HEOtptEB15NtB : 224|16@1+ (1,0) [0|64255] "kWh" Vector__XXX
 SG_ NxTAtv100HEOtptEB16RB : 240|16@1+ (1,0) [0|64255] "kWh" Vector__XXX
 SG_ NxTAtv100HEOtptEB17MOB : 256|16@1+ (1,0) [0|64255] "kWh" Vector__XXX

BO_ 2566592254 NTENA: 68 Vector__XXX
 SG_ NxTAtv100HEOtNxMssB1Tt : 0|32@1+ (0.0005,0) [0|2105540.6075] "g" Vector__XXX
 SG_ NxTrkngAtv100HrEngnOtNxMssBn2 : 32|32@1+ (0.0005,0) [0|2105540.6075] "g" Vector__XXX
 SG_ NxTrkngAtv100HrEngnOtNxMssBn3 : 64|32@1+ (0.0005,0) [0|2105540.6075] "g" Vector__XXX
 SG_ NxTrkngAtv100HrEngnOtNxMssBn4 : 96|32@1+ (0.0005,0) [0|2105540.6075] "g" Vector__XXX
 SG_ NxTrkngAtv100HrEngnOtNxMssBn5 : 128|32@1+ (0.0005,0) [0|2105540.6075] "g" Vector__XXX
 SG_ NxTrkngAtv100HrEngnOtNxMssBn6 : 160|32@1+ (0.0005,0) [0|2105540.6075] "g" Vector__XXX
 SG_ NxTrkngAtv100HrEngnOtNxMssBn7 : 192|32@1+ (0.0005,0) [0|2105540.6075] "g" Vector__XXX
 SG_ NxTrkngAtv100HrEngnOtNxMssBn8 : 224|32@1+ (0.0005,0) [0|2105540.6075] "g" Vector__XXX
 SG_ NxTrkngAtv100HrEngnOtNxMssBn9 : 256|32@1+ (0.0005,0) [0|2105540.6075] "g" Vector__XXX
 SG_ NxTrkngAtv100HrEngnOtNxMssBn10 : 288|32@1+ (0.0005,0) [0|2105540.6075] "g" Vector__XXX
 SG_ NxTrkngAtv100HrEngnOtNxMssBn11 : 320|32@1+ (0.0005,0) [0|2105540.6075] "g" Vector__XXX
 SG_ NxTrkngAtv100HrEngnOtNxMssBn12 : 352|32@1+ (0.0005,0) [0|2105540.6075] "g" Vector__XXX
 SG_ NxTrkngAtv100HrEngnOtNxMssBn13 : 384|32@1+ (0.0005,0) [0|2105540.6075] "g" Vector__XXX
 SG_ NxTrkngAtv100HrEngnOtNxMssBn14 : 416|32@1+ (0.0005,0) [0|2105540.6075] "g" Vector__XXX
 SG_ NxTAtv100HEOtNxMssB15NtB : 448|32@1+ (0.0005,0) [0|2105540.6075] "g" Vector__XXX
 SG_ NxTAtv100HEOtNxMssB16RB : 480|32@1+ (0.0005,0) [0|2105540.6075] "g" Vector__XXX
 SG_ NxTAtv100HEOtNxMssB17MOB : 512|32@1+ (0.0005,0) [0|2105540.6075] "g" Vector__XXX

BO_ 2566592510 NTSNA: 68 Vector__XXX
 SG_ NxTAtv100HSstOtNxMssB1Tt : 0|32@1+ (0.0002,0) [0|842216.243] "g" Vector__XXX
 SG_ NxTrkngAtv100HrSstmOtNxMssBn2 : 32|32@1+ (0.0002,0) [0|842216.243] "g" Vector__XXX
 SG_ NxTrkngAtv100HrSstmOtNxMssBn3 : 64|32@1+ (0.0002,0) [0|842216.243] "g" Vector__XXX
 SG_ NxTrkngAtv100HrSstmOtNxMssBn4 : 96|32@1+ (0.0002,0) [0|842216.243] "g" Vector__XXX
 SG_ NxTrkngAtv100HrSstmOtNxMssBn5 : 128|32@1+ (0.0002,0) [0|842216.243] "g" Vector__XXX
 SG_ NxTrkngAtv100HrSstmOtNxMssBn6 : 160|32@1+ (0.0002,0) [0|842216.243] "g" Vector__XXX
 SG_ NxTrkngAtv100HrSstmOtNxMssBn7 : 192|32@1+ (0.0002,0) [0|842216.243] "g" Vector__XXX
 SG_ NxTrkngAtv100HrSstmOtNxMssBn8 : 224|32@1+ (0.0002,0) [0|842216.243] "g" Vector__XXX
 SG_ NxTrkngAtv100HrSstmOtNxMssBn9 : 256|32@1+ (0.0002,0) [0|842216.243] "g" Vector__XXX
 SG_ NxTrkngAtv100HrSstmOtNxMssBn10 : 288|32@1+ (0.0002,0) [0|842216.243] "g" Vector__XXX
 SG_ NxTrkngAtv100HrSstmOtNxMssBn11 : 320|32@1+ (0.0002,0) [0|842216.243] "g" Vector__XXX
 SG_ NxTrkngAtv100HrSstmOtNxMssBn12 : 352|32@1+ (0.0002,0) [0|842216.243] "g" Vector__XXX
 SG_ NxTrkngAtv100HrSstmOtNxMssBn13 : 384|32@1+ (0.0002,0) [0|842216.243] "g" Vector__XXX
 SG_ NxTrkngAtv100HrSstmOtNxMssBn14 : 416|32@1+ (0.0002,0) [0|842216.243] "g" Vector__XXX
 SG_ NxTAtv100HSstOtNxMssB15NtB : 448|32@1+ (0.0002,0) [0|842216.243] "g" Vector__XXX
 SG_ NxTAtv100HSstOtNxMssB16RB : 480|32@1+ (0.0002,0) [0|842216.243] "g" Vector__XXX
 SG_ NxTAtv100HSstOtNxMssB17MOB : 512|32@1+ (0.0002,0) [0|842216.243] "g" Vector__XXX

BO_ 2365266174 MG6IC2: 8 Vector__XXX
 SG_ MtrGnrtr6InvrtrRtLmtsRqst2Cntr : 8|4@1+ (1,0) [0|15] "" Vector__XXX
 SG_ MtrGnrtr6InvrtrRtLmtsRqst2Cr : 0|8@1+ (1,0) [0|250] "count" Vector__XXX
 SG_ MtrGnrtr6InvrtrPdCntrlAppllMd : 12|4@1+ (1,0) [0|15] "" Vector__XXX
 SG_ MtGt6IvtPdCtNzdDtG : 16|8@1+ (0.03125,0) [0|7.8125] "%/(%/s)" Vector__XXX
 SG_ MtGt6IvtPdCtNzdItG : 24|16@1+ (0.015625,0) [0|1003.984375] "%/(%/s)" Vector__XXX
 SG_ MtGt6IvtPdCtNzdPptG : 40|12@1+ (0.0625,0) [0|250.9375] "%/%" Vector__XXX
 SG_ MtGt6IvtPdCtFdFwdTq : 52|12@1+ (0.0625,-125) [-125|125.9375] "%" Vector__XXX

BO_ 2566593022 MG6IRP: 8 Vector__XXX
 SG_ MtrGnrtr6InvrtrLmtsRqstPwrCntr : 8|4@1+ (1,0) [0|15] "" Vector__XXX
 SG_ MtGt6IvtLtsRqstMPwMx : 12|12@1+ (0.0625,-125) [-125|125.9375] "%" Vector__XXX
 SG_ MtGt6IvtLtsRqstMPwM : 24|12@1+ (0.0625,-125) [-125|125.9375] "%" Vector__XXX
 SG_ MtrGnrtr6InvrtrLmtsRqstPwrCr : 0|8@1+ (1,0) [0|250] "count" Vector__XXX
 SG_ MtGt6IvtLtsRqstDSdPwMx : 36|12@1+ (0.0625,-125) [-125|125.9375] "%" Vector__XXX
 SG_ MtGt6IvtLtsRqstDSdPwM : 48|12@1+ (0.0625,-125) [-125|125.9375] "%" Vector__XXX

BO_ 2566593278 MG6ILRM: 8 Vector__XXX
 SG_ MtrGnrtr6InvrtrLmtsRqstMhnlCntr : 8|4@1+ (1,0) [0|15] "" Vector__XXX
 SG_ MtrGnrtr6InvrtrLmtsRqstTrqMxmm : 12|12@1+ (0.0625,-125) [-125|125.9375] "%" Vector__XXX
 SG_ MtrGnrtr6InvrtrLmtsRqstTrqMnmm : 24|12@1+ (0.0625,-125) [-125|125.9375] "%" Vector__XXX
 SG_ MtrGnrtr6InvrtrLmtsRqstSpdMxmm : 36|12@1+ (0.0625,-125) [-125|125.9375] "%" Vector__XXX
 SG_ MtrGnrtr6InvrtrLmtsRqstSpdMnmm : 48|12@1+ (0.0625,-125) [-125|125.9375] "%" Vector__XXX
 SG_ MtrGnrtr6InvrtrLmtsRqstMhnlCr : 0|8@1+ (1,0) [0|250] "count" Vector__XXX

BO_ 2566593534 MG6ILRDC: 8 Vector__XXX
 SG_ MtrGnrtr6InvrtrLmtsRqstDSdCr : 0|8@1+ (1,0) [0|250] "count" Vector__XXX
 SG_ MtrGnrtr6InvrtrLmtsRqstDSdCntr : 8|4@1+ (1,0) [0|15] "" Vector__XXX
 SG_ MtGt6IvtLtsRqstDSdVtMx : 12|12@1+ (0.0625,-125) [-125|125.9375] "%" Vector__XXX
 SG_ MtGt6IvtLtsRqstDSdVtM : 24|12@1+ (0.0625,-125) [-125|125.9375] "%" Vector__XXX
 SG_ MtGt6IvtLtsRqstDSdCtMx : 36|12@1+ (0.0625,-125) [-125|125.9375] "%" Vector__XXX
 SG_ MtGt6IvtLtsRqstDSdCtM : 48|12@1+ (0.0625,-125) [-125|125.9375] "%" Vector__XXX

BO_ 2566593790 MG6IIR: 8 Vector__XXX
 SG_ MtGt6IvtHVtBsAtvIstTstCd : 0|2@1+ (1,0) [0|3] "" Vector__XXX
 SG_ MtGt6IvtHVtBsPssvIstTstCd : 2|2@1+ (1,0) [0|3] "" Vector__XXX
 SG_ MtGt6IvtHVtBsHSdRsstCtRqst : 4|2@1+ (1,0) [0|3] "" Vector__XXX
 SG_ MtGt6IvtHVtBsLwSdRsstCtRqst : 6|2@1+ (1,0) [0|3] "" Vector__XXX

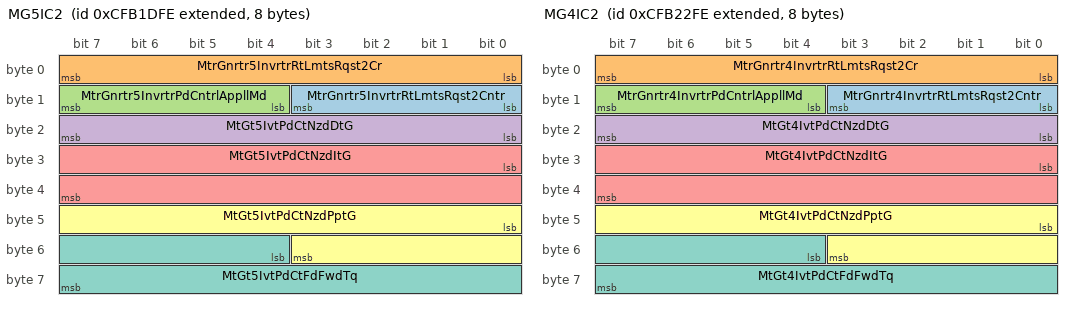
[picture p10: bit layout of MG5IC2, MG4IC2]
BO_ 2365267454 MG5IC2: 8 Vector__XXX
 SG_ MtrGnrtr5InvrtrRtLmtsRqst2Cntr : 8|4@1+ (1,0) [0|15] "" Vector__XXX
 SG_ MtrGnrtr5InvrtrRtLmtsRqst2Cr : 0|8@1+ (1,0) [0|250] "count" Vector__XXX
 SG_ MtrGnrtr5InvrtrPdCntrlAppllMd : 12|4@1+ (1,0) [0|15] "" Vector__XXX
 SG_ MtGt5IvtPdCtNzdDtG : 16|8@1+ (0.03125,0) [0|7.8125] "%/(%/s)" Vector__XXX
 SG_ MtGt5IvtPdCtNzdItG : 24|16@1+ (0.015625,0) [0|1003.984375] "%/(%/s)" Vector__XXX
 SG_ MtGt5IvtPdCtNzdPptG : 40|12@1+ (0.0625,0) [0|250.9375] "%/%" Vector__XXX
 SG_ MtGt5IvtPdCtFdFwdTq : 52|12@1+ (0.0625,-125) [-125|125.9375] "%" Vector__XXX

BO_ 2566594302 MG5IRP: 8 Vector__XXX
 SG_ MtrGnrtr5InvrtrLmtsRqstPwrCntr : 8|4@1+ (1,0) [0|15] "" Vector__XXX
 SG_ MtGt5IvtLtsRqstMPwMx : 12|12@1+ (0.0625,-125) [-125|125.9375] "%" Vector__XXX
 SG_ MtGt5IvtLtsRqstMPwM : 24|12@1+ (0.0625,-125) [-125|125.9375] "%" Vector__XXX
 SG_ MtrGnrtr5InvrtrLmtsRqstPwrCr : 0|8@1+ (1,0) [0|250] "count" Vector__XXX
 SG_ MtGt5IvtLtsRqstDSdPwMx : 36|12@1+ (0.0625,-125) [-125|125.9375] "%" Vector__XXX
 SG_ MtGt5IvtLtsRqstDSdPwM : 48|12@1+ (0.0625,-125) [-125|125.9375] "%" Vector__XXX

BO_ 2566594558 MG5ILRM: 8 Vector__XXX
 SG_ MtrGnrtr5InvrtrLmtsRqstMhnlCntr : 8|4@1+ (1,0) [0|15] "" Vector__XXX
 SG_ MtrGnrtr5InvrtrLmtsRqstTrqMxmm : 12|12@1+ (0.0625,-125) [-125|125.9375] "%" Vector__XXX
 SG_ MtrGnrtr5InvrtrLmtsRqstTrqMnmm : 24|12@1+ (0.0625,-125) [-125|125.9375] "%" Vector__XXX
 SG_ MtrGnrtr5InvrtrLmtsRqstSpdMxmm : 36|12@1+ (0.0625,-125) [-125|125.9375] "%" Vector__XXX
 SG_ MtrGnrtr5InvrtrLmtsRqstSpdMnmm : 48|12@1+ (0.0625,-125) [-125|125.9375] "%" Vector__XXX
 SG_ MtrGnrtr5InvrtrLmtsRqstMhnlCr : 0|8@1+ (1,0) [0|250] "count" Vector__XXX

BO_ 2566594814 MG5ILRDC: 8 Vector__XXX
 SG_ MtrGnrtr5InvrtrLmtsRqstDSdCr : 0|8@1+ (1,0) [0|250] "count" Vector__XXX
 SG_ MtrGnrtr5InvrtrLmtsRqstDSdCntr : 8|4@1+ (1,0) [0|15] "" Vector__XXX
 SG_ MtGt5IvtLtsRqstDSdVtMx : 12|12@1+ (0.0625,-125) [-125|125.9375] "%" Vector__XXX
 SG_ MtGt5IvtLtsRqstDSdVtM : 24|12@1+ (0.0625,-125) [-125|125.9375] "%" Vector__XXX
 SG_ MtGt5IvtLtsRqstDSdCtMx : 36|12@1+ (0.0625,-125) [-125|125.9375] "%" Vector__XXX
 SG_ MtGt5IvtLtsRqstDSdCtM : 48|12@1+ (0.0625,-125) [-125|125.9375] "%" Vector__XXX

BO_ 2566595070 MG5IIR: 8 Vector__XXX
 SG_ MtGt5IvtHVtBsAtvIstTstCd : 0|2@1+ (1,0) [0|3] "" Vector__XXX
 SG_ MtGt5IvtHVtBsPssvIstTstCd : 2|2@1+ (1,0) [0|3] "" Vector__XXX
 SG_ MtGt5IvtHVtBsHSdRsstCtRqst : 4|2@1+ (1,0) [0|3] "" Vector__XXX
 SG_ MtGt5IvtHVtBsLwSdRsstCtRqst : 6|2@1+ (1,0) [0|3] "" Vector__XXX

BO_ 2365268734 MG4IC2: 8 Vector__XXX
 SG_ MtrGnrtr4InvrtrRtLmtsRqst2Cntr : 8|4@1+ (1,0) [0|15] "" Vector__XXX
 SG_ MtrGnrtr4InvrtrRtLmtsRqst2Cr : 0|8@1+ (1,0) [0|250] "count" Vector__XXX
 SG_ MtrGnrtr4InvrtrPdCntrlAppllMd : 12|4@1+ (1,0) [0|15] "" Vector__XXX
 SG_ MtGt4IvtPdCtNzdDtG : 16|8@1+ (0.03125,0) [0|7.8125] "%/(%/s)" Vector__XXX
 SG_ MtGt4IvtPdCtNzdItG : 24|16@1+ (0.015625,0) [0|1003.984375] "%/(%/s)" Vector__XXX
 SG_ MtGt4IvtPdCtNzdPptG : 40|12@1+ (0.0625,0) [0|250.9375] "%/%" Vector__XXX
 SG_ MtGt4IvtPdCtFdFwdTq : 52|12@1+ (0.0625,-125) [-125|125.9375] "%" Vector__XXX

BO_ 2566595582 MG4IRP: 8 Vector__XXX
 SG_ MtrGnrtr4InvrtrLmtsRqstPwrCntr : 8|4@1+ (1,0) [0|15] "" Vector__XXX
 SG_ MtGt4IvtLtsRqstMPwMx : 12|12@1+ (0.0625,-125) [-125|125.9375] "%" Vector__XXX
 SG_ MtGt4IvtLtsRqstMPwM : 24|12@1+ (0.0625,-125) [-125|125.9375] "%" Vector__XXX
 SG_ MtrGnrtr4InvrtrLmtsRqstPwrCr : 0|8@1+ (1,0) [0|250] "count" Vector__XXX
 SG_ MtGt4IvtLtsRqstDSdPwMx : 36|12@1+ (0.0625,-125) [-125|125.9375] "%" Vector__XXX
 SG_ MtGt4IvtLtsRqstDSdPwM : 48|12@1+ (0.0625,-125) [-125|125.9375] "%" Vector__XXX

BO_ 2566595838 MG4ILRM: 8 Vector__XXX
 SG_ MtrGnrtr4InvrtrLmtsRqstMhnlCntr : 8|4@1+ (1,0) [0|15] "" Vector__XXX
 SG_ MtrGnrtr4InvrtrLmtsRqstTrqMxmm : 12|12@1+ (0.0625,-125) [-125|125.9375] "%" Vector__XXX
 SG_ MtrGnrtr4InvrtrLmtsRqstTrqMnmm : 24|12@1+ (0.0625,-125) [-125|125.9375] "%" Vector__XXX
 SG_ MtrGnrtr4InvrtrLmtsRqstSpdMxmm : 36|12@1+ (0.0625,-125) [-125|125.9375] "%" Vector__XXX
 SG_ MtrGnrtr4InvrtrLmtsRqstSpdMnmm : 48|12@1+ (0.0625,-125) [-125|125.9375] "%" Vector__XXX
 SG_ MtrGnrtr4InvrtrLmtsRqstMhnlCr : 0|8@1+ (1,0) [0|250] "count" Vector__XXX

BO_ 2566596094 MG4ILRDC: 8 Vector__XXX
 SG_ MtrGnrtr4InvrtrLmtsRqstDSdCr : 0|8@1+ (1,0) [0|250] "count" Vector__XXX
 SG_ MtrGnrtr4InvrtrLmtsRqstDSdCntr : 8|4@1+ (1,0) [0|15] "" Vector__XXX
 SG_ MtGt4IvtLtsRqstDSdVtMx : 12|12@1+ (0.0625,-125) [-125|125.9375] "%" Vector__XXX
 SG_ MtGt4IvtLtsRqstDSdVtM : 24|12@1+ (0.0625,-125) [-125|125.9375] "%" Vector__XXX
 SG_ MtGt4IvtLtsRqstDSdCtMx : 36|12@1+ (0.0625,-125) [-125|125.9375] "%" Vector__XXX
 SG_ MtGt4IvtLtsRqstDSdCtM : 48|12@1+ (0.0625,-125) [-125|125.9375] "%" Vector__XXX

BO_ 2566596350 MG4IIR: 8 Vector__XXX
 SG_ MtGt4IvtHVtBsAtvIstTstCd : 0|2@1+ (1,0) [0|3] "" Vector__XXX
 SG_ MtGt4IvtHVtBsPssvIstTstCd : 2|2@1+ (1,0) [0|3] "" Vector__XXX
 SG_ MtGt4IvtHVtBsHSdRsstCtRqst : 4|2@1+ (1,0) [0|3] "" Vector__XXX
 SG_ MtGt4IvtHVtBsLwSdRsstCtRqst : 6|2@1+ (1,0) [0|3] "" Vector__XXX

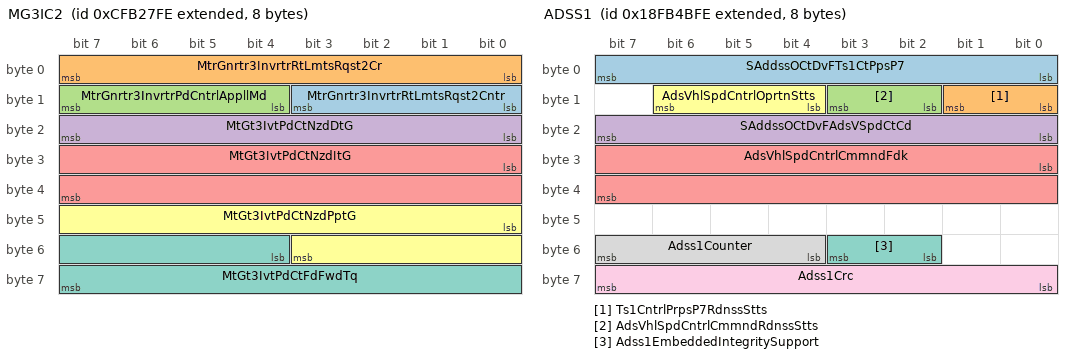
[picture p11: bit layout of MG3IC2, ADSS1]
BO_ 2365270014 MG3IC2: 8 Vector__XXX
 SG_ MtrGnrtr3InvrtrRtLmtsRqst2Cntr : 8|4@1+ (1,0) [0|15] "" Vector__XXX
 SG_ MtrGnrtr3InvrtrRtLmtsRqst2Cr : 0|8@1+ (1,0) [0|250] "count" Vector__XXX
 SG_ MtrGnrtr3InvrtrPdCntrlAppllMd : 12|4@1+ (1,0) [0|15] "" Vector__XXX
 SG_ MtGt3IvtPdCtNzdDtG : 16|8@1+ (0.03125,0) [0|7.8125] "%/(%/s)" Vector__XXX
 SG_ MtGt3IvtPdCtNzdItG : 24|16@1+ (0.015625,0) [0|1003.984375] "%/(%/s)" Vector__XXX
 SG_ MtGt3IvtPdCtNzdPptG : 40|12@1+ (0.0625,0) [0|250.9375] "%/%" Vector__XXX
 SG_ MtGt3IvtPdCtFdFwdTq : 52|12@1+ (0.0625,-125) [-125|125.9375] "%" Vector__XXX

BO_ 2566596862 MG3IRP: 8 Vector__XXX
 SG_ MtrGnrtr3InvrtrLmtsRqstPwrCntr : 8|4@1+ (1,0) [0|15] "" Vector__XXX
 SG_ MtGt3IvtLtsRqstMPwMx : 12|12@1+ (0.0625,-125) [-125|125.9375] "%" Vector__XXX
 SG_ MtGt3IvtLtsRqstMPwM : 24|12@1+ (0.0625,-125) [-125|125.9375] "%" Vector__XXX
 SG_ MtrGnrtr3InvrtrLmtsRqstPwrCr : 0|8@1+ (1,0) [0|250] "count" Vector__XXX
 SG_ MtGt3IvtLtsRqstDSdPwMx : 36|12@1+ (0.0625,-125) [-125|125.9375] "%" Vector__XXX
 SG_ MtGt3IvtLtsRqstDSdPwM : 48|12@1+ (0.0625,-125) [-125|125.9375] "%" Vector__XXX

BO_ 2566597118 MG3ILRM: 8 Vector__XXX
 SG_ MtrGnrtr3InvrtrLmtsRqstMhnlCntr : 8|4@1+ (1,0) [0|15] "" Vector__XXX
 SG_ MtrGnrtr3InvrtrLmtsRqstTrqMxmm : 12|12@1+ (0.0625,-125) [-125|125.9375] "%" Vector__XXX
 SG_ MtrGnrtr3InvrtrLmtsRqstTrqMnmm : 24|12@1+ (0.0625,-125) [-125|125.9375] "%" Vector__XXX
 SG_ MtrGnrtr3InvrtrLmtsRqstSpdMxmm : 36|12@1+ (0.0625,-125) [-125|125.9375] "%" Vector__XXX
 SG_ MtrGnrtr3InvrtrLmtsRqstSpdMnmm : 48|12@1+ (0.0625,-125) [-125|125.9375] "%" Vector__XXX
 SG_ MtrGnrtr3InvrtrLmtsRqstMhnlCr : 0|8@1+ (1,0) [0|250] "count" Vector__XXX

BO_ 2566597374 MG3ILRDC: 8 Vector__XXX
 SG_ MtrGnrtr3InvrtrLmtsRqstDSdCr : 0|8@1+ (1,0) [0|250] "count" Vector__XXX
 SG_ MtrGnrtr3InvrtrLmtsRqstDSdCntr : 8|4@1+ (1,0) [0|15] "" Vector__XXX
 SG_ MtGt3IvtLtsRqstDSdVtMx : 12|12@1+ (0.0625,-125) [-125|125.9375] "%" Vector__XXX
 SG_ MtGt3IvtLtsRqstDSdVtM : 24|12@1+ (0.0625,-125) [-125|125.9375] "%" Vector__XXX
 SG_ MtGt3IvtLtsRqstDSdCtMx : 36|12@1+ (0.0625,-125) [-125|125.9375] "%" Vector__XXX
 SG_ MtGt3IvtLtsRqstDSdCtM : 48|12@1+ (0.0625,-125) [-125|125.9375] "%" Vector__XXX

BO_ 2566597630 MG3IIR: 8 Vector__XXX
 SG_ MtGt3IvtHVtBsAtvIstTstCd : 0|2@1+ (1,0) [0|3] "" Vector__XXX
 SG_ MtGt3IvtHVtBsPssvIstTstCd : 2|2@1+ (1,0) [0|3] "" Vector__XXX
 SG_ MtGt3IvtHVtBsHSdRsstCtRqst : 4|2@1+ (1,0) [0|3] "" Vector__XXX
 SG_ MtGt3IvtHVtBsLwSdRsstCtRqst : 6|2@1+ (1,0) [0|3] "" Vector__XXX

BO_ 2566598142 TCI82: 8 Vector__XXX
 SG_ EngineTurbocharger5Speed : 0|16@1+ (4,0) [0|257020] "rpm" Vector__XXX
 SG_ EngineTurbocharger6Speed : 16|16@1+ (4,0) [0|257020] "rpm" Vector__XXX
 SG_ EngnTrhrgr5CmprssrIntkPrssr : 32|16@1+ (0.0078125,-250) [-250|251.9921875] "kPa" Vector__XXX
 SG_ EngnTrhrgr6CmprssrIntkPrssr : 48|16@1+ (0.0078125,-250) [-250|251.9921875] "kPa" Vector__XXX

BO_ 2566598398 WINCH2: 8 Vector__XXX
 SG_ WinchLifetimeRevolutionCounter : 0|32@1+ (1,0) [0|4211081215] "count" Vector__XXX

BO_ 2365272062 MG6IR1: 8 Vector__XXX
 SG_ MtrGnrtr6InvrtrRfrn1Cntr : 8|4@1+ (1,0) [0|15] "" Vector__XXX
 SG_ MtrGnrtr6InvrtrRfrnTrq : 16|16@1+ (0.5,0) [0|32127.5] "Nm" Vector__XXX
 SG_ MtrGnrtr6InvrtrRfrnSpd : 32|16@1+ (4,0) [0|257020] "rpm" Vector__XXX
 SG_ MtrGnrtr6InvrtrRfrnPwr : 48|16@1+ (0.0625,0) [0|4015.9375] "kW" Vector__XXX
 SG_ MtrGnrtr6InvrtrRfrn1Cr : 0|8@1+ (1,0) [0|250] "count" Vector__XXX

BO_ 2365272318 MG6IS1: 8 Vector__XXX
 SG_ MtrGnrtr6InvrtrStts1Cntr : 8|4@1+ (1,0) [0|15] "" Vector__XXX
 SG_ MotorGenerator6Torque : 12|12@1+ (0.0625,-125) [-125|125.9375] "%" Vector__XXX
 SG_ MotorGenerator6Speed : 24|16@1+ (0.00390625,-125) [-125|125.99609375] "%" Vector__XXX
 SG_ MtrGnrtr6InvrtrStts1Cr : 0|8@1+ (1,0) [0|250] "count" Vector__XXX
 SG_ MtrGnrtr6InvrtrDSdCrrnt : 40|12@1+ (0.0625,-125) [-125|125.9375] "%" Vector__XXX
 SG_ MtrGnrtr6InvrtrDSdVltg : 52|12@1+ (0.0625,-125) [-125|125.9375] "%" Vector__XXX

BO_ 2365272574 MG6IR2: 8 Vector__XXX
 SG_ MtrGnrtr6InvrtrRfrn2Cntr : 8|4@1+ (1,0) [0|15] "" Vector__XXX
 SG_ MtrGnrtr6InvrtrRfrnCrrnt : 32|16@1+ (0.125,0) [0|8031.875] "A" Vector__XXX
 SG_ MtrGnrtr6InvrtrRfrnVltg : 48|16@1+ (0.125,0) [0|8031.875] "V" Vector__XXX
 SG_ MtrGnrtr6InvrtrRfrn2Cr : 0|8@1+ (1,0) [0|250] "count" Vector__XXX

BO_ 2566599422 MG6IT: 8 Vector__XXX
 SG_ MtrGnrtr6InvrtrTmprtr1 : 0|8@1+ (1,-40) [-40|210] "degC" Vector__XXX
 SG_ MtrGnrtr6InvrtrTmprtr2 : 8|8@1+ (1,-40) [-40|210] "degC" Vector__XXX
 SG_ MtrGnrtr6InvrtrTmprtr3 : 16|8@1+ (1,-40) [-40|210] "degC" Vector__XXX
 SG_ MtrGnrtr6InvrtrTmprtr4 : 24|8@1+ (1,-40) [-40|210] "degC" Vector__XXX
 SG_ MtrGnrtr6InvrtrTmprtr5 : 32|8@1+ (1,-40) [-40|210] "degC" Vector__XXX

BO_ 2566599678 MG6IMT: 8 Vector__XXX
 SG_ MotorGenerator6Temperature1 : 0|8@1+ (1,-40) [-40|210] "degC" Vector__XXX
 SG_ MotorGenerator6Temperature2 : 8|8@1+ (1,-40) [-40|210] "degC" Vector__XXX
 SG_ MotorGenerator6Temperature3 : 16|8@1+ (1,-40) [-40|210] "degC" Vector__XXX
 SG_ MotorGenerator6Temperature4 : 24|8@1+ (1,-40) [-40|210] "degC" Vector__XXX

BO_ 2566599934 MG6II: 8 Vector__XXX
 SG_ MtrGnrtr6InvrtrIsltnIntgrtCntr : 8|4@1+ (1,0) [0|15] "" Vector__XXX
 SG_ MtGt6IvtHVtBsAtvIstTstStts : 24|4@1+ (1,0) [0|15] "" Vector__XXX
 SG_ MtGt6IvtHVtBsPssvIstTstStts : 28|4@1+ (1,0) [0|15] "" Vector__XXX
 SG_ MtGt6IvtHVtBsAtvIstTstRsts : 32|16@1+ (0.1,0) [0|6425.5] "OhmPerV" Vector__XXX
 SG_ MtGt6IvtHVtBsPssvIstTstRsts : 48|16@1+ (0.1,0) [0|6425.5] "OhmPerV" Vector__XXX
 SG_ MtrGnrtr6InvrtrIsltnIntgrtCr : 0|8@1+ (1,0) [0|250] "count" Vector__XXX
 SG_ MtGt6IvtDSdNtvTCsssGdVt : 12|12@1+ (0.0625,-125) [-125|125.9375] "%" Vector__XXX

BO_ 2566600190 MG6IAPL: 8 Vector__XXX
 SG_ MtGt6IvtPwLtdDTUddRs : 0|2@1+ (1,0) [0|3] "" Vector__XXX
 SG_ MtGt6IvtPwLtdDTMPwMx : 10|2@1+ (1,0) [0|3] "" Vector__XXX
 SG_ MtGt6IvtPwLtdDTMPwM : 12|2@1+ (1,0) [0|3] "" Vector__XXX
 SG_ MtrGnrtr6InvrtrPwrLmtdDTTrqMxmm : 18|2@1+ (1,0) [0|3] "" Vector__XXX
 SG_ MtrGnrtr6InvrtrPwrLmtdDTTrqMnmm : 20|2@1+ (1,0) [0|3] "" Vector__XXX
 SG_ MtrGnrtr6InvrtrPwrLmtdDTSpdMxmm : 22|2@1+ (1,0) [0|3] "" Vector__XXX
 SG_ MtrGnrtr6InvrtrPwrLmtdDTSpdMnmm : 24|2@1+ (1,0) [0|3] "" Vector__XXX
 SG_ MtGt6IvtPwLtdDTIvtTpt : 28|2@1+ (1,0) [0|3] "" Vector__XXX
 SG_ MtGt6IvtPwLtdDTMtTpt : 30|2@1+ (1,0) [0|3] "" Vector__XXX
 SG_ MtGt6IvtPwLtdDTFtCdt : 32|2@1+ (1,0) [0|3] "" Vector__XXX
 SG_ MtGt6IvtPwLtdDTAtvTqRtLt : 34|2@1+ (1,0) [0|3] "" Vector__XXX
 SG_ MtGt6IvtPwLtdDTAtvSpdRtLt : 36|2@1+ (1,0) [0|3] "" Vector__XXX
 SG_ MtGt6IvtTqLtdDTMCtsts : 38|2@1+ (1,0) [0|3] "" Vector__XXX
 SG_ MtGt6IvtPwLtdDTDSdCtMx : 2|2@1+ (1,0) [0|3] "" Vector__XXX
 SG_ MtGt6IvtPwLtdDTDSdCtM : 4|2@1+ (1,0) [0|3] "" Vector__XXX
 SG_ MtGt6IvtPwLtdDTDSdVtMx : 6|2@1+ (1,0) [0|3] "" Vector__XXX
 SG_ MtGt6IvtPwLtdDTDSdVtM : 8|2@1+ (1,0) [0|3] "" Vector__XXX
 SG_ MtGt6IvtPwLtdDTDSdPwMx : 14|2@1+ (1,0) [0|3] "" Vector__XXX
 SG_ MtGt6IvtPwLtdDTDSdPwM : 16|2@1+ (1,0) [0|3] "" Vector__XXX

BO_ 2365273854 MG5IR1: 8 Vector__XXX
 SG_ MtrGnrtr5InvrtrRfrn1Cntr : 8|4@1+ (1,0) [0|15] "" Vector__XXX
 SG_ MtrGnrtr5InvrtrRfrnTrq : 16|16@1+ (0.5,0) [0|32127.5] "Nm" Vector__XXX
 SG_ MtrGnrtr5InvrtrRfrnSpd : 32|16@1+ (4,0) [0|257020] "rpm" Vector__XXX
 SG_ MtrGnrtr5InvrtrRfrnPwr : 48|16@1+ (0.0625,0) [0|4015.9375] "kW" Vector__XXX
 SG_ MtrGnrtr5InvrtrRfrn1Cr : 0|8@1+ (1,0) [0|250] "count" Vector__XXX

BO_ 2365274110 MG5IS1: 8 Vector__XXX
 SG_ MtrGnrtr5InvrtrStts1Cntr : 8|4@1+ (1,0) [0|15] "" Vector__XXX
 SG_ MotorGenerator5Torque : 12|12@1+ (0.0625,-125) [-125|125.9375] "%" Vector__XXX
 SG_ MotorGenerator5Speed : 24|16@1+ (0.00390625,-125) [-125|125.99609375] "%" Vector__XXX
 SG_ MtrGnrtr5InvrtrStts1Cr : 0|8@1+ (1,0) [0|250] "count" Vector__XXX
 SG_ MtrGnrtr5InvrtrDSdCrrnt : 40|12@1+ (0.0625,-125) [-125|125.9375] "%" Vector__XXX
 SG_ MtrGnrtr5InvrtrDSdVltg : 52|12@1+ (0.0625,-125) [-125|125.9375] "%" Vector__XXX

BO_ 2365274366 MG5IR2: 8 Vector__XXX
 SG_ MtrGnrtr5InvrtrRfrn2Cntr : 8|4@1+ (1,0) [0|15] "" Vector__XXX
 SG_ MtrGnrtr5InvrtrRfrnCrrnt : 32|16@1+ (0.125,0) [0|8031.875] "A" Vector__XXX
 SG_ MtrGnrtr5InvrtrRfrnVltg : 48|16@1+ (0.125,0) [0|8031.875] "V" Vector__XXX
 SG_ MtrGnrtr5InvrtrRfrn2Cr : 0|8@1+ (1,0) [0|250] "count" Vector__XXX

BO_ 2566601214 MG5IT: 8 Vector__XXX
 SG_ MtrGnrtr5InvrtrTmprtr1 : 0|8@1+ (1,-40) [-40|210] "degC" Vector__XXX
 SG_ MtrGnrtr5InvrtrTmprtr2 : 8|8@1+ (1,-40) [-40|210] "degC" Vector__XXX
 SG_ MtrGnrtr5InvrtrTmprtr3 : 16|8@1+ (1,-40) [-40|210] "degC" Vector__XXX
 SG_ MtrGnrtr5InvrtrTmprtr4 : 24|8@1+ (1,-40) [-40|210] "degC" Vector__XXX
 SG_ MtrGnrtr5InvrtrTmprtr5 : 32|8@1+ (1,-40) [-40|210] "degC" Vector__XXX

BO_ 2566601470 MG5IMT: 8 Vector__XXX
 SG_ MotorGenerator5Temperature1 : 0|8@1+ (1,-40) [-40|210] "degC" Vector__XXX
 SG_ MotorGenerator5Temperature2 : 8|8@1+ (1,-40) [-40|210] "degC" Vector__XXX
 SG_ MotorGenerator5Temperature3 : 16|8@1+ (1,-40) [-40|210] "degC" Vector__XXX
 SG_ MotorGenerator5Temperature4 : 24|8@1+ (1,-40) [-40|210] "degC" Vector__XXX

BO_ 2566601726 MG5II: 8 Vector__XXX
 SG_ MtrGnrtr5InvrtrIsltnIntgrtCntr : 8|4@1+ (1,0) [0|15] "" Vector__XXX
 SG_ MtGt5IvtHVtBsAtvIstTstStts : 24|4@1+ (1,0) [0|15] "" Vector__XXX
 SG_ MtGt5IvtHVtBsPssvIstTstStts : 28|4@1+ (1,0) [0|15] "" Vector__XXX
 SG_ MtGt5IvtHVtBsAtvIstTstRsts : 32|16@1+ (0.1,0) [0|6425.5] "OhmPerV" Vector__XXX
 SG_ MtGt5IvtHVtBsPssvIstTstRsts : 48|16@1+ (0.1,0) [0|6425.5] "OhmPerV" Vector__XXX
 SG_ MtrGnrtr5InvrtrIsltnIntgrtCr : 0|8@1+ (1,0) [0|250] "count" Vector__XXX
 SG_ MtGt5IvtDSdNtvTCsssGdVt : 12|12@1+ (0.0625,-125) [-125|125.9375] "%" Vector__XXX

BO_ 2566601982 MG5IAPL: 8 Vector__XXX
 SG_ MtGt5IvtPwLtdDTUddRs : 0|2@1+ (1,0) [0|3] "" Vector__XXX
 SG_ MtGt5IvtPwLtdDTMPwMx : 10|2@1+ (1,0) [0|3] "" Vector__XXX
 SG_ MtGt5IvtPwLtdDTMPwM : 12|2@1+ (1,0) [0|3] "" Vector__XXX
 SG_ MtrGnrtr5InvrtrPwrLmtdDTTrqMxmm : 18|2@1+ (1,0) [0|3] "" Vector__XXX
 SG_ MtrGnrtr5InvrtrPwrLmtdDTTrqMnmm : 20|2@1+ (1,0) [0|3] "" Vector__XXX
 SG_ MtrGnrtr5InvrtrPwrLmtdDTSpdMxmm : 22|2@1+ (1,0) [0|3] "" Vector__XXX
 SG_ MtrGnrtr5InvrtrPwrLmtdDTSpdMnmm : 24|2@1+ (1,0) [0|3] "" Vector__XXX
 SG_ MtGt5IvtPwLtdDTIvtTpt : 28|2@1+ (1,0) [0|3] "" Vector__XXX
 SG_ MtGt5IvtPwLtdDTMtTpt : 30|2@1+ (1,0) [0|3] "" Vector__XXX
 SG_ MtGt5IvtPwLtdDTFtCdt : 32|2@1+ (1,0) [0|3] "" Vector__XXX
 SG_ MtGt5IvtPwLtdDTAtvTqRtLt : 34|2@1+ (1,0) [0|3] "" Vector__XXX
 SG_ MtGt5IvtPwLtdDTAtvSpdRtLt : 36|2@1+ (1,0) [0|3] "" Vector__XXX
 SG_ MtGt5IvtTqLtdDTMCtsts : 38|2@1+ (1,0) [0|3] "" Vector__XXX
 SG_ MtGt5IvtPwLtdDTDSdCtMx : 2|2@1+ (1,0) [0|3] "" Vector__XXX
 SG_ MtGt5IvtPwLtdDTDSdCtM : 4|2@1+ (1,0) [0|3] "" Vector__XXX
 SG_ MtGt5IvtPwLtdDTDSdVtMx : 6|2@1+ (1,0) [0|3] "" Vector__XXX
 SG_ MtGt5IvtPwLtdDTDSdVtM : 8|2@1+ (1,0) [0|3] "" Vector__XXX
 SG_ MtGt5IvtPwLtdDTDSdPwMx : 14|2@1+ (1,0) [0|3] "" Vector__XXX
 SG_ MtGt5IvtPwLtdDTDSdPwM : 16|2@1+ (1,0) [0|3] "" Vector__XXX

BO_ 2365275646 MG4IR1: 8 Vector__XXX
 SG_ MtrGnrtr4InvrtrRfrn1Cntr : 8|4@1+ (1,0) [0|15] "" Vector__XXX
 SG_ MtrGnrtr4InvrtrRfrnTrq : 16|16@1+ (0.5,0) [0|32127.5] "Nm" Vector__XXX
 SG_ MtrGnrtr4InvrtrRfrnSpd : 32|16@1+ (4,0) [0|257020] "rpm" Vector__XXX
 SG_ MtrGnrtr4InvrtrRfrnPwr : 48|16@1+ (0.0625,0) [0|4015.9375] "kW" Vector__XXX
 SG_ MtrGnrtr4InvrtrRfrn1Cr : 0|8@1+ (1,0) [0|250] "count" Vector__XXX

BO_ 2365275902 MG4IS1: 8 Vector__XXX
 SG_ MtrGnrtr4InvrtrStts1Cntr : 8|4@1+ (1,0) [0|15] "" Vector__XXX
 SG_ MotorGenerator4Torque : 12|12@1+ (0.0625,-125) [-125|125.9375] "%" Vector__XXX
 SG_ MotorGenerator4Speed : 24|16@1+ (0.00390625,-125) [-125|125.99609375] "%" Vector__XXX
 SG_ MtrGnrtr4InvrtrStts1Cr : 0|8@1+ (1,0) [0|250] "count" Vector__XXX
 SG_ MtrGnrtr4InvrtrDSdCrrnt : 40|12@1+ (0.0625,-125) [-125|125.9375] "%" Vector__XXX
 SG_ MtrGnrtr4InvrtrDSdVltg : 52|12@1+ (0.0625,-125) [-125|125.9375] "%" Vector__XXX

BO_ 2365276158 MG4IR2: 8 Vector__XXX
 SG_ MtrGnrtr4InvrtrRfrn2Cntr : 8|4@1+ (1,0) [0|15] "" Vector__XXX
 SG_ MtrGnrtr4InvrtrRfrnCrrnt : 32|16@1+ (0.125,0) [0|8031.875] "A" Vector__XXX
 SG_ MtrGnrtr4InvrtrRfrnVltg : 48|16@1+ (0.125,0) [0|8031.875] "V" Vector__XXX
 SG_ MtrGnrtr4InvrtrRfrn2Cr : 0|8@1+ (1,0) [0|250] "count" Vector__XXX

BO_ 2566603006 MG4IT: 8 Vector__XXX
 SG_ MtrGnrtr4InvrtrTmprtr1 : 0|8@1+ (1,-40) [-40|210] "degC" Vector__XXX
 SG_ MtrGnrtr4InvrtrTmprtr2 : 8|8@1+ (1,-40) [-40|210] "degC" Vector__XXX
 SG_ MtrGnrtr4InvrtrTmprtr3 : 16|8@1+ (1,-40) [-40|210] "degC" Vector__XXX
 SG_ MtrGnrtr4InvrtrTmprtr4 : 24|8@1+ (1,-40) [-40|210] "degC" Vector__XXX
 SG_ MtrGnrtr4InvrtrTmprtr5 : 32|8@1+ (1,-40) [-40|210] "degC" Vector__XXX

BO_ 2566603262 MG4IMT: 8 Vector__XXX
 SG_ MotorGenerator4Temperature1 : 0|8@1+ (1,-40) [-40|210] "degC" Vector__XXX
 SG_ MotorGenerator4Temperature2 : 8|8@1+ (1,-40) [-40|210] "degC" Vector__XXX
 SG_ MotorGenerator4Temperature3 : 16|8@1+ (1,-40) [-40|210] "degC" Vector__XXX
 SG_ MotorGenerator4Temperature4 : 24|8@1+ (1,-40) [-40|210] "degC" Vector__XXX

BO_ 2566603518 MG4II: 8 Vector__XXX
 SG_ MtrGnrtr4InvrtrIsltnIntgrtCntr : 8|4@1+ (1,0) [0|15] "" Vector__XXX
 SG_ MtGt4IvtHVtBsAtvIstTstStts : 24|4@1+ (1,0) [0|15] "" Vector__XXX
 SG_ MtGt4IvtHVtBsPssvIstTstStts : 28|4@1+ (1,0) [0|15] "" Vector__XXX
 SG_ MtGt4IvtHVtBsAtvIstTstRsts : 32|16@1+ (0.1,0) [0|6425.5] "OhmPerV" Vector__XXX
 SG_ MtGt4IvtHVtBsPssvIstTstRsts : 48|16@1+ (0.1,0) [0|6425.5] "OhmPerV" Vector__XXX
 SG_ MtrGnrtr4InvrtrIsltnIntgrtCr : 0|8@1+ (1,0) [0|250] "count" Vector__XXX
 SG_ MtGt4IvtDSdNtvTCsssGdVt : 12|12@1+ (0.0625,-125) [-125|125.9375] "%" Vector__XXX

BO_ 2566603774 MG4IAPL: 8 Vector__XXX
 SG_ MtGt4IvtPwLtdDTUddRs : 0|2@1+ (1,0) [0|3] "" Vector__XXX
 SG_ MtGt4IvtPwLtdDTMPwMx : 10|2@1+ (1,0) [0|3] "" Vector__XXX
 SG_ MtGt4IvtPwLtdDTMPwM : 12|2@1+ (1,0) [0|3] "" Vector__XXX
 SG_ MtrGnrtr4InvrtrPwrLmtdDTTrqMxmm : 18|2@1+ (1,0) [0|3] "" Vector__XXX
 SG_ MtrGnrtr4InvrtrPwrLmtdDTTrqMnmm : 20|2@1+ (1,0) [0|3] "" Vector__XXX
 SG_ MtrGnrtr4InvrtrPwrLmtdDTSpdMxmm : 22|2@1+ (1,0) [0|3] "" Vector__XXX
 SG_ MtrGnrtr4InvrtrPwrLmtdDTSpdMnmm : 24|2@1+ (1,0) [0|3] "" Vector__XXX
 SG_ MtGt4IvtPwLtdDTIvtTpt : 28|2@1+ (1,0) [0|3] "" Vector__XXX
 SG_ MtGt4IvtPwLtdDTMtTpt : 30|2@1+ (1,0) [0|3] "" Vector__XXX
 SG_ MtGt4IvtPwLtdDTFtCdt : 32|2@1+ (1,0) [0|3] "" Vector__XXX
 SG_ MtGt4IvtPwLtdDTAtvTqRtLt : 34|2@1+ (1,0) [0|3] "" Vector__XXX
 SG_ MtGt4IvtPwLtdDTAtvSpdRtLt : 36|2@1+ (1,0) [0|3] "" Vector__XXX
 SG_ MtGt4IvtTqLtdDTMCtsts : 38|2@1+ (1,0) [0|3] "" Vector__XXX
 SG_ MtGt4IvtPwLtdDTDSdCtMx : 2|2@1+ (1,0) [0|3] "" Vector__XXX
 SG_ MtGt4IvtPwLtdDTDSdCtM : 4|2@1+ (1,0) [0|3] "" Vector__XXX
 SG_ MtGt4IvtPwLtdDTDSdVtMx : 6|2@1+ (1,0) [0|3] "" Vector__XXX
 SG_ MtGt4IvtPwLtdDTDSdVtM : 8|2@1+ (1,0) [0|3] "" Vector__XXX
 SG_ MtGt4IvtPwLtdDTDSdPwMx : 14|2@1+ (1,0) [0|3] "" Vector__XXX
 SG_ MtGt4IvtPwLtdDTDSdPwM : 16|2@1+ (1,0) [0|3] "" Vector__XXX

BO_ 2365277438 MG3IR1: 8 Vector__XXX
 SG_ MtrGnrtr3InvrtrRfrn1Cntr : 8|4@1+ (1,0) [0|15] "" Vector__XXX
 SG_ MtrGnrtr3InvrtrRfrnTrq : 16|16@1+ (0.5,0) [0|32127.5] "Nm" Vector__XXX
 SG_ MtrGnrtr3InvrtrRfrnSpd : 32|16@1+ (4,0) [0|257020] "rpm" Vector__XXX
 SG_ MtrGnrtr3InvrtrRfrnPwr : 48|16@1+ (0.0625,0) [0|4015.9375] "kW" Vector__XXX
 SG_ MtrGnrtr3InvrtrRfrn1Cr : 0|8@1+ (1,0) [0|250] "count" Vector__XXX

BO_ 2365277694 MG3IS1: 8 Vector__XXX
 SG_ MtrGnrtr3InvrtrStts1Cntr : 8|4@1+ (1,0) [0|15] "" Vector__XXX
 SG_ MotorGenerator3Torque : 12|12@1+ (0.0625,-125) [-125|125.9375] "%" Vector__XXX
 SG_ MotorGenerator3Speed : 24|16@1+ (0.00390625,-125) [-125|125.99609375] "%" Vector__XXX
 SG_ MtrGnrtr3InvrtrStts1Cr : 0|8@1+ (1,0) [0|250] "count" Vector__XXX
 SG_ MtrGnrtr3InvrtrDSdCrrnt : 40|12@1+ (0.0625,-125) [-125|125.9375] "%" Vector__XXX
 SG_ MtrGnrtr3InvrtrDSdVltg : 52|12@1+ (0.0625,-125) [-125|125.9375] "%" Vector__XXX

BO_ 2365277950 MG3IR2: 8 Vector__XXX
 SG_ MtrGnrtr3InvrtrRfrn2Cntr : 8|4@1+ (1,0) [0|15] "" Vector__XXX
 SG_ MtrGnrtr3InvrtrRfrnCrrnt : 32|16@1+ (0.125,0) [0|8031.875] "A" Vector__XXX
 SG_ MtrGnrtr3InvrtrRfrnVltg : 48|16@1+ (0.125,0) [0|8031.875] "V" Vector__XXX
 SG_ MtrGnrtr3InvrtrRfrn2Cr : 0|8@1+ (1,0) [0|250] "count" Vector__XXX

BO_ 2566604798 MG3IT: 8 Vector__XXX
 SG_ MtrGnrtr3InvrtrTmprtr1 : 0|8@1+ (1,-40) [-40|210] "degC" Vector__XXX
 SG_ MtrGnrtr3InvrtrTmprtr2 : 8|8@1+ (1,-40) [-40|210] "degC" Vector__XXX
 SG_ MtrGnrtr3InvrtrTmprtr3 : 16|8@1+ (1,-40) [-40|210] "degC" Vector__XXX
 SG_ MtrGnrtr3InvrtrTmprtr4 : 24|8@1+ (1,-40) [-40|210] "degC" Vector__XXX
 SG_ MtrGnrtr3InvrtrTmprtr5 : 32|8@1+ (1,-40) [-40|210] "degC" Vector__XXX

BO_ 2566605054 MG3IMT: 8 Vector__XXX
 SG_ MotorGenerator3Temperature1 : 0|8@1+ (1,-40) [-40|210] "degC" Vector__XXX
 SG_ MotorGenerator3Temperature2 : 8|8@1+ (1,-40) [-40|210] "degC" Vector__XXX
 SG_ MotorGenerator3Temperature3 : 16|8@1+ (1,-40) [-40|210] "degC" Vector__XXX
 SG_ MotorGenerator3Temperature4 : 24|8@1+ (1,-40) [-40|210] "degC" Vector__XXX

BO_ 2566605310 MG3II: 8 Vector__XXX
 SG_ MtrGnrtr3InvrtrIsltnIntgrtCntr : 8|4@1+ (1,0) [0|15] "" Vector__XXX
 SG_ MtGt3IvtHVtBsAtvIstTstStts : 24|4@1+ (1,0) [0|15] "" Vector__XXX
 SG_ MtGt3IvtHVtBsPssvIstTstStts : 28|4@1+ (1,0) [0|15] "" Vector__XXX
 SG_ MtGt3IvtHVtBsAtvIstTstRsts : 32|16@1+ (0.1,0) [0|6425.5] "OhmPerV" Vector__XXX
 SG_ MtGt3IvtHVtBsPssvIstTstRsts : 48|16@1+ (0.1,0) [0|6425.5] "OhmPerV" Vector__XXX
 SG_ MtrGnrtr3InvrtrIsltnIntgrtCr : 0|8@1+ (1,0) [0|250] "count" Vector__XXX
 SG_ MtGt3IvtDSdNtvTCsssGdVt : 12|12@1+ (0.0625,-125) [-125|125.9375] "%" Vector__XXX

BO_ 2566605566 MG3IAPL: 8 Vector__XXX
 SG_ MtGt3IvtPwLtdDTUddRs : 0|2@1+ (1,0) [0|3] "" Vector__XXX
 SG_ MtGt3IvtPwLtdDTMPwMx : 10|2@1+ (1,0) [0|3] "" Vector__XXX
 SG_ MtGt3IvtPwLtdDTMPwM : 12|2@1+ (1,0) [0|3] "" Vector__XXX
 SG_ MtrGnrtr3InvrtrPwrLmtdDTTrqMxmm : 18|2@1+ (1,0) [0|3] "" Vector__XXX
 SG_ MtrGnrtr3InvrtrPwrLmtdDTTrqMnmm : 20|2@1+ (1,0) [0|3] "" Vector__XXX
 SG_ MtrGnrtr3InvrtrPwrLmtdDTSpdMxmm : 22|2@1+ (1,0) [0|3] "" Vector__XXX
 SG_ MtrGnrtr3InvrtrPwrLmtdDTSpdMnmm : 24|2@1+ (1,0) [0|3] "" Vector__XXX
 SG_ MtGt3IvtPwLtdDTIvtTpt : 28|2@1+ (1,0) [0|3] "" Vector__XXX
 SG_ MtGt3IvtPwLtdDTMtTpt : 30|2@1+ (1,0) [0|3] "" Vector__XXX
 SG_ MtGt3IvtPwLtdDTFtCdt : 32|2@1+ (1,0) [0|3] "" Vector__XXX
 SG_ MtGt3IvtPwLtdDTAtvTqRtLt : 34|2@1+ (1,0) [0|3] "" Vector__XXX
 SG_ MtGt3IvtPwLtdDTAtvSpdRtLt : 36|2@1+ (1,0) [0|3] "" Vector__XXX
 SG_ MtGt3IvtTqLtdDTMCtsts : 38|2@1+ (1,0) [0|3] "" Vector__XXX
 SG_ MtGt3IvtPwLtdDTDSdCtMx : 2|2@1+ (1,0) [0|3] "" Vector__XXX
 SG_ MtGt3IvtPwLtdDTDSdCtM : 4|2@1+ (1,0) [0|3] "" Vector__XXX
 SG_ MtGt3IvtPwLtdDTDSdVtMx : 6|2@1+ (1,0) [0|3] "" Vector__XXX
 SG_ MtGt3IvtPwLtdDTDSdVtM : 8|2@1+ (1,0) [0|3] "" Vector__XXX
 SG_ MtGt3IvtPwLtdDTDSdPwMx : 14|2@1+ (1,0) [0|3] "" Vector__XXX
 SG_ MtGt3IvtPwLtdDTDSdPwM : 16|2@1+ (1,0) [0|3] "" Vector__XXX

BO_ 2566605822 ADSS1: 8 Vector__XXX
 SG_ SAddssOCtDvFTs1CtPpsP7 : 0|8@1+ (1,0) [0|250] "sourceadr" Vector__XXX
 SG_ Ts1CntrlPrpsP7RdnssStts : 8|2@1+ (1,0) [0|3] "" Vector__XXX
 SG_ AdsVhlSpdCntrlCmmndRdnssStts : 10|2@1+ (1,0) [0|3] "" Vector__XXX
 SG_ SAddssOCtDvFAdsVSpdCtCd : 16|8@1+ (1,0) [0|250] "sourceadr" Vector__XXX
 SG_ AdsVhlSpdCntrlCmmndFdk : 24|16@1+ (0.00390625,0) [0|250.99609375] "km/h" Vector__XXX
 SG_ AdsVhlSpdCntrlOprtnStts : 12|3@1+ (1,0) [0|7] "" Vector__XXX
 SG_ Adss1EmbeddedIntegritySupport : 50|2@1+ (1,0) [0|3] "" Vector__XXX
 SG_ Adss1Counter : 52|4@1+ (1,0) [0|15] "" Vector__XXX
 SG_ Adss1Crc : 56|8@1+ (1,0) [0|250] "count" Vector__XXX

BO_ 2566606078 CCSI2: 8 Vector__XXX
 SG_ CabHeaterPower : 0|16@1+ (2,0) [0|128510] "W" Vector__XXX
 SG_ CabACCompressorPower : 16|16@1+ (0.5,0) [0|32127.5] "W" Vector__XXX

BO_ 2566606334 MI1: 8 Vector__XXX
 SG_ EngineAirFilter1LifeRemaining : 0|8@1+ (0.4,0) [0|100] "%" Vector__XXX
 SG_ EngineAirFilter2LifeRemaining : 8|8@1+ (0.4,0) [0|100] "%" Vector__XXX
 SG_ EngineAirFilter3LifeRemaining : 16|8@1+ (0.4,0) [0|100] "%" Vector__XXX
 SG_ EngineAirFilter4LifeRemaining : 24|8@1+ (0.4,0) [0|100] "%" Vector__XXX
 SG_ EngineFuelFilterLifeRemaining : 32|8@1+ (0.4,0) [0|100] "%" Vector__XXX
 SG_ EngnFlFltrStnSdLfRmnng : 40|8@1+ (0.4,0) [0|100] "%" Vector__XXX
 SG_ EngineOilFilterLifeRemaining : 48|8@1+ (0.4,0) [0|100] "%" Vector__XXX
 SG_ TrnsmssnOlFltrLfRmnng : 56|8@1+ (0.4,0) [0|100] "%" Vector__XXX

BO_ 2499497726 HCI1: 8 Vector__XXX
 SG_ HoistLeverPosition : 0|16@1+ (0.005,-150) [-100|100] "%" Vector__XXX
 SG_ HoistLeverDetentPositionStatus : 16|2@1+ (1,0) [0|3] "" Vector__XXX

BO_ 2633715710 HVESP6HIST: 19 Vector__XXX
 SG_ Hvesp6StateOfHealth : 0|8@1+ (0.4,0) [0|100] "%" Vector__XXX
 SG_ Hvesp6TotalEnergyThroughput : 24|32@1+ (100,0) [0|421108121500] "Watt-hour" Vector__XXX
 SG_ Hvesp6TotalAccumulatedCharge : 56|32@1+ (100,0) [0|421108121500] "Ah" Vector__XXX
 SG_ Hvesp6TotalLifetimeEnergyInput : 88|32@1+ (1,0) [0|4211081215] "kWh" Vector__XXX
 SG_ Hvesp6TotalLifetimeEnergyOutput : 120|32@1+ (1,0) [0|4211081215] "kWh" Vector__XXX
 SG_ Hvsp6CnttrOpnUndrLdCnt : 8|16@1+ (1,0) [0|64255] "count" Vector__XXX

BO_ 2566607102 HVESP6CFG: 19 Vector__XXX
 SG_ Hvesp6NominalVoltage : 0|16@1+ (0.05,0) [0|3212.75] "V" Vector__XXX
 SG_ Hvesp6CellMaximumVoltageLimit : 112|8@1+ (0.02044,0) [0|5.11] "V" Vector__XXX
 SG_ Hvesp6CellMinimumVoltageLimit : 120|8@1+ (0.02044,0) [0|5.11] "V" Vector__XXX
 SG_ Hvsp6RmmnddMnmmOprtngVltg : 16|16@1+ (0.05,0) [0|3212.75] "V" Vector__XXX
 SG_ Hvsp6RmmnddMxmmOprtngVltg : 32|16@1+ (0.05,0) [0|3212.75] "V" Vector__XXX
 SG_ Hvsp6RmmnddMnmmSttOfChrg : 48|16@1+ (0.0015625,0) [0|100.3984375] "%" Vector__XXX
 SG_ Hvsp6RmmnddMxmmSttOfChrg : 64|16@1+ (0.0015625,0) [0|100.3984375] "%" Vector__XXX
 SG_ Hvsp6RmmnddMxmmOprtngTmprtr : 80|16@1+ (0.03125,-273) [-273|1734.96875] "degC" Vector__XXX
 SG_ Hvsp6RmmnddMnmmOprtngTmprtr : 96|16@1+ (0.03125,-273) [-273|1734.96875] "degC" Vector__XXX
 SG_ Hvesp6NominalRatedCapacity : 128|24@1+ (0.001,0) [0|16449.535] "kWh" Vector__XXX

BO_ 2633716222 HVESP5HIST: 19 Vector__XXX
 SG_ Hvesp5StateOfHealth : 0|8@1+ (0.4,0) [0|100] "%" Vector__XXX
 SG_ Hvesp5TotalEnergyThroughput : 24|32@1+ (100,0) [0|421108121500] "Watt-hour" Vector__XXX
 SG_ Hvesp5TotalAccumulatedCharge : 56|32@1+ (100,0) [0|421108121500] "Ah" Vector__XXX
 SG_ Hvesp5TotalLifetimeEnergyInput : 88|32@1+ (1,0) [0|4211081215] "kWh" Vector__XXX
 SG_ Hvesp5TotalLifetimeEnergyOutput : 120|32@1+ (1,0) [0|4211081215] "kWh" Vector__XXX
 SG_ Hvsp5CnttrOpnUndrLdCnt : 8|16@1+ (1,0) [0|64255] "count" Vector__XXX

BO_ 2566607614 HVESP5CFG: 19 Vector__XXX
 SG_ Hvesp5NominalVoltage : 0|16@1+ (0.05,0) [0|3212.75] "V" Vector__XXX
 SG_ Hvesp5CellMaximumVoltageLimit : 112|8@1+ (0.02044,0) [0|5.11] "V" Vector__XXX
 SG_ Hvesp5CellMinimumVoltageLimit : 120|8@1+ (0.02044,0) [0|5.11] "V" Vector__XXX
 SG_ Hvsp5RmmnddMnmmOprtngVltg : 16|16@1+ (0.05,0) [0|3212.75] "V" Vector__XXX
 SG_ Hvsp5RmmnddMxmmOprtngVltg : 32|16@1+ (0.05,0) [0|3212.75] "V" Vector__XXX
 SG_ Hvsp5RmmnddMnmmSttOfChrg : 48|16@1+ (0.0015625,0) [0|100.3984375] "%" Vector__XXX
 SG_ Hvsp5RmmnddMxmmSttOfChrg : 64|16@1+ (0.0015625,0) [0|100.3984375] "%" Vector__XXX
 SG_ Hvsp5RmmnddMxmmOprtngTmprtr : 80|16@1+ (0.03125,-273) [-273|1734.96875] "degC" Vector__XXX
 SG_ Hvsp5RmmnddMnmmOprtngTmprtr : 96|16@1+ (0.03125,-273) [-273|1734.96875] "degC" Vector__XXX
 SG_ Hvesp5NominalRatedCapacity : 128|24@1+ (0.001,0) [0|16449.535] "kWh" Vector__XXX

BO_ 2633716734 HVESP4HIST: 19 Vector__XXX
 SG_ Hvesp4StateOfHealth : 0|8@1+ (0.4,0) [0|100] "%" Vector__XXX
 SG_ Hvesp4TotalEnergyThroughput : 24|32@1+ (100,0) [0|421108121500] "Watt-hour" Vector__XXX
 SG_ Hvesp4TotalAccumulatedCharge : 56|32@1+ (100,0) [0|421108121500] "Ah" Vector__XXX
 SG_ Hvesp4TotalLifetimeEnergyInput : 88|32@1+ (1,0) [0|4211081215] "kWh" Vector__XXX
 SG_ Hvesp4TotalLifetimeEnergyOutput : 120|32@1+ (1,0) [0|4211081215] "kWh" Vector__XXX
 SG_ Hvsp4CnttrOpnUndrLdCnt : 8|16@1+ (1,0) [0|64255] "count" Vector__XXX

BO_ 2566608126 HVESP4CFG: 19 Vector__XXX
 SG_ Hvesp4NominalVoltage : 0|16@1+ (0.05,0) [0|3212.75] "V" Vector__XXX
 SG_ Hvesp4CellMaximumVoltageLimit : 112|8@1+ (0.02044,0) [0|5.11] "V" Vector__XXX
 SG_ Hvesp4CellMinimumVoltageLimit : 120|8@1+ (0.02044,0) [0|5.11] "V" Vector__XXX
 SG_ Hvsp4RmmnddMnmmOprtngVltg : 16|16@1+ (0.05,0) [0|3212.75] "V" Vector__XXX
 SG_ Hvsp4RmmnddMxmmOprtngVltg : 32|16@1+ (0.05,0) [0|3212.75] "V" Vector__XXX
 SG_ Hvsp4RmmnddMnmmSttOfChrg : 48|16@1+ (0.0015625,0) [0|100.3984375] "%" Vector__XXX
 SG_ Hvsp4RmmnddMxmmSttOfChrg : 64|16@1+ (0.0015625,0) [0|100.3984375] "%" Vector__XXX
 SG_ Hvsp4RmmnddMxmmOprtngTmprtr : 80|16@1+ (0.03125,-273) [-273|1734.96875] "degC" Vector__XXX
 SG_ Hvsp4RmmnddMnmmOprtngTmprtr : 96|16@1+ (0.03125,-273) [-273|1734.96875] "degC" Vector__XXX
 SG_ Hvesp4NominalRatedCapacity : 128|24@1+ (0.001,0) [0|16449.535] "kWh" Vector__XXX

BO_ 2633717246 HVESP3HIST: 19 Vector__XXX
 SG_ Hvesp3StateOfHealth : 0|8@1+ (0.4,0) [0|100] "%" Vector__XXX
 SG_ Hvesp3TotalEnergyThroughput : 24|32@1+ (100,0) [0|421108121500] "Watt-hour" Vector__XXX
 SG_ Hvesp3TotalAccumulatedCharge : 56|32@1+ (100,0) [0|421108121500] "Ah" Vector__XXX
 SG_ Hvesp3TotalLifetimeEnergyInput : 88|32@1+ (1,0) [0|4211081215] "kWh" Vector__XXX
 SG_ Hvesp3TotalLifetimeEnergyOutput : 120|32@1+ (1,0) [0|4211081215] "kWh" Vector__XXX
 SG_ Hvsp3CnttrOpnUndrLdCnt : 8|16@1+ (1,0) [0|64255] "count" Vector__XXX

BO_ 2566608638 HVESP3CFG: 19 Vector__XXX
 SG_ Hvesp3NominalVoltage : 0|16@1+ (0.05,0) [0|3212.75] "V" Vector__XXX
 SG_ Hvesp3CellMaximumVoltageLimit : 112|8@1+ (0.02044,0) [0|5.11] "V" Vector__XXX
 SG_ Hvesp3CellMinimumVoltageLimit : 120|8@1+ (0.02044,0) [0|5.11] "V" Vector__XXX
 SG_ Hvsp3RmmnddMnmmOprtngVltg : 16|16@1+ (0.05,0) [0|3212.75] "V" Vector__XXX
 SG_ Hvsp3RmmnddMxmmOprtngVltg : 32|16@1+ (0.05,0) [0|3212.75] "V" Vector__XXX
 SG_ Hvsp3RmmnddMnmmSttOfChrg : 48|16@1+ (0.0015625,0) [0|100.3984375] "%" Vector__XXX
 SG_ Hvsp3RmmnddMxmmSttOfChrg : 64|16@1+ (0.0015625,0) [0|100.3984375] "%" Vector__XXX
 SG_ Hvsp3RmmnddMxmmOprtngTmprtr : 80|16@1+ (0.03125,-273) [-273|1734.96875] "degC" Vector__XXX
 SG_ Hvsp3RmmnddMnmmOprtngTmprtr : 96|16@1+ (0.03125,-273) [-273|1734.96875] "degC" Vector__XXX
 SG_ Hvesp3NominalRatedCapacity : 128|24@1+ (0.001,0) [0|16449.535] "kWh" Vector__XXX

BO_ 2633717758 HVESP2HIST: 19 Vector__XXX
 SG_ Hvesp2StateOfHealth : 0|8@1+ (0.4,0) [0|100] "%" Vector__XXX
 SG_ Hvesp2TotalEnergyThroughput : 24|32@1+ (100,0) [0|421108121500] "Watt-hour" Vector__XXX
 SG_ Hvesp2TotalAccumulatedCharge : 56|32@1+ (100,0) [0|421108121500] "Ah" Vector__XXX
 SG_ Hvesp2TotalLifetimeEnergyInput : 88|32@1+ (1,0) [0|4211081215] "kWh" Vector__XXX
 SG_ Hvesp2TotalLifetimeEnergyOutput : 120|32@1+ (1,0) [0|4211081215] "kWh" Vector__XXX
 SG_ Hvsp2CnttrOpnUndrLdCnt : 8|16@1+ (1,0) [0|64255] "count" Vector__XXX

BO_ 2566609150 HVESP2CFG: 19 Vector__XXX
 SG_ Hvesp2NominalVoltage : 0|16@1+ (0.05,0) [0|3212.75] "V" Vector__XXX
 SG_ Hvesp2CellMaximumVoltageLimit : 112|8@1+ (0.02044,0) [0|5.11] "V" Vector__XXX
 SG_ Hvesp2CellMinimumVoltageLimit : 120|8@1+ (0.02044,0) [0|5.11] "V" Vector__XXX
 SG_ Hvsp2RmmnddMnmmOprtngVltg : 16|16@1+ (0.05,0) [0|3212.75] "V" Vector__XXX
 SG_ Hvsp2RmmnddMxmmOprtngVltg : 32|16@1+ (0.05,0) [0|3212.75] "V" Vector__XXX
 SG_ Hvsp2RmmnddMnmmSttOfChrg : 48|16@1+ (0.0015625,0) [0|100.3984375] "%" Vector__XXX
 SG_ Hvsp2RmmnddMxmmSttOfChrg : 64|16@1+ (0.0015625,0) [0|100.3984375] "%" Vector__XXX
 SG_ Hvsp2RmmnddMxmmOprtngTmprtr : 80|16@1+ (0.03125,-273) [-273|1734.96875] "degC" Vector__XXX
 SG_ Hvsp2RmmnddMnmmOprtngTmprtr : 96|16@1+ (0.03125,-273) [-273|1734.96875] "degC" Vector__XXX
 SG_ Hvesp2NominalRatedCapacity : 128|24@1+ (0.001,0) [0|16449.535] "kWh" Vector__XXX

BO_ 2633718270 HVESP1HIST: 19 Vector__XXX
 SG_ Hvesp1StateOfHealth : 0|8@1+ (0.4,0) [0|100] "%" Vector__XXX
 SG_ Hvesp1TotalEnergyThroughput : 24|32@1+ (100,0) [0|421108121500] "Watt-hour" Vector__XXX
 SG_ Hvesp1TotalAccumulatedCharge : 56|32@1+ (100,0) [0|421108121500] "Ah" Vector__XXX
 SG_ Hvesp1TotalLifetimeEnergyInput : 88|32@1+ (1,0) [0|4211081215] "kWh" Vector__XXX
 SG_ Hvesp1TotalLifetimeEnergyOutput : 120|32@1+ (1,0) [0|4211081215] "kWh" Vector__XXX
 SG_ Hvsp1CnttrOpnUndrLdCnt : 8|16@1+ (1,0) [0|64255] "count" Vector__XXX

BO_ 2566609662 HVESP1CFG: 19 Vector__XXX
 SG_ Hvesp1NominalVoltage : 0|16@1+ (0.05,0) [0|3212.75] "V" Vector__XXX
 SG_ Hvesp1CellMaximumVoltageLimit : 112|8@1+ (0.02044,0) [0|5.11] "V" Vector__XXX
 SG_ Hvesp1CellMinimumVoltageLimit : 120|8@1+ (0.02044,0) [0|5.11] "V" Vector__XXX
 SG_ Hvsp1RmmnddMnmmOprtngVltg : 16|16@1+ (0.05,0) [0|3212.75] "V" Vector__XXX
 SG_ Hvsp1RmmnddMxmmOprtngVltg : 32|16@1+ (0.05,0) [0|3212.75] "V" Vector__XXX
 SG_ Hvsp1RmmnddMnmmSttOfChrg : 48|16@1+ (0.0015625,0) [0|100.3984375] "%" Vector__XXX
 SG_ Hvsp1RmmnddMxmmSttOfChrg : 64|16@1+ (0.0015625,0) [0|100.3984375] "%" Vector__XXX
 SG_ Hvsp1RmmnddMxmmOprtngTmprtr : 80|16@1+ (0.03125,-273) [-273|1734.96875] "degC" Vector__XXX
 SG_ Hvsp1RmmnddMnmmOprtngTmprtr : 96|16@1+ (0.03125,-273) [-273|1734.96875] "degC" Vector__XXX
 SG_ Hvesp1NominalRatedCapacity : 128|24@1+ (0.001,0) [0|16449.535] "kWh" Vector__XXX

BO_ 2633718782 VFSSM1DET: 24 Vector__XXX
 SG_ VfssMdl1Dttr1DttrTp : 0|4@1+ (1,0) [0|15] "" Vector__XXX
 SG_ VfssMdl1Dttr2DttrTp : 24|4@1+ (1,0) [0|15] "" Vector__XXX
 SG_ VfssMdl1Dttr3DttrTp : 48|4@1+ (1,0) [0|15] "" Vector__XXX
 SG_ VfssMdl1Dttr4DttrTp : 72|4@1+ (1,0) [0|15] "" Vector__XXX
 SG_ VfssMdl1Dttr5DttrTp : 96|4@1+ (1,0) [0|15] "" Vector__XXX
 SG_ VfssMdl1Dttr6DttrTp : 120|4@1+ (1,0) [0|15] "" Vector__XXX
 SG_ VfssMdl1Dttr7DttrTp : 144|4@1+ (1,0) [0|15] "" Vector__XXX
 SG_ VfssMdl1Dttr8DttrTp : 168|4@1+ (1,0) [0|15] "" Vector__XXX
 SG_ VfssMdl1Dttr1DttrDtSlt : 4|4@1+ (1,0) [0|15] "" Vector__XXX
 SG_ VfssMdl1Dttr2DttrDtSlt : 28|4@1+ (1,0) [0|15] "" Vector__XXX
 SG_ VfssMdl1Dttr3DttrDtSlt : 52|4@1+ (1,0) [0|15] "" Vector__XXX
 SG_ VfssMdl1Dttr4DttrDtSlt : 76|4@1+ (1,0) [0|15] "" Vector__XXX
 SG_ VfssMdl1Dttr5DttrDtSlt : 100|4@1+ (1,0) [0|15] "" Vector__XXX
 SG_ VfssMdl1Dttr6DttrDtSlt : 124|4@1+ (1,0) [0|15] "" Vector__XXX
 SG_ VfssMdl1Dttr7DttrDtSlt : 148|4@1+ (1,0) [0|15] "" Vector__XXX
 SG_ VfssMdl1Dttr8DttrDtSlt : 172|4@1+ (1,0) [0|15] "" Vector__XXX

BO_ 2633719038 VFSSM2DET: 24 Vector__XXX
 SG_ VfssMdl2Dttr1DttrTp : 0|4@1+ (1,0) [0|15] "" Vector__XXX
 SG_ VfssMdl2Dttr2DttrTp : 24|4@1+ (1,0) [0|15] "" Vector__XXX
 SG_ VfssMdl2Dttr3DttrTp : 48|4@1+ (1,0) [0|15] "" Vector__XXX
 SG_ VfssMdl2Dttr4DttrTp : 72|4@1+ (1,0) [0|15] "" Vector__XXX
 SG_ VfssMdl2Dttr5DttrTp : 96|4@1+ (1,0) [0|15] "" Vector__XXX
 SG_ VfssMdl2Dttr6DttrTp : 120|4@1+ (1,0) [0|15] "" Vector__XXX
 SG_ VfssMdl2Dttr7DttrTp : 144|4@1+ (1,0) [0|15] "" Vector__XXX
 SG_ VfssMdl2Dttr8DttrTp : 168|4@1+ (1,0) [0|15] "" Vector__XXX
 SG_ VfssMdl2Dttr1DttrDtSlt : 4|4@1+ (1,0) [0|15] "" Vector__XXX
 SG_ VfssMdl2Dttr2DttrDtSlt : 28|4@1+ (1,0) [0|15] "" Vector__XXX
 SG_ VfssMdl2Dttr3DttrDtSlt : 52|4@1+ (1,0) [0|15] "" Vector__XXX
 SG_ VfssMdl2Dttr4DttrDtSlt : 76|4@1+ (1,0) [0|15] "" Vector__XXX
 SG_ VfssMdl2Dttr5DttrDtSlt : 100|4@1+ (1,0) [0|15] "" Vector__XXX
 SG_ VfssMdl2Dttr6DttrDtSlt : 124|4@1+ (1,0) [0|15] "" Vector__XXX
 SG_ VfssMdl2Dttr7DttrDtSlt : 148|4@1+ (1,0) [0|15] "" Vector__XXX
 SG_ VfssMdl2Dttr8DttrDtSlt : 172|4@1+ (1,0) [0|15] "" Vector__XXX

BO_ 2633719294 VFSSM3DET: 24 Vector__XXX
 SG_ VfssMdl3Dttr1DttrTp : 0|4@1+ (1,0) [0|15] "" Vector__XXX
 SG_ VfssMdl3Dttr2DttrTp : 24|4@1+ (1,0) [0|15] "" Vector__XXX
 SG_ VfssMdl3Dttr3DttrTp : 48|4@1+ (1,0) [0|15] "" Vector__XXX
 SG_ VfssMdl3Dttr4DttrTp : 72|4@1+ (1,0) [0|15] "" Vector__XXX
 SG_ VfssMdl3Dttr5DttrTp : 96|4@1+ (1,0) [0|15] "" Vector__XXX
 SG_ VfssMdl3Dttr6DttrTp : 120|4@1+ (1,0) [0|15] "" Vector__XXX
 SG_ VfssMdl3Dttr7DttrTp : 144|4@1+ (1,0) [0|15] "" Vector__XXX
 SG_ VfssMdl3Dttr8DttrTp : 168|4@1+ (1,0) [0|15] "" Vector__XXX
 SG_ VfssMdl3Dttr1DttrDtSlt : 4|4@1+ (1,0) [0|15] "" Vector__XXX
 SG_ VfssMdl3Dttr2DttrDtSlt : 28|4@1+ (1,0) [0|15] "" Vector__XXX
 SG_ VfssMdl3Dttr3DttrDtSlt : 52|4@1+ (1,0) [0|15] "" Vector__XXX
 SG_ VfssMdl3Dttr4DttrDtSlt : 76|4@1+ (1,0) [0|15] "" Vector__XXX
 SG_ VfssMdl3Dttr5DttrDtSlt : 100|4@1+ (1,0) [0|15] "" Vector__XXX
 SG_ VfssMdl3Dttr6DttrDtSlt : 124|4@1+ (1,0) [0|15] "" Vector__XXX
 SG_ VfssMdl3Dttr7DttrDtSlt : 148|4@1+ (1,0) [0|15] "" Vector__XXX
 SG_ VfssMdl3Dttr8DttrDtSlt : 172|4@1+ (1,0) [0|15] "" Vector__XXX

BO_ 2633719550 VFSSM4DET: 24 Vector__XXX
 SG_ VfssMdl4Dttr1DttrTp : 0|4@1+ (1,0) [0|15] "" Vector__XXX
 SG_ VfssMdl4Dttr2DttrTp : 24|4@1+ (1,0) [0|15] "" Vector__XXX
 SG_ VfssMdl4Dttr3DttrTp : 48|4@1+ (1,0) [0|15] "" Vector__XXX
 SG_ VfssMdl4Dttr4DttrTp : 72|4@1+ (1,0) [0|15] "" Vector__XXX
 SG_ VfssMdl4Dttr5DttrTp : 96|4@1+ (1,0) [0|15] "" Vector__XXX
 SG_ VfssMdl4Dttr6DttrTp : 120|4@1+ (1,0) [0|15] "" Vector__XXX
 SG_ VfssMdl4Dttr7DttrTp : 144|4@1+ (1,0) [0|15] "" Vector__XXX
 SG_ VfssMdl4Dttr8DttrTp : 168|4@1+ (1,0) [0|15] "" Vector__XXX
 SG_ VfssMdl4Dttr1DttrDtSlt : 4|4@1+ (1,0) [0|15] "" Vector__XXX
 SG_ VfssMdl4Dttr2DttrDtSlt : 28|4@1+ (1,0) [0|15] "" Vector__XXX
 SG_ VfssMdl4Dttr3DttrDtSlt : 52|4@1+ (1,0) [0|15] "" Vector__XXX
 SG_ VfssMdl4Dttr4DttrDtSlt : 76|4@1+ (1,0) [0|15] "" Vector__XXX
 SG_ VfssMdl4Dttr5DttrDtSlt : 100|4@1+ (1,0) [0|15] "" Vector__XXX
 SG_ VfssMdl4Dttr6DttrDtSlt : 124|4@1+ (1,0) [0|15] "" Vector__XXX
 SG_ VfssMdl4Dttr7DttrDtSlt : 148|4@1+ (1,0) [0|15] "" Vector__XXX
 SG_ VfssMdl4Dttr8DttrDtSlt : 172|4@1+ (1,0) [0|15] "" Vector__XXX

BO_ 2633719806 VFSSM1AUX: 16 Vector__XXX
 SG_ VfssModule1HeatZone1Data : 0|16@1+ (0.01,0) [0|642.55] "V" Vector__XXX
 SG_ VfssModule1HeatZone2Data : 16|16@1+ (0.01,0) [0|642.55] "V" Vector__XXX
 SG_ VfssModule1ReleaseZone1Data : 32|16@1+ (0.01,0) [0|642.55] "V" Vector__XXX
 SG_ VfssModule1ReleaseZone2Data : 48|16@1+ (0.01,0) [0|642.55] "V" Vector__XXX
 SG_ VfssModule1PressureSwitch1Data : 64|16@1+ (0.01,0) [0|642.55] "V" Vector__XXX
 SG_ VfssModule1PressureSwitch2Data : 80|16@1+ (0.01,0) [0|642.55] "V" Vector__XXX
 SG_ VfssModule1PrimaryPowerVoltage : 96|16@1+ (0.01,0) [0|642.55] "V" Vector__XXX
 SG_ VfssMdl1SndrPwrVltg : 112|16@1+ (0.01,0) [0|642.55] "V" Vector__XXX

BO_ 2633720062 VFSSM2AUX: 16 Vector__XXX
 SG_ VfssModule2HeatZone1Data : 0|16@1+ (0.01,0) [0|642.55] "V" Vector__XXX
 SG_ VfssModule2HeatZone2Data : 16|16@1+ (0.01,0) [0|642.55] "V" Vector__XXX
 SG_ VfssModule2ReleaseZone1Data : 32|16@1+ (0.01,0) [0|642.55] "V" Vector__XXX
 SG_ VfssModule2ReleaseZone2Data : 48|16@1+ (0.01,0) [0|642.55] "V" Vector__XXX
 SG_ VfssModule2PressureSwitch1Data : 64|16@1+ (0.01,0) [0|642.55] "V" Vector__XXX
 SG_ VfssModule2PressureSwitch2Data : 80|16@1+ (0.01,0) [0|642.55] "V" Vector__XXX
 SG_ VfssModule2PrimaryPowerVoltage : 96|16@1+ (0.01,0) [0|642.55] "V" Vector__XXX
 SG_ VfssMdl2SndrPwrVltg : 112|16@1+ (0.01,0) [0|642.55] "V" Vector__XXX

BO_ 2633720318 VFSSM3AUX: 16 Vector__XXX
 SG_ VfssModule3HeatZone1Data : 0|16@1+ (0.01,0) [0|642.55] "V" Vector__XXX
 SG_ VfssModule3HeatZone2Data : 16|16@1+ (0.01,0) [0|642.55] "V" Vector__XXX
 SG_ VfssModule3ReleaseZone1Data : 32|16@1+ (0.01,0) [0|642.55] "V" Vector__XXX
 SG_ VfssModule3ReleaseZone2Data : 48|16@1+ (0.01,0) [0|642.55] "V" Vector__XXX
 SG_ VfssModule3PressureSwitch1Data : 64|16@1+ (0.01,0) [0|642.55] "V" Vector__XXX
 SG_ VfssModule3PressureSwitch2Data : 80|16@1+ (0.01,0) [0|642.55] "V" Vector__XXX
 SG_ VfssModule3PrimaryPowerVoltage : 96|16@1+ (0.01,0) [0|642.55] "V" Vector__XXX
 SG_ VfssMdl3SndrPwrVltg : 112|16@1+ (0.01,0) [0|642.55] "V" Vector__XXX

BO_ 2633720574 VFSSM4AUX: 16 Vector__XXX
 SG_ VfssModule4HeatZone1Data : 0|16@1+ (0.01,0) [0|642.55] "V" Vector__XXX
 SG_ VfssModule4HeatZone2Data : 16|16@1+ (0.01,0) [0|642.55] "V" Vector__XXX
 SG_ VfssModule4ReleaseZone1Data : 32|16@1+ (0.01,0) [0|642.55] "V" Vector__XXX
 SG_ VfssModule4ReleaseZone2Data : 48|16@1+ (0.01,0) [0|642.55] "V" Vector__XXX
 SG_ VfssModule4PressureSwitch1Data : 64|16@1+ (0.01,0) [0|642.55] "V" Vector__XXX
 SG_ VfssModule4PressureSwitch2Data : 80|16@1+ (0.01,0) [0|642.55] "V" Vector__XXX
 SG_ VfssModule4PrimaryPowerVoltage : 96|16@1+ (0.01,0) [0|642.55] "V" Vector__XXX
 SG_ VfssMdl4SndrPwrVltg : 112|16@1+ (0.01,0) [0|642.55] "V" Vector__XXX

BO_ 2633720830 VFSSM1NAMES: 104 Vector__XXX
 SG_ VfssModule1Name : 0|64@1+ (1,0) [0|255] "" Vector__XXX
 SG_ VfssModule1DetectorZone1Name : 64|64@1+ (1,0) [0|255] "" Vector__XXX
 SG_ VfssModule1DetectorZone2Name : 128|64@1+ (1,0) [0|255] "" Vector__XXX
 SG_ VfssModule1DetectorZone3Name : 192|64@1+ (1,0) [0|255] "" Vector__XXX
 SG_ VfssModule1DetectorZone4Name : 256|64@1+ (1,0) [0|255] "" Vector__XXX
 SG_ VfssModule1DetectorZone5Name : 320|64@1+ (1,0) [0|255] "" Vector__XXX
 SG_ VfssModule1DetectorZone6Name : 384|64@1+ (1,0) [0|255] "" Vector__XXX
 SG_ VfssModule1DetectorZone7Name : 448|64@1+ (1,0) [0|255] "" Vector__XXX
 SG_ VfssModule1DetectorZone8Name : 512|64@1+ (1,0) [0|255] "" Vector__XXX
 SG_ VfssModule1HeatZone1Name : 576|64@1+ (1,0) [0|255] "" Vector__XXX
 SG_ VfssModule1HeatZone2Name : 640|64@1+ (1,0) [0|255] "" Vector__XXX
 SG_ VfssModule1ReleaseZone1Name : 704|64@1+ (1,0) [0|255] "" Vector__XXX
 SG_ VfssModule1ReleaseZone2Name : 768|64@1+ (1,0) [0|255] "" Vector__XXX

BO_ 2633721086 VFSSM2NAMES: 104 Vector__XXX
 SG_ VfssModule2Name : 0|64@1+ (1,0) [0|255] "" Vector__XXX
 SG_ VfssModule2DetectorZone1Name : 64|64@1+ (1,0) [0|255] "" Vector__XXX
 SG_ VfssModule2DetectorZone2Name : 128|64@1+ (1,0) [0|255] "" Vector__XXX
 SG_ VfssModule2DetectorZone3Name : 192|64@1+ (1,0) [0|255] "" Vector__XXX
 SG_ VfssModule2DetectorZone4Name : 256|64@1+ (1,0) [0|255] "" Vector__XXX
 SG_ VfssModule2DetectorZone5Name : 320|64@1+ (1,0) [0|255] "" Vector__XXX
 SG_ VfssModule2DetectorZone6Name : 384|64@1+ (1,0) [0|255] "" Vector__XXX
 SG_ VfssModule2DetectorZone7Name : 448|64@1+ (1,0) [0|255] "" Vector__XXX
 SG_ VfssModule2DetectorZone8Name : 512|64@1+ (1,0) [0|255] "" Vector__XXX
 SG_ VfssModule2HeatZone1Name : 576|64@1+ (1,0) [0|255] "" Vector__XXX
 SG_ VfssModule2HeatZone2Name : 640|64@1+ (1,0) [0|255] "" Vector__XXX
 SG_ VfssModule2ReleaseZone1Name : 704|64@1+ (1,0) [0|255] "" Vector__XXX
 SG_ VfssModule2ReleaseZone2Name : 768|64@1+ (1,0) [0|255] "" Vector__XXX

BO_ 2633721342 VFSSM3NAMES: 104 Vector__XXX
 SG_ VfssModule3Name : 0|64@1+ (1,0) [0|255] "" Vector__XXX
 SG_ VfssModule3DetectorZone1Name : 64|64@1+ (1,0) [0|255] "" Vector__XXX
 SG_ VfssModule3DetectorZone2Name : 128|64@1+ (1,0) [0|255] "" Vector__XXX
 SG_ VfssModule3DetectorZone3Name : 192|64@1+ (1,0) [0|255] "" Vector__XXX
 SG_ VfssModule3DetectorZone4Name : 256|64@1+ (1,0) [0|255] "" Vector__XXX
 SG_ VfssModule3DetectorZone5Name : 320|64@1+ (1,0) [0|255] "" Vector__XXX
 SG_ VfssModule3DetectorZone6Name : 384|64@1+ (1,0) [0|255] "" Vector__XXX
 SG_ VfssModule3DetectorZone7Name : 448|64@1+ (1,0) [0|255] "" Vector__XXX
 SG_ VfssModule3DetectorZone8Name : 512|64@1+ (1,0) [0|255] "" Vector__XXX
 SG_ VfssModule3HeatZone1Name : 576|64@1+ (1,0) [0|255] "" Vector__XXX
 SG_ VfssModule3HeatZone2Name : 640|64@1+ (1,0) [0|255] "" Vector__XXX
 SG_ VfssModule3ReleaseZone1Name : 704|64@1+ (1,0) [0|255] "" Vector__XXX
 SG_ VfssModule3ReleaseZone2Name : 768|64@1+ (1,0) [0|255] "" Vector__XXX

BO_ 2633721598 VFSSM4NAMES: 104 Vector__XXX
 SG_ VfssModule4Name : 0|64@1+ (1,0) [0|255] "" Vector__XXX
 SG_ VfssModule4DetectorZone1Name : 64|64@1+ (1,0) [0|255] "" Vector__XXX
 SG_ VfssModule4DetectorZone2Name : 128|64@1+ (1,0) [0|255] "" Vector__XXX
 SG_ VfssModule4DetectorZone3Name : 192|64@1+ (1,0) [0|255] "" Vector__XXX
 SG_ VfssModule4DetectorZone4Name : 256|64@1+ (1,0) [0|255] "" Vector__XXX
 SG_ VfssModule4DetectorZone5Name : 320|64@1+ (1,0) [0|255] "" Vector__XXX
 SG_ VfssModule4DetectorZone6Name : 384|64@1+ (1,0) [0|255] "" Vector__XXX
 SG_ VfssModule4DetectorZone7Name : 448|64@1+ (1,0) [0|255] "" Vector__XXX
 SG_ VfssModule4DetectorZone8Name : 512|64@1+ (1,0) [0|255] "" Vector__XXX
 SG_ VfssModule4HeatZone1Name : 576|64@1+ (1,0) [0|255] "" Vector__XXX
 SG_ VfssModule4HeatZone2Name : 640|64@1+ (1,0) [0|255] "" Vector__XXX
 SG_ VfssModule4ReleaseZone1Name : 704|64@1+ (1,0) [0|255] "" Vector__XXX
 SG_ VfssModule4ReleaseZone2Name : 768|64@1+ (1,0) [0|255] "" Vector__XXX

BO_ 2566612990 MG2IAPL: 8 Vector__XXX
 SG_ MtGt2IvtPwLtdDTUddRs : 0|2@1+ (1,0) [0|3] "" Vector__XXX
 SG_ MtGt2IvtPwLtdDTMPwMx : 10|2@1+ (1,0) [0|3] "" Vector__XXX
 SG_ MtGt2IvtPwLtdDTMPwM : 12|2@1+ (1,0) [0|3] "" Vector__XXX
 SG_ MtrGnrtr2InvrtrPwrLmtdDTTrqMxmm : 18|2@1+ (1,0) [0|3] "" Vector__XXX
 SG_ MtrGnrtr2InvrtrPwrLmtdDTTrqMnmm : 20|2@1+ (1,0) [0|3] "" Vector__XXX
 SG_ MtrGnrtr2InvrtrPwrLmtdDTSpdMxmm : 22|2@1+ (1,0) [0|3] "" Vector__XXX
 SG_ MtrGnrtr2InvrtrPwrLmtdDTSpdMnmm : 24|2@1+ (1,0) [0|3] "" Vector__XXX
 SG_ MtGt2IvtPwLtdDTIvtTpt : 28|2@1+ (1,0) [0|3] "" Vector__XXX
 SG_ MtGt2IvtPwLtdDTMtTpt : 30|2@1+ (1,0) [0|3] "" Vector__XXX
 SG_ MtGt2IvtPwLtdDTFtCdt : 32|2@1+ (1,0) [0|3] "" Vector__XXX
 SG_ MtGt2IvtPwLtdDTAtvTqRtLt : 34|2@1+ (1,0) [0|3] "" Vector__XXX
 SG_ MtGt2IvtPwLtdDTAtvSpdRtLt : 36|2@1+ (1,0) [0|3] "" Vector__XXX
 SG_ MtGt2IvtTqLtdDTMCtsts : 38|2@1+ (1,0) [0|3] "" Vector__XXX
 SG_ MtGt2IvtPwLtdDTDSdCtMx : 2|2@1+ (1,0) [0|3] "" Vector__XXX
 SG_ MtGt2IvtPwLtdDTDSdCtM : 4|2@1+ (1,0) [0|3] "" Vector__XXX
 SG_ MtGt2IvtPwLtdDTDSdVtMx : 6|2@1+ (1,0) [0|3] "" Vector__XXX
 SG_ MtGt2IvtPwLtdDTDSdVtM : 8|2@1+ (1,0) [0|3] "" Vector__XXX
 SG_ MtGt2IvtPwLtdDTDSdPwMx : 14|2@1+ (1,0) [0|3] "" Vector__XXX
 SG_ MtGt2IvtPwLtdDTDSdPwM : 16|2@1+ (1,0) [0|3] "" Vector__XXX

BO_ 2566613246 MG2II: 8 Vector__XXX
 SG_ MtrGnrtr2InvrtrIsltnIntgrtCntr : 8|4@1+ (1,0) [0|15] "" Vector__XXX
 SG_ MtGt2IvtHVtBsAtvIstTstStts : 24|4@1+ (1,0) [0|15] "" Vector__XXX
 SG_ MtGt2IvtHVtBsPssvIstTstStts : 28|4@1+ (1,0) [0|15] "" Vector__XXX
 SG_ MtGt2IvtHVtBsAtvIstTstRsts : 32|16@1+ (0.1,0) [0|6425.5] "OhmPerV" Vector__XXX
 SG_ MtGt2IvtHVtBsPssvIstTstRsts : 48|16@1+ (0.1,0) [0|6425.5] "OhmPerV" Vector__XXX
 SG_ MtrGnrtr2InvrtrIsltnIntgrtCr : 0|8@1+ (1,0) [0|250] "count" Vector__XXX
 SG_ MtGt2IvtDSdNtvTCsssGdVt : 12|12@1+ (0.0625,-125) [-125|125.9375] "%" Vector__XXX

BO_ 2566613502 MG1IAPL: 8 Vector__XXX
 SG_ MtGt1IvtPwLtdDTUddRs : 0|2@1+ (1,0) [0|3] "" Vector__XXX
 SG_ MtGt1IvtPwLtdDTMPwMx : 10|2@1+ (1,0) [0|3] "" Vector__XXX
 SG_ MtGt1IvtPwLtdDTMPwM : 12|2@1+ (1,0) [0|3] "" Vector__XXX
 SG_ MtrGnrtr1InvrtrPwrLmtdDTTrqMxmm : 18|2@1+ (1,0) [0|3] "" Vector__XXX
 SG_ MtrGnrtr1InvrtrPwrLmtdDTTrqMnmm : 20|2@1+ (1,0) [0|3] "" Vector__XXX
 SG_ MtrGnrtr1InvrtrPwrLmtdDTSpdMxmm : 22|2@1+ (1,0) [0|3] "" Vector__XXX
 SG_ MtrGnrtr1InvrtrPwrLmtdDTSpdMnmm : 24|2@1+ (1,0) [0|3] "" Vector__XXX
 SG_ MtGt1IvtPwLtdDTIvtTpt : 28|2@1+ (1,0) [0|3] "" Vector__XXX
 SG_ MtGt1IvtPwLtdDTMtTpt : 30|2@1+ (1,0) [0|3] "" Vector__XXX
 SG_ MtGt1IvtPwLtdDTFtCdt : 32|2@1+ (1,0) [0|3] "" Vector__XXX
 SG_ MtGt1IvtPwLtdDTAtvTqRtLt : 34|2@1+ (1,0) [0|3] "" Vector__XXX
 SG_ MtGt1IvtPwLtdDTAtvSpdRtLt : 36|2@1+ (1,0) [0|3] "" Vector__XXX
 SG_ MtGt1IvtTqLtdDTMCtsts : 38|2@1+ (1,0) [0|3] "" Vector__XXX
 SG_ MtGt1IvtPwLtdDTDSdCtMx : 2|2@1+ (1,0) [0|3] "" Vector__XXX
 SG_ MtGt1IvtPwLtdDTDSdCtM : 4|2@1+ (1,0) [0|3] "" Vector__XXX
 SG_ MtGt1IvtPwLtdDTDSdVtMx : 6|2@1+ (1,0) [0|3] "" Vector__XXX
 SG_ MtGt1IvtPwLtdDTDSdVtM : 8|2@1+ (1,0) [0|3] "" Vector__XXX
 SG_ MtGt1IvtPwLtdDTDSdPwMx : 14|2@1+ (1,0) [0|3] "" Vector__XXX
 SG_ MtGt1IvtPwLtdDTDSdPwM : 16|2@1+ (1,0) [0|3] "" Vector__XXX

BO_ 2566613758 MG1II: 8 Vector__XXX
 SG_ MtrGnrtr1InvrtrIsltnIntgrtCntr : 8|4@1+ (1,0) [0|15] "" Vector__XXX
 SG_ MtGt1IvtHVtBsAtvIstTstStts : 24|4@1+ (1,0) [0|15] "" Vector__XXX
 SG_ MtGt1IvtHVtBsPssvIstTstStts : 28|4@1+ (1,0) [0|15] "" Vector__XXX
 SG_ MtGt1IvtHVtBsAtvIstTstRsts : 32|16@1+ (0.1,0) [0|6425.5] "OhmPerV" Vector__XXX
 SG_ MtGt1IvtHVtBsPssvIstTstRsts : 48|16@1+ (0.1,0) [0|6425.5] "OhmPerV" Vector__XXX
 SG_ MtrGnrtr1InvrtrIsltnIntgrtCr : 0|8@1+ (1,0) [0|250] "count" Vector__XXX
 SG_ MtGt1IvtDSdNtvTCsssGdVt : 12|12@1+ (0.0625,-125) [-125|125.9375] "%" Vector__XXX

BO_ 2566614014 HVBI: 8 Vector__XXX
 SG_ HighVoltageDcBusAvailability : 0|4@1+ (1,0) [0|15] "" Vector__XXX
 SG_ HghVltgBsDrvlnAvllt : 4|4@1+ (1,0) [0|15] "" Vector__XXX
 SG_ HghVltgBsAxlrsAvllt : 8|4@1+ (1,0) [0|15] "" Vector__XXX
 SG_ HighVoltageBusEptoAvailability : 12|4@1+ (1,0) [0|15] "" Vector__XXX
 SG_ HghVltgBsOnBrdChrgrAvllt : 16|4@1+ (1,0) [0|15] "" Vector__XXX
 SG_ HghVltgBsOffBrdChrgrAvllt : 20|4@1+ (1,0) [0|15] "" Vector__XXX

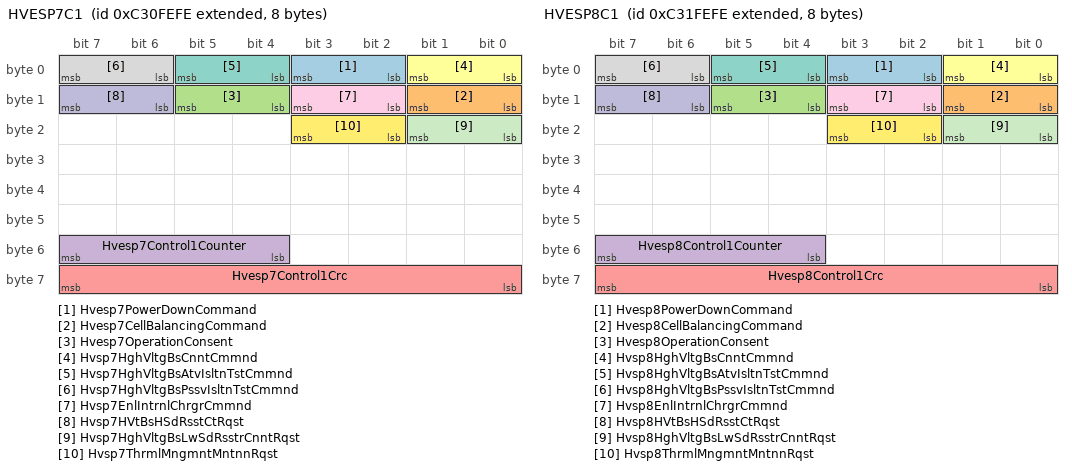
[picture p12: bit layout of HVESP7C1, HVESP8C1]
BO_ 2352021246 HVESP7C1: 8 Vector__XXX
 SG_ Hvesp7PowerDownCommand : 2|2@1+ (1,0) [0|3] "" Vector__XXX
 SG_ Hvesp7CellBalancingCommand : 8|2@1+ (1,0) [0|3] "" Vector__XXX
 SG_ Hvesp7OperationConsent : 12|2@1+ (1,0) [0|3] "" Vector__XXX
 SG_ Hvesp7Control1Counter : 52|4@1+ (1,0) [0|15] "" Vector__XXX
 SG_ Hvesp7Control1Crc : 56|8@1+ (1,0) [0|250] "count" Vector__XXX
 SG_ Hvsp7HghVltgBsCnntCmmnd : 0|2@1+ (1,0) [0|3] "" Vector__XXX
 SG_ Hvsp7HghVltgBsAtvIsltnTstCmmnd : 4|2@1+ (1,0) [0|3] "" Vector__XXX
 SG_ Hvsp7HghVltgBsPssvIsltnTstCmmnd : 6|2@1+ (1,0) [0|3] "" Vector__XXX
 SG_ Hvsp7EnlIntrnlChrgrCmmnd : 10|2@1+ (1,0) [0|3] "" Vector__XXX
 SG_ Hvsp7HVtBsHSdRsstCtRqst : 14|2@1+ (1,0) [0|3] "" Vector__XXX
 SG_ Hvsp7HghVltgBsLwSdRsstrCnntRqst : 16|2@1+ (1,0) [0|3] "" Vector__XXX
 SG_ Hvsp7ThrmlMngmntMntnnRqst : 18|2@1+ (1,0) [0|3] "" Vector__XXX

BO_ 2352086782 HVESP8C1: 8 Vector__XXX
 SG_ Hvesp8PowerDownCommand : 2|2@1+ (1,0) [0|3] "" Vector__XXX
 SG_ Hvesp8CellBalancingCommand : 8|2@1+ (1,0) [0|3] "" Vector__XXX
 SG_ Hvesp8OperationConsent : 12|2@1+ (1,0) [0|3] "" Vector__XXX
 SG_ Hvesp8Control1Counter : 52|4@1+ (1,0) [0|15] "" Vector__XXX
 SG_ Hvesp8Control1Crc : 56|8@1+ (1,0) [0|250] "count" Vector__XXX
 SG_ Hvsp8HghVltgBsCnntCmmnd : 0|2@1+ (1,0) [0|3] "" Vector__XXX
 SG_ Hvsp8HghVltgBsAtvIsltnTstCmmnd : 4|2@1+ (1,0) [0|3] "" Vector__XXX
 SG_ Hvsp8HghVltgBsPssvIsltnTstCmmnd : 6|2@1+ (1,0) [0|3] "" Vector__XXX
 SG_ Hvsp8EnlIntrnlChrgrCmmnd : 10|2@1+ (1,0) [0|3] "" Vector__XXX
 SG_ Hvsp8HVtBsHSdRsstCtRqst : 14|2@1+ (1,0) [0|3] "" Vector__XXX
 SG_ Hvsp8HghVltgBsLwSdRsstrCnntRqst : 16|2@1+ (1,0) [0|3] "" Vector__XXX
 SG_ Hvsp8ThrmlMngmntMntnnRqst : 18|2@1+ (1,0) [0|3] "" Vector__XXX

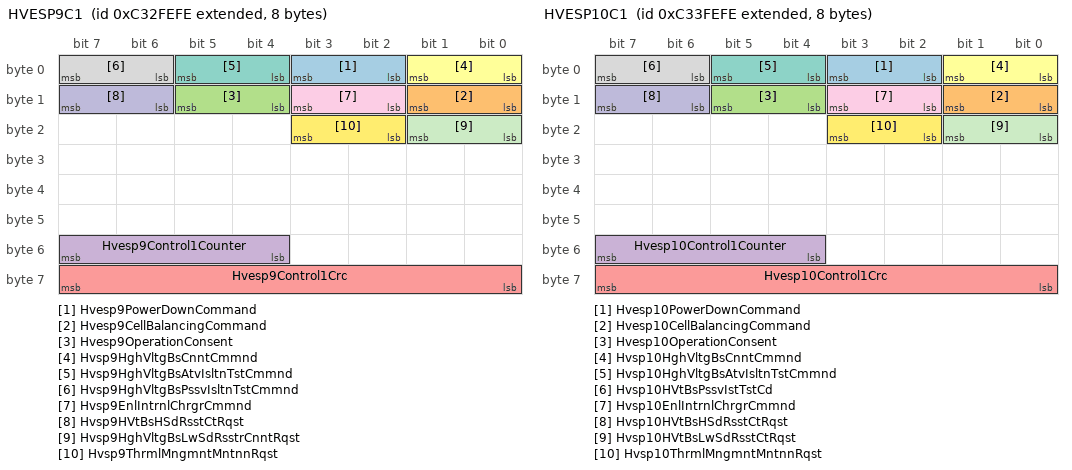
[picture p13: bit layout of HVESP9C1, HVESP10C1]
BO_ 2352152318 HVESP9C1: 8 Vector__XXX
 SG_ Hvesp9PowerDownCommand : 2|2@1+ (1,0) [0|3] "" Vector__XXX
 SG_ Hvesp9CellBalancingCommand : 8|2@1+ (1,0) [0|3] "" Vector__XXX
 SG_ Hvesp9OperationConsent : 12|2@1+ (1,0) [0|3] "" Vector__XXX
 SG_ Hvesp9Control1Counter : 52|4@1+ (1,0) [0|15] "" Vector__XXX
 SG_ Hvesp9Control1Crc : 56|8@1+ (1,0) [0|250] "count" Vector__XXX
 SG_ Hvsp9HghVltgBsCnntCmmnd : 0|2@1+ (1,0) [0|3] "" Vector__XXX
 SG_ Hvsp9HghVltgBsAtvIsltnTstCmmnd : 4|2@1+ (1,0) [0|3] "" Vector__XXX
 SG_ Hvsp9HghVltgBsPssvIsltnTstCmmnd : 6|2@1+ (1,0) [0|3] "" Vector__XXX
 SG_ Hvsp9EnlIntrnlChrgrCmmnd : 10|2@1+ (1,0) [0|3] "" Vector__XXX
 SG_ Hvsp9HVtBsHSdRsstCtRqst : 14|2@1+ (1,0) [0|3] "" Vector__XXX
 SG_ Hvsp9HghVltgBsLwSdRsstrCnntRqst : 16|2@1+ (1,0) [0|3] "" Vector__XXX
 SG_ Hvsp9ThrmlMngmntMntnnRqst : 18|2@1+ (1,0) [0|3] "" Vector__XXX

BO_ 2352217854 HVESP10C1: 8 Vector__XXX
 SG_ Hvesp10PowerDownCommand : 2|2@1+ (1,0) [0|3] "" Vector__XXX
 SG_ Hvesp10CellBalancingCommand : 8|2@1+ (1,0) [0|3] "" Vector__XXX
 SG_ Hvesp10OperationConsent : 12|2@1+ (1,0) [0|3] "" Vector__XXX
 SG_ Hvesp10Control1Counter : 52|4@1+ (1,0) [0|15] "" Vector__XXX
 SG_ Hvesp10Control1Crc : 56|8@1+ (1,0) [0|250] "count" Vector__XXX
 SG_ Hvsp10HghVltgBsCnntCmmnd : 0|2@1+ (1,0) [0|3] "" Vector__XXX
 SG_ Hvsp10HghVltgBsAtvIsltnTstCmmnd : 4|2@1+ (1,0) [0|3] "" Vector__XXX
 SG_ Hvsp10HVtBsPssvIstTstCd : 6|2@1+ (1,0) [0|3] "" Vector__XXX
 SG_ Hvsp10EnlIntrnlChrgrCmmnd : 10|2@1+ (1,0) [0|3] "" Vector__XXX
 SG_ Hvsp10HVtBsHSdRsstCtRqst : 14|2@1+ (1,0) [0|3] "" Vector__XXX
 SG_ Hvsp10HVtBsLwSdRsstCtRqst : 16|2@1+ (1,0) [0|3] "" Vector__XXX
 SG_ Hvsp10ThrmlMngmntMntnnRqst : 18|2@1+ (1,0) [0|3] "" Vector__XXX

BO_ 2555379454 DTS: 29 Vector__XXX
 SG_ DataTransferManufacturerId : 0|11@1+ (1,0) [0|2007] "" Vector__XXX
 SG_ TotalWeeklyMessageInstances : 88|16@1+ (1,0) [0|64255] "count" Vector__XXX
 SG_ LongestWeeklyMessageInstance : 104|24@1+ (1,0) [0|16449535] "count" Vector__XXX
 SG_ TotalMonthlyMessageInstances : 160|16@1+ (1,0) [0|64255] "count" Vector__XXX
 SG_ LongestMonthlyMessageInstance : 176|24@1+ (1,0) [0|16449535] "count" Vector__XXX
 SG_ TotalDailyMessageInstances : 16|16@1+ (1,0) [0|64255] "count" Vector__XXX
 SG_ LongestDailyMessageInstance : 32|24@1+ (1,0) [0|16449535] "count" Vector__XXX
 SG_ TotalDailyMessageBytes : 56|32@1+ (1,0) [0|4211081215] "count" Vector__XXX
 SG_ TotalWeeklyMessageBytes : 128|32@1+ (1,0) [0|4211081215] "count" Vector__XXX
 SG_ TotalMonthlyMessageBytes : 200|32@1+ (1,0) [0|4211081215] "count" Vector__XXX

BO_ 2555444990 MDT: 8 Vector__XXX
 SG_ MonthlyMessageInstance : 0|16@1+ (1,0) [0|64255] "count" Vector__XXX
 SG_ MnthlMssgInstnsRmnng : 16|16@1+ (1,0) [0|64255] "count" Vector__XXX
 SG_ MonthlyDataManufacturerId : 32|11@1+ (1,0) [0|2007] "" Vector__XXX

BO_ 2555510526 WDT: 8 Vector__XXX
 SG_ WeeklyMessageInstance : 0|16@1+ (1,0) [0|64255] "count" Vector__XXX
 SG_ WeeklyMessageInstancesRemaining : 16|16@1+ (1,0) [0|64255] "count" Vector__XXX
 SG_ WeeklyDataManufacturerId : 32|11@1+ (1,0) [0|2007] "" Vector__XXX

BO_ 2555576062 DDT: 8 Vector__XXX
 SG_ DailyMessageInstance : 0|16@1+ (1,0) [0|64255] "count" Vector__XXX
 SG_ DailyMessageInstancesRemaining : 16|16@1+ (1,0) [0|64255] "count" Vector__XXX
 SG_ DailyDataManufacturerId : 32|11@1+ (1,0) [0|2007] "" Vector__XXX

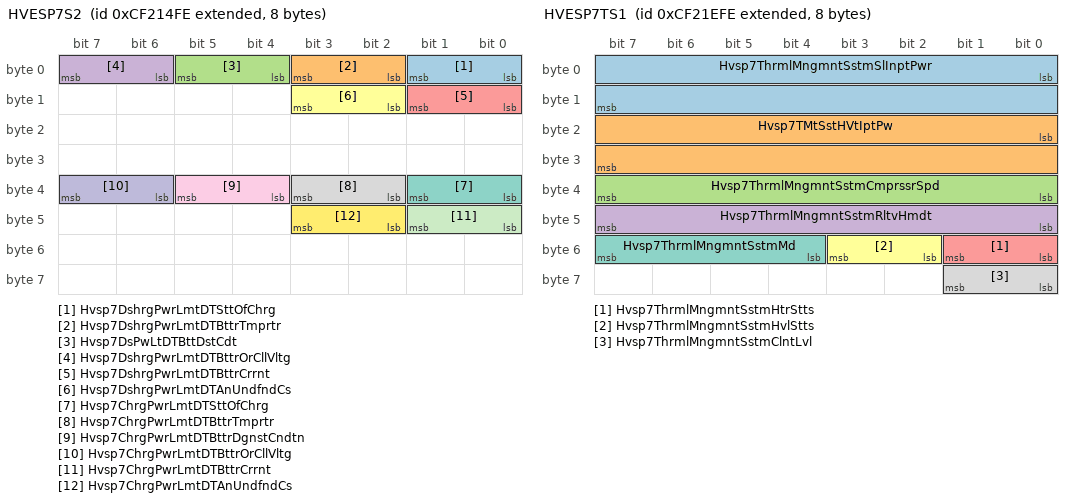
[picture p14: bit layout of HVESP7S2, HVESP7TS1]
BO_ 2364675326 HVESP7S2: 8 Vector__XXX
 SG_ Hvsp7DshrgPwrLmtDTSttOfChrg : 0|2@1+ (1,0) [0|3] "" Vector__XXX
 SG_ Hvsp7DshrgPwrLmtDTBttrTmprtr : 2|2@1+ (1,0) [0|3] "" Vector__XXX
 SG_ Hvsp7DsPwLtDTBttDstCdt : 4|2@1+ (1,0) [0|3] "" Vector__XXX
 SG_ Hvsp7DshrgPwrLmtDTBttrOrCllVltg : 6|2@1+ (1,0) [0|3] "" Vector__XXX
 SG_ Hvsp7DshrgPwrLmtDTBttrCrrnt : 8|2@1+ (1,0) [0|3] "" Vector__XXX
 SG_ Hvsp7DshrgPwrLmtDTAnUndfndCs : 10|2@1+ (1,0) [0|3] "" Vector__XXX
 SG_ Hvsp7ChrgPwrLmtDTSttOfChrg : 32|2@1+ (1,0) [0|3] "" Vector__XXX
 SG_ Hvsp7ChrgPwrLmtDTBttrTmprtr : 34|2@1+ (1,0) [0|3] "" Vector__XXX
 SG_ Hvsp7ChrgPwrLmtDTBttrDgnstCndtn : 36|2@1+ (1,0) [0|3] "" Vector__XXX
 SG_ Hvsp7ChrgPwrLmtDTBttrOrCllVltg : 38|2@1+ (1,0) [0|3] "" Vector__XXX
 SG_ Hvsp7ChrgPwrLmtDTBttrCrrnt : 40|2@1+ (1,0) [0|3] "" Vector__XXX
 SG_ Hvsp7ChrgPwrLmtDTAnUndfndCs : 42|2@1+ (1,0) [0|3] "" Vector__XXX

BO_ 2364675582 HVESP7D1: 8 Vector__XXX
 SG_ Hvesp7AvailableDischargePower : 0|16@1+ (0.05,0) [0|3212.75] "kW" Vector__XXX
 SG_ Hvesp7AvailableChargePower : 16|16@1+ (0.05,0) [0|3212.75] "kW" Vector__XXX
 SG_ Hvesp7VoltageLevel : 32|16@1+ (0.05,0) [0|3212.75] "V" Vector__XXX
 SG_ Hvesp7Current : 48|16@1+ (0.05,-1600) [-1600|1612.75] "A" Vector__XXX

BO_ 2364675838 HVESP7D2: 8 Vector__XXX
 SG_ Hvesp7FastUpdateStateOfCharge : 0|16@1+ (0.0015625,0) [0|100.3984375] "%" Vector__XXX
 SG_ Hvesp7HighestCellVoltage : 16|16@1+ (0.001,0) [0|64.255] "V" Vector__XXX
 SG_ Hvesp7LowestCellVoltage : 32|16@1+ (0.001,0) [0|64.255] "V" Vector__XXX
 SG_ Hvsp7CllVltgDffrntlStts : 48|4@1+ (1,0) [0|15] "" Vector__XXX

BO_ 2364676094 HVESP7D3: 8 Vector__XXX
 SG_ Hvesp7HighestCellTemperature : 0|16@1+ (0.03125,-273) [-273|1734.96875] "degC" Vector__XXX
 SG_ Hvesp7LowestCellTemperature : 16|16@1+ (0.03125,-273) [-273|1734.96875] "degC" Vector__XXX
 SG_ Hvesp7AverageCellTemperature : 32|16@1+ (0.03125,-273) [-273|1734.96875] "degC" Vector__XXX
 SG_ Hvsp7CllTmprtrDffrntlStts : 48|2@1+ (1,0) [0|3] "" Vector__XXX

BO_ 2364676350 HVESP7D4: 8 Vector__XXX
 SG_ Hvesp7DischargeCapacity : 0|16@1+ (0.01,0) [0|642.55] "Ah" Vector__XXX
 SG_ Hvesp7ChargeCapacity : 16|16@1+ (0.01,0) [0|642.55] "Ah" Vector__XXX
 SG_ Hvesp7CellBalancingCount : 32|16@1+ (1,0) [0|64255] "count" Vector__XXX

BO_ 2364676606 HVESP7D5: 8 Vector__XXX
 SG_ Hvesp7LowestCellStateOfCharge : 32|16@1+ (0.0015625,0) [0|100.3984375] "%" Vector__XXX
 SG_ Hvesp7HighestCellStateOfCharge : 48|16@1+ (0.0015625,0) [0|100.3984375] "%" Vector__XXX
 SG_ Hvsp7MxmmInstntnsDshrgCrrntLmt : 0|16@1+ (0.05,-1600) [-1600|0] "A" Vector__XXX
 SG_ Hvsp7MxmmInstntnsChrgCrrntLmt : 16|16@1+ (0.05,-1600) [0|1612.75] "A" Vector__XXX

BO_ 2364676862 HVESP7D6: 8 Vector__XXX
 SG_ Hvesp7BusVoltage : 0|16@1+ (0.05,0) [0|3212.75] "V" Vector__XXX
 SG_ Hvesp7IgnitionVoltage : 16|16@1+ (0.01,0) [0|642.55] "V" Vector__XXX
 SG_ Hvesp7IntakeCoolantTemperature : 32|8@1+ (1,-40) [-40|210] "degC" Vector__XXX
 SG_ Hvesp7OutletCoolantTemperature : 40|8@1+ (1,-40) [-40|210] "degC" Vector__XXX
 SG_ Hvesp7ElectronicsTemperature : 48|8@1+ (1,-40) [-40|210] "degC" Vector__XXX
 SG_ Hvesp7Temperature : 56|8@1+ (1,-40) [-40|210] "degC" Vector__XXX

BO_ 2364677118 HVESP7S1: 8 Vector__XXX
 SG_ Hvesp7HvilStatus : 20|2@1+ (1,0) [0|3] "" Vector__XXX
 SG_ Hvesp7InertiaSwitchStatus : 22|2@1+ (1,0) [0|3] "" Vector__XXX
 SG_ Hvesp7StateOfChargeStatus : 24|4@1+ (1,0) [0|15] "" Vector__XXX
 SG_ Hvesp7CellBalanceStatus : 28|2@1+ (1,0) [0|3] "" Vector__XXX
 SG_ Hvesp7CellBalancingActive : 30|2@1+ (1,0) [0|3] "" Vector__XXX
 SG_ Hvesp7InternalChargerStatus : 32|2@1+ (1,0) [0|3] "" Vector__XXX
 SG_ Hvesp7OperationalStatus : 44|4@1+ (1,0) [0|15] "" Vector__XXX
 SG_ Hvesp7Status1Counter : 52|4@1+ (1,0) [0|15] "" Vector__XXX
 SG_ Hvesp7Status1Crc : 56|8@1+ (1,0) [0|250] "count" Vector__XXX
 SG_ Hvsp7HghVltgBsPstvCnttrStt : 0|2@1+ (1,0) [0|3] "" Vector__XXX
 SG_ Hvsp7HghVltgBsNgtvCnttrStt : 2|2@1+ (1,0) [0|3] "" Vector__XXX
 SG_ Hvsp7HghVltgBsDsnntFrwrnng : 4|4@1+ (1,0) [0|15] "" Vector__XXX
 SG_ Hvsp7HghVltgBsPrChrgRlStt : 8|2@1+ (1,0) [0|3] "" Vector__XXX
 SG_ Hvsp7CntrOfPkCnttrStt : 10|2@1+ (1,0) [0|3] "" Vector__XXX
 SG_ Hvsp7HghVltgBsAtvIsltnTstStts : 12|4@1+ (1,0) [0|15] "" Vector__XXX
 SG_ Hvsp7HghVltgBsPssvIsltnTstStts : 16|4@1+ (1,0) [0|15] "" Vector__XXX
 SG_ Hvsp7HghVltgBsCnntnStts : 40|4@1+ (1,0) [0|15] "" Vector__XXX

BO_ 2364677374 HVESP7D7: 8 Vector__XXX
 SG_ Hvesp7DischargeEnergyCapacity : 0|24@1+ (0.001,0) [0|16449.535] "kWh" Vector__XXX
 SG_ Hvesp7ChargeEnergyCapacity : 24|24@1+ (0.001,0) [0|16449.535] "kWh" Vector__XXX
 SG_ Hvesp7MaximumChargeVoltageLimit : 48|16@1+ (0.05,0) [0|3212.75] "V" Vector__XXX

BO_ 2364677630 HVESP7MS1: 8 Vector__XXX
 SG_ Hvesp7Module1OperationalStatus : 0|2@1+ (1,0) [0|3] "" Vector__XXX
 SG_ Hvesp7Module2OperationalStatus : 2|2@1+ (1,0) [0|3] "" Vector__XXX
 SG_ Hvesp7Module3OperationalStatus : 4|2@1+ (1,0) [0|3] "" Vector__XXX
 SG_ Hvesp7Module4OperationalStatus : 6|2@1+ (1,0) [0|3] "" Vector__XXX
 SG_ Hvesp7Module5OperationalStatus : 8|2@1+ (1,0) [0|3] "" Vector__XXX
 SG_ Hvesp7Module6OperationalStatus : 10|2@1+ (1,0) [0|3] "" Vector__XXX
 SG_ Hvesp7Module7OperationalStatus : 12|2@1+ (1,0) [0|3] "" Vector__XXX
 SG_ Hvesp7Module8OperationalStatus : 14|2@1+ (1,0) [0|3] "" Vector__XXX
 SG_ Hvesp7Module9OperationalStatus : 16|2@1+ (1,0) [0|3] "" Vector__XXX
 SG_ Hvesp7Module10OperationalStatus : 18|2@1+ (1,0) [0|3] "" Vector__XXX
 SG_ Hvesp7Module11OperationalStatus : 20|2@1+ (1,0) [0|3] "" Vector__XXX
 SG_ Hvesp7Module12OperationalStatus : 22|2@1+ (1,0) [0|3] "" Vector__XXX
 SG_ Hvesp7Module13OperationalStatus : 24|2@1+ (1,0) [0|3] "" Vector__XXX
 SG_ Hvesp7Module14OperationalStatus : 26|2@1+ (1,0) [0|3] "" Vector__XXX
 SG_ Hvesp7Module15OperationalStatus : 28|2@1+ (1,0) [0|3] "" Vector__XXX
 SG_ Hvesp7Module16OperationalStatus : 30|2@1+ (1,0) [0|3] "" Vector__XXX
 SG_ Hvesp7Module17OperationalStatus : 32|2@1+ (1,0) [0|3] "" Vector__XXX
 SG_ Hvesp7Module18OperationalStatus : 34|2@1+ (1,0) [0|3] "" Vector__XXX
 SG_ Hvesp7Module19OperationalStatus : 36|2@1+ (1,0) [0|3] "" Vector__XXX
 SG_ Hvesp7Module20OperationalStatus : 38|2@1+ (1,0) [0|3] "" Vector__XXX
 SG_ Hvesp7Module21OperationalStatus : 40|2@1+ (1,0) [0|3] "" Vector__XXX
 SG_ Hvesp7Module22OperationalStatus : 42|2@1+ (1,0) [0|3] "" Vector__XXX
 SG_ Hvesp7Module23OperationalStatus : 44|2@1+ (1,0) [0|3] "" Vector__XXX
 SG_ Hvesp7Module24OperationalStatus : 46|2@1+ (1,0) [0|3] "" Vector__XXX
 SG_ Hvesp7Module25OperationalStatus : 48|2@1+ (1,0) [0|3] "" Vector__XXX
 SG_ Hvesp7Module26OperationalStatus : 50|2@1+ (1,0) [0|3] "" Vector__XXX
 SG_ Hvesp7Module27OperationalStatus : 52|2@1+ (1,0) [0|3] "" Vector__XXX
 SG_ Hvesp7Module28OperationalStatus : 54|2@1+ (1,0) [0|3] "" Vector__XXX
 SG_ Hvesp7Module29OperationalStatus : 56|2@1+ (1,0) [0|3] "" Vector__XXX
 SG_ Hvesp7Module30OperationalStatus : 58|2@1+ (1,0) [0|3] "" Vector__XXX
 SG_ Hvesp7Module31OperationalStatus : 60|2@1+ (1,0) [0|3] "" Vector__XXX
 SG_ Hvesp7Module32OperationalStatus : 62|2@1+ (1,0) [0|3] "" Vector__XXX

BO_ 2364677886 HVESP7TS1: 8 Vector__XXX
 SG_ Hvsp7ThrmlMngmntSstmSlInptPwr : 0|16@1+ (0.5,0) [0|32127.5] "W" Vector__XXX
 SG_ Hvsp7TMtSstHVtIptPw : 16|16@1+ (0.5,0) [0|32127.5] "W" Vector__XXX
 SG_ Hvsp7ThrmlMngmntSstmCmprssrSpd : 32|8@1+ (32,0) [0|8000] "rpm" Vector__XXX
 SG_ Hvsp7ThrmlMngmntSstmRltvHmdt : 40|8@1+ (0.4,0) [0|100] "%" Vector__XXX
 SG_ Hvsp7ThrmlMngmntSstmHtrStts : 48|2@1+ (1,0) [0|3] "" Vector__XXX
 SG_ Hvsp7ThrmlMngmntSstmHvlStts : 50|2@1+ (1,0) [0|3] "" Vector__XXX
 SG_ Hvsp7ThrmlMngmntSstmMd : 52|4@1+ (1,0) [0|15] "" Vector__XXX
 SG_ Hvsp7ThrmlMngmntSstmClntLvl : 56|2@1+ (1,0) [0|3] "" Vector__XXX

BO_ 2364678142 HVESP7D8: 8 Vector__XXX
 SG_ Hvesp7AverageCellVoltage : 32|16@1+ (0.001,0) [0|64.255] "V" Vector__XXX
 SG_ Hvsp7HghstCllVltgMdlNmr : 0|8@1+ (1,0) [0|250] "count" Vector__XXX
 SG_ Hvsp7HghstCllVltgCllNmr : 8|8@1+ (1,0) [0|250] "count" Vector__XXX
 SG_ Hvsp7LwstCllVltgMdlNmr : 16|8@1+ (1,0) [0|250] "count" Vector__XXX
 SG_ Hvsp7LwstCllVltgCllNmr : 24|8@1+ (1,0) [0|250] "count" Vector__XXX

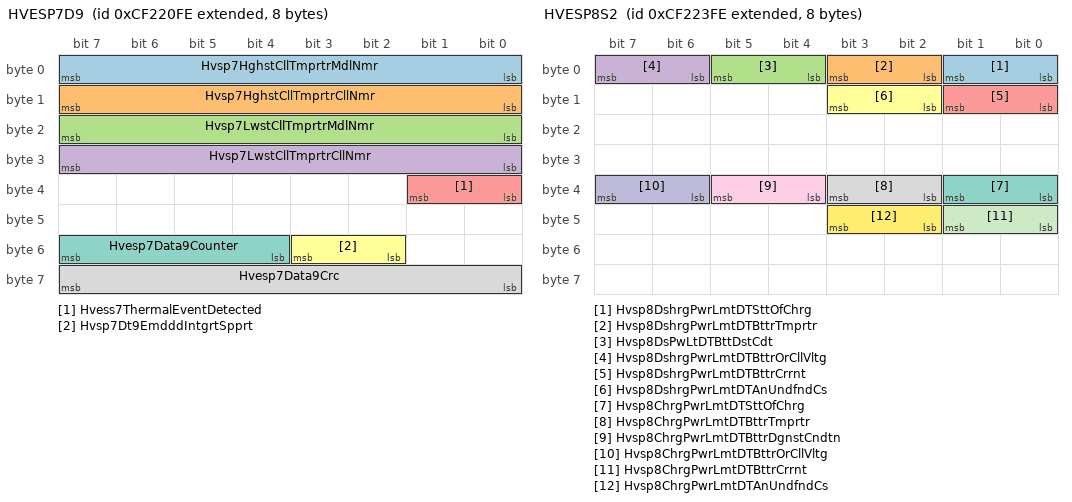
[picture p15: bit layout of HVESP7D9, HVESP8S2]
BO_ 2364678398 HVESP7D9: 8 Vector__XXX
 SG_ Hvsp7HghstCllTmprtrMdlNmr : 0|8@1+ (1,0) [0|250] "count" Vector__XXX
 SG_ Hvsp7HghstCllTmprtrCllNmr : 8|8@1+ (1,0) [0|250] "count" Vector__XXX
 SG_ Hvsp7LwstCllTmprtrMdlNmr : 16|8@1+ (1,0) [0|250] "count" Vector__XXX
 SG_ Hvsp7LwstCllTmprtrCllNmr : 24|8@1+ (1,0) [0|250] "count" Vector__XXX
 SG_ Hvess7ThermalEventDetected : 32|2@1+ (1,0) [0|3] "" Vector__XXX
 SG_ Hvsp7Dt9EmdddIntgrtSpprt : 50|2@1+ (1,0) [0|3] "" Vector__XXX
 SG_ Hvesp7Data9Counter : 52|4@1+ (1,0) [0|15] "" Vector__XXX
 SG_ Hvesp7Data9Crc : 56|8@1+ (1,0) [0|250] "count" Vector__XXX

BO_ 2364678654 HVESP7D10: 8 Vector__XXX
 SG_ Hvsp7HghstCllSttOfChrgMdlNmr : 0|8@1+ (1,0) [0|250] "count" Vector__XXX
 SG_ Hvsp7HghstCllSttOfChrgCllNmr : 8|8@1+ (1,0) [0|250] "count" Vector__XXX
 SG_ Hvsp7LwstCllSttOfChrgMdlNmr : 16|8@1+ (1,0) [0|250] "count" Vector__XXX
 SG_ Hvsp7LwstCllSttOfChrgCllNmr : 24|8@1+ (1,0) [0|250] "count" Vector__XXX
 SG_ Hvsp7HghVltgBsAtvIsltnTstRslts : 32|16@1+ (0.1,0) [0|6425.5] "OhmPerV" Vector__XXX
 SG_ Hvsp7HghVltgBsPssvIsltnTstRslts : 48|16@1+ (0.1,0) [0|6425.5] "OhmPerV" Vector__XXX

BO_ 2364678910 HVESP7D11: 8 Vector__XXX
 SG_ Hvesp7ActualChargeRate : 32|16@1+ (0.05,0) [0|3212.75] "kW" Vector__XXX
 SG_ Hvsp7BsVltgNgtvTChsssGrndVltg : 0|16@1+ (0.05,0) [0|3212.75] "V" Vector__XXX
 SG_ Hvsp7VltgLvlNgtvTChsssGrndVltg : 16|16@1+ (0.05,0) [0|3212.75] "V" Vector__XXX

BO_ 2364679166 HVESP8S2: 8 Vector__XXX
 SG_ Hvsp8DshrgPwrLmtDTSttOfChrg : 0|2@1+ (1,0) [0|3] "" Vector__XXX
 SG_ Hvsp8DshrgPwrLmtDTBttrTmprtr : 2|2@1+ (1,0) [0|3] "" Vector__XXX
 SG_ Hvsp8DsPwLtDTBttDstCdt : 4|2@1+ (1,0) [0|3] "" Vector__XXX
 SG_ Hvsp8DshrgPwrLmtDTBttrOrCllVltg : 6|2@1+ (1,0) [0|3] "" Vector__XXX
 SG_ Hvsp8DshrgPwrLmtDTBttrCrrnt : 8|2@1+ (1,0) [0|3] "" Vector__XXX
 SG_ Hvsp8DshrgPwrLmtDTAnUndfndCs : 10|2@1+ (1,0) [0|3] "" Vector__XXX
 SG_ Hvsp8ChrgPwrLmtDTSttOfChrg : 32|2@1+ (1,0) [0|3] "" Vector__XXX
 SG_ Hvsp8ChrgPwrLmtDTBttrTmprtr : 34|2@1+ (1,0) [0|3] "" Vector__XXX
 SG_ Hvsp8ChrgPwrLmtDTBttrDgnstCndtn : 36|2@1+ (1,0) [0|3] "" Vector__XXX
 SG_ Hvsp8ChrgPwrLmtDTBttrOrCllVltg : 38|2@1+ (1,0) [0|3] "" Vector__XXX
 SG_ Hvsp8ChrgPwrLmtDTBttrCrrnt : 40|2@1+ (1,0) [0|3] "" Vector__XXX
 SG_ Hvsp8ChrgPwrLmtDTAnUndfndCs : 42|2@1+ (1,0) [0|3] "" Vector__XXX

BO_ 2364679422 HVESP8D1: 8 Vector__XXX
 SG_ Hvesp8AvailableDischargePower : 0|16@1+ (0.05,0) [0|3212.75] "kW" Vector__XXX
 SG_ Hvesp8AvailableChargePower : 16|16@1+ (0.05,0) [0|3212.75] "kW" Vector__XXX
 SG_ Hvesp8VoltageLevel : 32|16@1+ (0.05,0) [0|3212.75] "V" Vector__XXX
 SG_ Hvesp8Current : 48|16@1+ (0.05,-1600) [-1600|1612.75] "A" Vector__XXX

BO_ 2364679678 HVESP8D2: 8 Vector__XXX
 SG_ Hvesp8FastUpdateStateOfCharge : 0|16@1+ (0.0015625,0) [0|100.3984375] "%" Vector__XXX
 SG_ Hvesp8HighestCellVoltage : 16|16@1+ (0.001,0) [0|64.255] "V" Vector__XXX
 SG_ Hvesp8LowestCellVoltage : 32|16@1+ (0.001,0) [0|64.255] "V" Vector__XXX
 SG_ Hvsp8CllVltgDffrntlStts : 48|4@1+ (1,0) [0|15] "" Vector__XXX

BO_ 2364679934 HVESP8D3: 8 Vector__XXX
 SG_ Hvesp8HighestCellTemperature : 0|16@1+ (0.03125,-273) [-273|1734.96875] "degC" Vector__XXX
 SG_ Hvesp8LowestCellTemperature : 16|16@1+ (0.03125,-273) [-273|1734.96875] "degC" Vector__XXX
 SG_ Hvesp8AverageCellTemperature : 32|16@1+ (0.03125,-273) [-273|1734.96875] "degC" Vector__XXX
 SG_ Hvsp8CllTmprtrDffrntlStts : 48|2@1+ (1,0) [0|3] "" Vector__XXX

BO_ 2364680190 HVESP8D4: 8 Vector__XXX
 SG_ Hvesp8DischargeCapacity : 0|16@1+ (0.01,0) [0|642.55] "Ah" Vector__XXX
 SG_ Hvesp8ChargeCapacity : 16|16@1+ (0.01,0) [0|642.55] "Ah" Vector__XXX
 SG_ Hvesp8CellBalancingCount : 32|16@1+ (1,0) [0|64255] "count" Vector__XXX

BO_ 2364680446 HVESP8D5: 8 Vector__XXX
 SG_ Hvesp8LowestCellStateOfCharge : 32|16@1+ (0.0015625,0) [0|100.3984375] "%" Vector__XXX
 SG_ Hvesp8HighestCellStateOfCharge : 48|16@1+ (0.0015625,0) [0|100.3984375] "%" Vector__XXX
 SG_ Hvsp8MxmmInstntnsDshrgCrrntLmt : 0|16@1+ (0.05,-1600) [-1600|0] "A" Vector__XXX
 SG_ Hvsp8MxmmInstntnsChrgCrrntLmt : 16|16@1+ (0.05,-1600) [0|1612.75] "A" Vector__XXX

BO_ 2364680702 HVESP8D6: 8 Vector__XXX
 SG_ Hvesp8BusVoltage : 0|16@1+ (0.05,0) [0|3212.75] "V" Vector__XXX
 SG_ Hvesp8IgnitionVoltage : 16|16@1+ (0.01,0) [0|642.55] "V" Vector__XXX
 SG_ Hvesp8IntakeCoolantTemperature : 32|8@1+ (1,-40) [-40|210] "degC" Vector__XXX
 SG_ Hvesp8OutletCoolantTemperature : 40|8@1+ (1,-40) [-40|210] "degC" Vector__XXX
 SG_ Hvesp8ElectronicsTemperature : 48|8@1+ (1,-40) [-40|210] "degC" Vector__XXX
 SG_ Hvesp8Temperature : 56|8@1+ (1,-40) [-40|210] "degC" Vector__XXX

BO_ 2364680958 HVESP8S1: 8 Vector__XXX
 SG_ Hvesp8HvilStatus : 20|2@1+ (1,0) [0|3] "" Vector__XXX
 SG_ Hvesp8InertiaSwitchStatus : 22|2@1+ (1,0) [0|3] "" Vector__XXX
 SG_ Hvesp8StateOfChargeStatus : 24|4@1+ (1,0) [0|15] "" Vector__XXX
 SG_ Hvesp8CellBalanceStatus : 28|2@1+ (1,0) [0|3] "" Vector__XXX
 SG_ Hvesp8CellBalancingActive : 30|2@1+ (1,0) [0|3] "" Vector__XXX
 SG_ Hvesp8InternalChargerStatus : 32|2@1+ (1,0) [0|3] "" Vector__XXX
 SG_ Hvesp8OperationalStatus : 44|4@1+ (1,0) [0|15] "" Vector__XXX
 SG_ Hvesp8Status1Counter : 52|4@1+ (1,0) [0|15] "" Vector__XXX
 SG_ Hvesp8Status1Crc : 56|8@1+ (1,0) [0|250] "count" Vector__XXX
 SG_ Hvsp8HghVltgBsPstvCnttrStt : 0|2@1+ (1,0) [0|3] "" Vector__XXX
 SG_ Hvsp8HghVltgBsNgtvCnttrStt : 2|2@1+ (1,0) [0|3] "" Vector__XXX
 SG_ Hvsp8HghVltgBsDsnntFrwrnng : 4|4@1+ (1,0) [0|15] "" Vector__XXX
 SG_ Hvsp8HghVltgBsPrChrgRlStt : 8|2@1+ (1,0) [0|3] "" Vector__XXX
 SG_ Hvsp8CntrOfPkCnttrStt : 10|2@1+ (1,0) [0|3] "" Vector__XXX
 SG_ Hvsp8HghVltgBsAtvIsltnTstStts : 12|4@1+ (1,0) [0|15] "" Vector__XXX
 SG_ Hvsp8HghVltgBsPssvIsltnTstStts : 16|4@1+ (1,0) [0|15] "" Vector__XXX
 SG_ Hvsp8HghVltgBsCnntnStts : 40|4@1+ (1,0) [0|15] "" Vector__XXX

BO_ 2364681214 HVESP8D7: 8 Vector__XXX
 SG_ Hvesp8DischargeEnergyCapacity : 0|24@1+ (0.001,0) [0|16449.535] "kWh" Vector__XXX
 SG_ Hvesp8ChargeEnergyCapacity : 24|24@1+ (0.001,0) [0|16449.535] "kWh" Vector__XXX
 SG_ Hvesp8MaximumChargeVoltageLimit : 48|16@1+ (0.05,0) [0|3212.75] "V" Vector__XXX

BO_ 2364681470 HVESP8MS1: 8 Vector__XXX
 SG_ Hvesp8Module1OperationalStatus : 0|2@1+ (1,0) [0|3] "" Vector__XXX
 SG_ Hvesp8Module2OperationalStatus : 2|2@1+ (1,0) [0|3] "" Vector__XXX
 SG_ Hvesp8Module3OperationalStatus : 4|2@1+ (1,0) [0|3] "" Vector__XXX
 SG_ Hvesp8Module4OperationalStatus : 6|2@1+ (1,0) [0|3] "" Vector__XXX
 SG_ Hvesp8Module5OperationalStatus : 8|2@1+ (1,0) [0|3] "" Vector__XXX
 SG_ Hvesp8Module6OperationalStatus : 10|2@1+ (1,0) [0|3] "" Vector__XXX
 SG_ Hvesp8Module7OperationalStatus : 12|2@1+ (1,0) [0|3] "" Vector__XXX
 SG_ Hvesp8Module8OperationalStatus : 14|2@1+ (1,0) [0|3] "" Vector__XXX
 SG_ Hvesp8Module9OperationalStatus : 16|2@1+ (1,0) [0|3] "" Vector__XXX
 SG_ Hvesp8Module10OperationalStatus : 18|2@1+ (1,0) [0|3] "" Vector__XXX
 SG_ Hvesp8Module11OperationalStatus : 20|2@1+ (1,0) [0|3] "" Vector__XXX
 SG_ Hvesp8Module12OperationalStatus : 22|2@1+ (1,0) [0|3] "" Vector__XXX
 SG_ Hvesp8Module13OperationalStatus : 24|2@1+ (1,0) [0|3] "" Vector__XXX
 SG_ Hvesp8Module14OperationalStatus : 26|2@1+ (1,0) [0|3] "" Vector__XXX
 SG_ Hvesp8Module15OperationalStatus : 28|2@1+ (1,0) [0|3] "" Vector__XXX
 SG_ Hvesp8Module16OperationalStatus : 30|2@1+ (1,0) [0|3] "" Vector__XXX
 SG_ Hvesp8Module17OperationalStatus : 32|2@1+ (1,0) [0|3] "" Vector__XXX
 SG_ Hvesp8Module18OperationalStatus : 34|2@1+ (1,0) [0|3] "" Vector__XXX
 SG_ Hvesp8Module19OperationalStatus : 36|2@1+ (1,0) [0|3] "" Vector__XXX
 SG_ Hvesp8Module20OperationalStatus : 38|2@1+ (1,0) [0|3] "" Vector__XXX
 SG_ Hvesp8Module21OperationalStatus : 40|2@1+ (1,0) [0|3] "" Vector__XXX
 SG_ Hvesp8Module22OperationalStatus : 42|2@1+ (1,0) [0|3] "" Vector__XXX
 SG_ Hvesp8Module23OperationalStatus : 44|2@1+ (1,0) [0|3] "" Vector__XXX
 SG_ Hvesp8Module24OperationalStatus : 46|2@1+ (1,0) [0|3] "" Vector__XXX
 SG_ Hvesp8Module25OperationalStatus : 48|2@1+ (1,0) [0|3] "" Vector__XXX
 SG_ Hvesp8Module26OperationalStatus : 50|2@1+ (1,0) [0|3] "" Vector__XXX
 SG_ Hvesp8Module27OperationalStatus : 52|2@1+ (1,0) [0|3] "" Vector__XXX
 SG_ Hvesp8Module28OperationalStatus : 54|2@1+ (1,0) [0|3] "" Vector__XXX
 SG_ Hvesp8Module29OperationalStatus : 56|2@1+ (1,0) [0|3] "" Vector__XXX
 SG_ Hvesp8Module30OperationalStatus : 58|2@1+ (1,0) [0|3] "" Vector__XXX
 SG_ Hvesp8Module31OperationalStatus : 60|2@1+ (1,0) [0|3] "" Vector__XXX
 SG_ Hvesp8Module32OperationalStatus : 62|2@1+ (1,0) [0|3] "" Vector__XXX

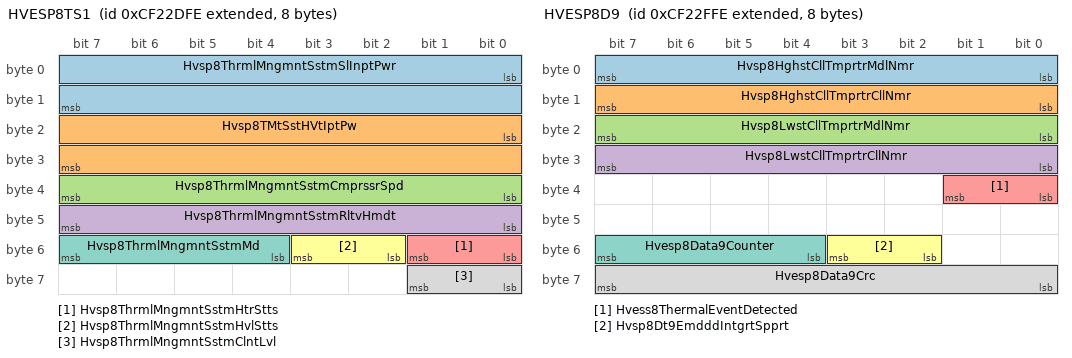
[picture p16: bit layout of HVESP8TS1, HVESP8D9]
BO_ 2364681726 HVESP8TS1: 8 Vector__XXX
 SG_ Hvsp8ThrmlMngmntSstmSlInptPwr : 0|16@1+ (0.5,0) [0|32127.5] "W" Vector__XXX
 SG_ Hvsp8TMtSstHVtIptPw : 16|16@1+ (0.5,0) [0|32127.5] "W" Vector__XXX
 SG_ Hvsp8ThrmlMngmntSstmCmprssrSpd : 32|8@1+ (32,0) [0|8000] "rpm" Vector__XXX
 SG_ Hvsp8ThrmlMngmntSstmRltvHmdt : 40|8@1+ (0.4,0) [0|100] "%" Vector__XXX
 SG_ Hvsp8ThrmlMngmntSstmHtrStts : 48|2@1+ (1,0) [0|3] "" Vector__XXX
 SG_ Hvsp8ThrmlMngmntSstmHvlStts : 50|2@1+ (1,0) [0|3] "" Vector__XXX
 SG_ Hvsp8ThrmlMngmntSstmMd : 52|4@1+ (1,0) [0|15] "" Vector__XXX
 SG_ Hvsp8ThrmlMngmntSstmClntLvl : 56|2@1+ (1,0) [0|3] "" Vector__XXX

BO_ 2364681982 HVESP8D8: 8 Vector__XXX
 SG_ Hvesp8AverageCellVoltage : 32|16@1+ (0.001,0) [0|64.255] "V" Vector__XXX
 SG_ Hvsp8HghstCllVltgMdlNmr : 0|8@1+ (1,0) [0|250] "count" Vector__XXX
 SG_ Hvsp8HghstCllVltgCllNmr : 8|8@1+ (1,0) [0|250] "count" Vector__XXX
 SG_ Hvsp8LwstCllVltgMdlNmr : 16|8@1+ (1,0) [0|250] "count" Vector__XXX
 SG_ Hvsp8LwstCllVltgCllNmr : 24|8@1+ (1,0) [0|250] "count" Vector__XXX

BO_ 2364682238 HVESP8D9: 8 Vector__XXX
 SG_ Hvsp8HghstCllTmprtrMdlNmr : 0|8@1+ (1,0) [0|250] "count" Vector__XXX
 SG_ Hvsp8HghstCllTmprtrCllNmr : 8|8@1+ (1,0) [0|250] "count" Vector__XXX
 SG_ Hvsp8LwstCllTmprtrMdlNmr : 16|8@1+ (1,0) [0|250] "count" Vector__XXX
 SG_ Hvsp8LwstCllTmprtrCllNmr : 24|8@1+ (1,0) [0|250] "count" Vector__XXX
 SG_ Hvess8ThermalEventDetected : 32|2@1+ (1,0) [0|3] "" Vector__XXX
 SG_ Hvsp8Dt9EmdddIntgrtSpprt : 50|2@1+ (1,0) [0|3] "" Vector__XXX
 SG_ Hvesp8Data9Counter : 52|4@1+ (1,0) [0|15] "" Vector__XXX
 SG_ Hvesp8Data9Crc : 56|8@1+ (1,0) [0|250] "count" Vector__XXX

BO_ 2364682494 HVESP8D10: 8 Vector__XXX
 SG_ Hvsp8HghstCllSttOfChrgMdlNmr : 0|8@1+ (1,0) [0|250] "count" Vector__XXX
 SG_ Hvsp8HghstCllSttOfChrgCllNmr : 8|8@1+ (1,0) [0|250] "count" Vector__XXX
 SG_ Hvsp8LwstCllSttOfChrgMdlNmr : 16|8@1+ (1,0) [0|250] "count" Vector__XXX
 SG_ Hvsp8LwstCllSttOfChrgCllNmr : 24|8@1+ (1,0) [0|250] "count" Vector__XXX
 SG_ Hvsp8HghVltgBsAtvIsltnTstRslts : 32|16@1+ (0.1,0) [0|6425.5] "OhmPerV" Vector__XXX
 SG_ Hvsp8HghVltgBsPssvIsltnTstRslts : 48|16@1+ (0.1,0) [0|6425.5] "OhmPerV" Vector__XXX

BO_ 2364682750 HVESP8D11: 8 Vector__XXX
 SG_ Hvesp8ActualChargeRate : 32|16@1+ (0.05,0) [0|3212.75] "kW" Vector__XXX
 SG_ Hvsp8BsVltgNgtvTChsssGrndVltg : 0|16@1+ (0.05,0) [0|3212.75] "V" Vector__XXX
 SG_ Hvsp8VltgLvlNgtvTChsssGrndVltg : 16|16@1+ (0.05,0) [0|3212.75] "V" Vector__XXX

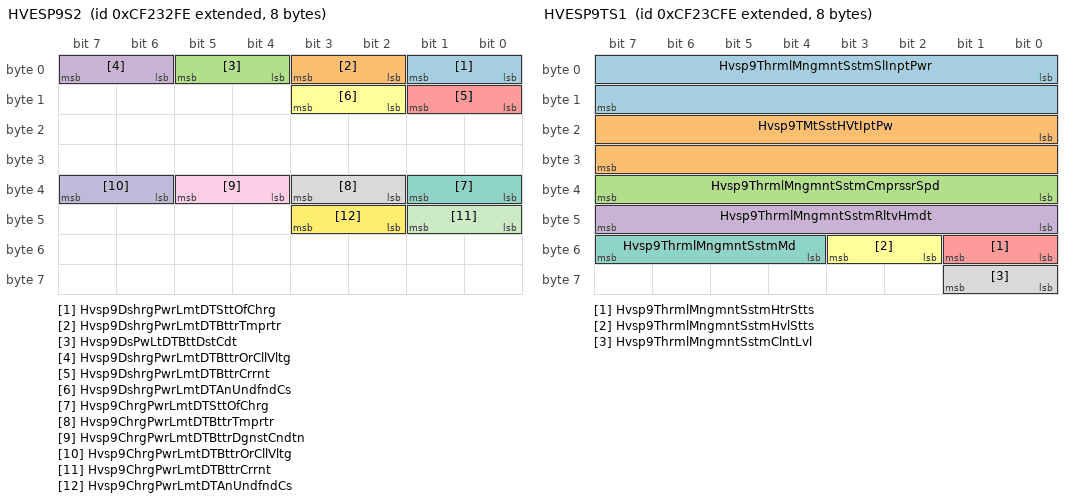
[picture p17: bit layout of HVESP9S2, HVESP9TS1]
BO_ 2364683006 HVESP9S2: 8 Vector__XXX
 SG_ Hvsp9DshrgPwrLmtDTSttOfChrg : 0|2@1+ (1,0) [0|3] "" Vector__XXX
 SG_ Hvsp9DshrgPwrLmtDTBttrTmprtr : 2|2@1+ (1,0) [0|3] "" Vector__XXX
 SG_ Hvsp9DsPwLtDTBttDstCdt : 4|2@1+ (1,0) [0|3] "" Vector__XXX
 SG_ Hvsp9DshrgPwrLmtDTBttrOrCllVltg : 6|2@1+ (1,0) [0|3] "" Vector__XXX
 SG_ Hvsp9DshrgPwrLmtDTBttrCrrnt : 8|2@1+ (1,0) [0|3] "" Vector__XXX
 SG_ Hvsp9DshrgPwrLmtDTAnUndfndCs : 10|2@1+ (1,0) [0|3] "" Vector__XXX
 SG_ Hvsp9ChrgPwrLmtDTSttOfChrg : 32|2@1+ (1,0) [0|3] "" Vector__XXX
 SG_ Hvsp9ChrgPwrLmtDTBttrTmprtr : 34|2@1+ (1,0) [0|3] "" Vector__XXX
 SG_ Hvsp9ChrgPwrLmtDTBttrDgnstCndtn : 36|2@1+ (1,0) [0|3] "" Vector__XXX
 SG_ Hvsp9ChrgPwrLmtDTBttrOrCllVltg : 38|2@1+ (1,0) [0|3] "" Vector__XXX
 SG_ Hvsp9ChrgPwrLmtDTBttrCrrnt : 40|2@1+ (1,0) [0|3] "" Vector__XXX
 SG_ Hvsp9ChrgPwrLmtDTAnUndfndCs : 42|2@1+ (1,0) [0|3] "" Vector__XXX

BO_ 2364683262 HVESP9D1: 8 Vector__XXX
 SG_ Hvesp9AvailableDischargePower : 0|16@1+ (0.05,0) [0|3212.75] "kW" Vector__XXX
 SG_ Hvesp9AvailableChargePower : 16|16@1+ (0.05,0) [0|3212.75] "kW" Vector__XXX
 SG_ Hvesp9VoltageLevel : 32|16@1+ (0.05,0) [0|3212.75] "V" Vector__XXX
 SG_ Hvesp9Current : 48|16@1+ (0.05,-1600) [-1600|1612.75] "A" Vector__XXX

BO_ 2364683518 HVESP9D2: 8 Vector__XXX
 SG_ Hvesp9FastUpdateStateOfCharge : 0|16@1+ (0.0015625,0) [0|100.3984375] "%" Vector__XXX
 SG_ Hvesp9HighestCellVoltage : 16|16@1+ (0.001,0) [0|64.255] "V" Vector__XXX
 SG_ Hvesp9LowestCellVoltage : 32|16@1+ (0.001,0) [0|64.255] "V" Vector__XXX
 SG_ Hvsp9CllVltgDffrntlStts : 48|4@1+ (1,0) [0|15] "" Vector__XXX

BO_ 2364683774 HVESP9D3: 8 Vector__XXX
 SG_ Hvesp9HighestCellTemperature : 0|16@1+ (0.03125,-273) [-273|1734.96875] "degC" Vector__XXX
 SG_ Hvesp9LowestCellTemperature : 16|16@1+ (0.03125,-273) [-273|1734.96875] "degC" Vector__XXX
 SG_ Hvesp9AverageCellTemperature : 32|16@1+ (0.03125,-273) [-273|1734.96875] "degC" Vector__XXX
 SG_ Hvsp9CllTmprtrDffrntlStts : 48|2@1+ (1,0) [0|3] "" Vector__XXX

BO_ 2364684030 HVESP9D4: 8 Vector__XXX
 SG_ Hvesp9DischargeCapacity : 0|16@1+ (0.01,0) [0|642.55] "Ah" Vector__XXX
 SG_ Hvesp9ChargeCapacity : 16|16@1+ (0.01,0) [0|642.55] "Ah" Vector__XXX
 SG_ Hvesp9CellBalancingCount : 32|16@1+ (1,0) [0|64255] "count" Vector__XXX

BO_ 2364684286 HVESP9D5: 8 Vector__XXX
 SG_ Hvesp9LowestCellStateOfCharge : 32|16@1+ (0.0015625,0) [0|100.3984375] "%" Vector__XXX
 SG_ Hvesp9HighestCellStateOfCharge : 48|16@1+ (0.0015625,0) [0|100.3984375] "%" Vector__XXX
 SG_ Hvsp9MxmmInstntnsDshrgCrrntLmt : 0|16@1+ (0.05,-1600) [-1600|0] "A" Vector__XXX
 SG_ Hvsp9MxmmInstntnsChrgCrrntLmt : 16|16@1+ (0.05,-1600) [0|1612.75] "A" Vector__XXX

BO_ 2364684542 HVESP9D6: 8 Vector__XXX
 SG_ Hvesp9BusVoltage : 0|16@1+ (0.05,0) [0|3212.75] "V" Vector__XXX
 SG_ Hvesp9IgnitionVoltage : 16|16@1+ (0.01,0) [0|642.55] "V" Vector__XXX
 SG_ Hvesp9IntakeCoolantTemperature : 32|8@1+ (1,-40) [-40|210] "degC" Vector__XXX
 SG_ Hvesp9OutletCoolantTemperature : 40|8@1+ (1,-40) [-40|210] "degC" Vector__XXX
 SG_ Hvesp9ElectronicsTemperature : 48|8@1+ (1,-40) [-40|210] "degC" Vector__XXX
 SG_ Hvesp9Temperature : 56|8@1+ (1,-40) [-40|210] "degC" Vector__XXX

BO_ 2364684798 HVESP9S1: 8 Vector__XXX
 SG_ Hvesp9HvilStatus : 20|2@1+ (1,0) [0|3] "" Vector__XXX
 SG_ Hvesp9InertiaSwitchStatus : 22|2@1+ (1,0) [0|3] "" Vector__XXX
 SG_ Hvesp9StateOfChargeStatus : 24|4@1+ (1,0) [0|15] "" Vector__XXX
 SG_ Hvesp9CellBalanceStatus : 28|2@1+ (1,0) [0|3] "" Vector__XXX
 SG_ Hvesp9CellBalancingActive : 30|2@1+ (1,0) [0|3] "" Vector__XXX
 SG_ Hvesp9InternalChargerStatus : 32|2@1+ (1,0) [0|3] "" Vector__XXX
 SG_ Hvesp9OperationalStatus : 44|4@1+ (1,0) [0|15] "" Vector__XXX
 SG_ Hvesp9Status1Counter : 52|4@1+ (1,0) [0|15] "" Vector__XXX
 SG_ Hvesp9Status1Crc : 56|8@1+ (1,0) [0|250] "count" Vector__XXX
 SG_ Hvsp9HghVltgBsPstvCnttrStt : 0|2@1+ (1,0) [0|3] "" Vector__XXX
 SG_ Hvsp9HghVltgBsNgtvCnttrStt : 2|2@1+ (1,0) [0|3] "" Vector__XXX
 SG_ Hvsp9HghVltgBsDsnntFrwrnng : 4|4@1+ (1,0) [0|15] "" Vector__XXX
 SG_ Hvsp9HghVltgBsPrChrgRlStt : 8|2@1+ (1,0) [0|3] "" Vector__XXX
 SG_ Hvsp9CntrOfPkCnttrStt : 10|2@1+ (1,0) [0|3] "" Vector__XXX
 SG_ Hvsp9HghVltgBsAtvIsltnTstStts : 12|4@1+ (1,0) [0|15] "" Vector__XXX
 SG_ Hvsp9HghVltgBsPssvIsltnTstStts : 16|4@1+ (1,0) [0|15] "" Vector__XXX
 SG_ Hvsp9HghVltgBsCnntnStts : 40|4@1+ (1,0) [0|15] "" Vector__XXX

BO_ 2364685054 HVESP9D7: 8 Vector__XXX
 SG_ Hvesp9DischargeEnergyCapacity : 0|24@1+ (0.001,0) [0|16449.535] "kWh" Vector__XXX
 SG_ Hvesp9ChargeEnergyCapacity : 24|24@1+ (0.001,0) [0|16449.535] "kWh" Vector__XXX
 SG_ Hvesp9MaximumChargeVoltageLimit : 48|16@1+ (0.05,0) [0|3212.75] "V" Vector__XXX

BO_ 2364685310 HVESP9MS1: 8 Vector__XXX
 SG_ Hvesp9Module1OperationalStatus : 0|2@1+ (1,0) [0|3] "" Vector__XXX
 SG_ Hvesp9Module2OperationalStatus : 2|2@1+ (1,0) [0|3] "" Vector__XXX
 SG_ Hvesp9Module3OperationalStatus : 4|2@1+ (1,0) [0|3] "" Vector__XXX
 SG_ Hvesp9Module4OperationalStatus : 6|2@1+ (1,0) [0|3] "" Vector__XXX
 SG_ Hvesp9Module5OperationalStatus : 8|2@1+ (1,0) [0|3] "" Vector__XXX
 SG_ Hvesp9Module6OperationalStatus : 10|2@1+ (1,0) [0|3] "" Vector__XXX
 SG_ Hvesp9Module7OperationalStatus : 12|2@1+ (1,0) [0|3] "" Vector__XXX
 SG_ Hvesp9Module8OperationalStatus : 14|2@1+ (1,0) [0|3] "" Vector__XXX
 SG_ Hvesp9Module9OperationalStatus : 16|2@1+ (1,0) [0|3] "" Vector__XXX
 SG_ Hvesp9Module10OperationalStatus : 18|2@1+ (1,0) [0|3] "" Vector__XXX
 SG_ Hvesp9Module11OperationalStatus : 20|2@1+ (1,0) [0|3] "" Vector__XXX
 SG_ Hvesp9Module12OperationalStatus : 22|2@1+ (1,0) [0|3] "" Vector__XXX
 SG_ Hvesp9Module13OperationalStatus : 24|2@1+ (1,0) [0|3] "" Vector__XXX
 SG_ Hvesp9Module14OperationalStatus : 26|2@1+ (1,0) [0|3] "" Vector__XXX
 SG_ Hvesp9Module15OperationalStatus : 28|2@1+ (1,0) [0|3] "" Vector__XXX
 SG_ Hvesp9Module16OperationalStatus : 30|2@1+ (1,0) [0|3] "" Vector__XXX
 SG_ Hvesp9Module17OperationalStatus : 32|2@1+ (1,0) [0|3] "" Vector__XXX
 SG_ Hvesp9Module18OperationalStatus : 34|2@1+ (1,0) [0|3] "" Vector__XXX
 SG_ Hvesp9Module19OperationalStatus : 36|2@1+ (1,0) [0|3] "" Vector__XXX
 SG_ Hvesp9Module20OperationalStatus : 38|2@1+ (1,0) [0|3] "" Vector__XXX
 SG_ Hvesp9Module21OperationalStatus : 40|2@1+ (1,0) [0|3] "" Vector__XXX
 SG_ Hvesp9Module22OperationalStatus : 42|2@1+ (1,0) [0|3] "" Vector__XXX
 SG_ Hvesp9Module23OperationalStatus : 44|2@1+ (1,0) [0|3] "" Vector__XXX
 SG_ Hvesp9Module24OperationalStatus : 46|2@1+ (1,0) [0|3] "" Vector__XXX
 SG_ Hvesp9Module25OperationalStatus : 48|2@1+ (1,0) [0|3] "" Vector__XXX
 SG_ Hvesp9Module26OperationalStatus : 50|2@1+ (1,0) [0|3] "" Vector__XXX
 SG_ Hvesp9Module27OperationalStatus : 52|2@1+ (1,0) [0|3] "" Vector__XXX
 SG_ Hvesp9Module28OperationalStatus : 54|2@1+ (1,0) [0|3] "" Vector__XXX
 SG_ Hvesp9Module29OperationalStatus : 56|2@1+ (1,0) [0|3] "" Vector__XXX
 SG_ Hvesp9Module30OperationalStatus : 58|2@1+ (1,0) [0|3] "" Vector__XXX
 SG_ Hvesp9Module31OperationalStatus : 60|2@1+ (1,0) [0|3] "" Vector__XXX
 SG_ Hvesp9Module32OperationalStatus : 62|2@1+ (1,0) [0|3] "" Vector__XXX

BO_ 2364685566 HVESP9TS1: 8 Vector__XXX
 SG_ Hvsp9ThrmlMngmntSstmSlInptPwr : 0|16@1+ (0.5,0) [0|32127.5] "W" Vector__XXX
 SG_ Hvsp9TMtSstHVtIptPw : 16|16@1+ (0.5,0) [0|32127.5] "W" Vector__XXX
 SG_ Hvsp9ThrmlMngmntSstmCmprssrSpd : 32|8@1+ (32,0) [0|8000] "rpm" Vector__XXX
 SG_ Hvsp9ThrmlMngmntSstmRltvHmdt : 40|8@1+ (0.4,0) [0|100] "%" Vector__XXX
 SG_ Hvsp9ThrmlMngmntSstmHtrStts : 48|2@1+ (1,0) [0|3] "" Vector__XXX
 SG_ Hvsp9ThrmlMngmntSstmHvlStts : 50|2@1+ (1,0) [0|3] "" Vector__XXX
 SG_ Hvsp9ThrmlMngmntSstmMd : 52|4@1+ (1,0) [0|15] "" Vector__XXX
 SG_ Hvsp9ThrmlMngmntSstmClntLvl : 56|2@1+ (1,0) [0|3] "" Vector__XXX

BO_ 2364685822 HVESP9D8: 8 Vector__XXX
 SG_ Hvesp9AverageCellVoltage : 32|16@1+ (0.001,0) [0|64.255] "V" Vector__XXX
 SG_ Hvsp9HghstCllVltgMdlNmr : 0|8@1+ (1,0) [0|250] "count" Vector__XXX
 SG_ Hvsp9HghstCllVltgCllNmr : 8|8@1+ (1,0) [0|250] "count" Vector__XXX
 SG_ Hvsp9LwstCllVltgMdlNmr : 16|8@1+ (1,0) [0|250] "count" Vector__XXX
 SG_ Hvsp9LwstCllVltgCllNmr : 24|8@1+ (1,0) [0|250] "count" Vector__XXX

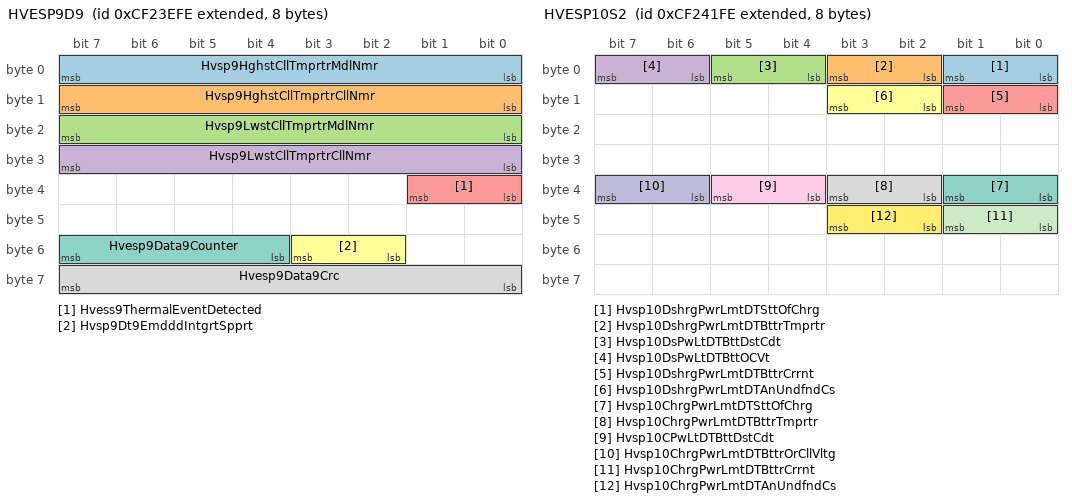
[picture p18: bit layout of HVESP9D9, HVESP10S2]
BO_ 2364686078 HVESP9D9: 8 Vector__XXX
 SG_ Hvsp9HghstCllTmprtrMdlNmr : 0|8@1+ (1,0) [0|250] "count" Vector__XXX
 SG_ Hvsp9HghstCllTmprtrCllNmr : 8|8@1+ (1,0) [0|250] "count" Vector__XXX
 SG_ Hvsp9LwstCllTmprtrMdlNmr : 16|8@1+ (1,0) [0|250] "count" Vector__XXX
 SG_ Hvsp9LwstCllTmprtrCllNmr : 24|8@1+ (1,0) [0|250] "count" Vector__XXX
 SG_ Hvess9ThermalEventDetected : 32|2@1+ (1,0) [0|3] "" Vector__XXX
 SG_ Hvsp9Dt9EmdddIntgrtSpprt : 50|2@1+ (1,0) [0|3] "" Vector__XXX
 SG_ Hvesp9Data9Counter : 52|4@1+ (1,0) [0|15] "" Vector__XXX
 SG_ Hvesp9Data9Crc : 56|8@1+ (1,0) [0|250] "count" Vector__XXX

BO_ 2364686334 HVESP9D10: 8 Vector__XXX
 SG_ Hvsp9HghstCllSttOfChrgMdlNmr : 0|8@1+ (1,0) [0|250] "count" Vector__XXX
 SG_ Hvsp9HghstCllSttOfChrgCllNmr : 8|8@1+ (1,0) [0|250] "count" Vector__XXX
 SG_ Hvsp9LwstCllSttOfChrgMdlNmr : 16|8@1+ (1,0) [0|250] "count" Vector__XXX
 SG_ Hvsp9LwstCllSttOfChrgCllNmr : 24|8@1+ (1,0) [0|250] "count" Vector__XXX
 SG_ Hvsp9HghVltgBsAtvIsltnTstRslts : 32|16@1+ (0.1,0) [0|6425.5] "OhmPerV" Vector__XXX
 SG_ Hvsp9HghVltgBsPssvIsltnTstRslts : 48|16@1+ (0.1,0) [0|6425.5] "OhmPerV" Vector__XXX

BO_ 2364686590 HVESP9D11: 8 Vector__XXX
 SG_ Hvesp9ActualChargeRate : 32|16@1+ (0.05,0) [0|3212.75] "kW" Vector__XXX
 SG_ Hvsp9BsVltgNgtvTChsssGrndVltg : 0|16@1+ (0.05,0) [0|3212.75] "V" Vector__XXX
 SG_ Hvsp9VltgLvlNgtvTChsssGrndVltg : 16|16@1+ (0.05,0) [0|3212.75] "V" Vector__XXX

BO_ 2364686846 HVESP10S2: 8 Vector__XXX
 SG_ Hvsp10DshrgPwrLmtDTSttOfChrg : 0|2@1+ (1,0) [0|3] "" Vector__XXX
 SG_ Hvsp10DshrgPwrLmtDTBttrTmprtr : 2|2@1+ (1,0) [0|3] "" Vector__XXX
 SG_ Hvsp10DsPwLtDTBttDstCdt : 4|2@1+ (1,0) [0|3] "" Vector__XXX
 SG_ Hvsp10DsPwLtDTBttOCVt : 6|2@1+ (1,0) [0|3] "" Vector__XXX
 SG_ Hvsp10DshrgPwrLmtDTBttrCrrnt : 8|2@1+ (1,0) [0|3] "" Vector__XXX
 SG_ Hvsp10DshrgPwrLmtDTAnUndfndCs : 10|2@1+ (1,0) [0|3] "" Vector__XXX
 SG_ Hvsp10ChrgPwrLmtDTSttOfChrg : 32|2@1+ (1,0) [0|3] "" Vector__XXX
 SG_ Hvsp10ChrgPwrLmtDTBttrTmprtr : 34|2@1+ (1,0) [0|3] "" Vector__XXX
 SG_ Hvsp10CPwLtDTBttDstCdt : 36|2@1+ (1,0) [0|3] "" Vector__XXX
 SG_ Hvsp10ChrgPwrLmtDTBttrOrCllVltg : 38|2@1+ (1,0) [0|3] "" Vector__XXX
 SG_ Hvsp10ChrgPwrLmtDTBttrCrrnt : 40|2@1+ (1,0) [0|3] "" Vector__XXX
 SG_ Hvsp10ChrgPwrLmtDTAnUndfndCs : 42|2@1+ (1,0) [0|3] "" Vector__XXX

BO_ 2364687102 HVESP10D1: 8 Vector__XXX
 SG_ Hvesp10AvailableDischargePower : 0|16@1+ (0.05,0) [0|3212.75] "kW" Vector__XXX
 SG_ Hvesp10AvailableChargePower : 16|16@1+ (0.05,0) [0|3212.75] "kW" Vector__XXX
 SG_ Hvesp10VoltageLevel : 32|16@1+ (0.05,0) [0|3212.75] "V" Vector__XXX
 SG_ Hvesp10Current : 48|16@1+ (0.05,-1600) [-1600|1612.75] "A" Vector__XXX

BO_ 2364687358 HVESP10D2: 8 Vector__XXX
 SG_ Hvesp10FastUpdateStateOfCharge : 0|16@1+ (0.0015625,0) [0|100.3984375] "%" Vector__XXX
 SG_ Hvesp10HighestCellVoltage : 16|16@1+ (0.001,0) [0|64.255] "V" Vector__XXX
 SG_ Hvesp10LowestCellVoltage : 32|16@1+ (0.001,0) [0|64.255] "V" Vector__XXX
 SG_ Hvsp10CllVltgDffrntlStts : 48|4@1+ (1,0) [0|15] "" Vector__XXX

BO_ 2364687614 HVESP10D3: 8 Vector__XXX
 SG_ Hvesp10HighestCellTemperature : 0|16@1+ (0.03125,-273) [-273|1734.96875] "degC" Vector__XXX
 SG_ Hvesp10LowestCellTemperature : 16|16@1+ (0.03125,-273) [-273|1734.96875] "degC" Vector__XXX
 SG_ Hvesp10AverageCellTemperature : 32|16@1+ (0.03125,-273) [-273|1734.96875] "degC" Vector__XXX
 SG_ Hvsp10CllTmprtrDffrntlStts : 48|2@1+ (1,0) [0|3] "" Vector__XXX

BO_ 2364687870 HVESP10D4: 8 Vector__XXX
 SG_ Hvesp10DischargeCapacity : 0|16@1+ (0.01,0) [0|642.55] "Ah" Vector__XXX
 SG_ Hvesp10ChargeCapacity : 16|16@1+ (0.01,0) [0|642.55] "Ah" Vector__XXX
 SG_ Hvesp10CellBalancingCount : 32|16@1+ (1,0) [0|64255] "count" Vector__XXX

BO_ 2364688126 HVESP10D5: 8 Vector__XXX
 SG_ Hvesp10LowestCellStateOfCharge : 32|16@1+ (0.0015625,0) [0|100.3984375] "%" Vector__XXX
 SG_ Hvesp10HighestCellStateOfCharge : 48|16@1+ (0.0015625,0) [0|100.3984375] "%" Vector__XXX
 SG_ Hvsp10MxmmInstntnsDshrgCrrntLmt : 0|16@1+ (0.05,-1600) [-1600|0] "A" Vector__XXX
 SG_ Hvsp10MxmmInstntnsChrgCrrntLmt : 16|16@1+ (0.05,-1600) [0|1612.75] "A" Vector__XXX

BO_ 2364688382 HVESP10D6: 8 Vector__XXX
 SG_ Hvesp10BusVoltage : 0|16@1+ (0.05,0) [0|3212.75] "V" Vector__XXX
 SG_ Hvesp10IgnitionVoltage : 16|16@1+ (0.01,0) [0|642.55] "V" Vector__XXX
 SG_ Hvesp10IntakeCoolantTemperature : 32|8@1+ (1,-40) [-40|210] "degC" Vector__XXX
 SG_ Hvesp10OutletCoolantTemperature : 40|8@1+ (1,-40) [-40|210] "degC" Vector__XXX
 SG_ Hvesp10ElectronicsTemperature : 48|8@1+ (1,-40) [-40|210] "degC" Vector__XXX
 SG_ Hvesp10Temperature : 56|8@1+ (1,-40) [-40|210] "degC" Vector__XXX

BO_ 2364688638 HVESP10S1: 8 Vector__XXX
 SG_ Hvesp10HvilStatus : 20|2@1+ (1,0) [0|3] "" Vector__XXX
 SG_ Hvesp10InertiaSwitchStatus : 22|2@1+ (1,0) [0|3] "" Vector__XXX
 SG_ Hvesp10StateOfChargeStatus : 24|4@1+ (1,0) [0|15] "" Vector__XXX
 SG_ Hvesp10CellBalanceStatus : 28|2@1+ (1,0) [0|3] "" Vector__XXX
 SG_ Hvesp10CellBalancingActive : 30|2@1+ (1,0) [0|3] "" Vector__XXX
 SG_ Hvesp10InternalChargerStatus : 32|2@1+ (1,0) [0|3] "" Vector__XXX
 SG_ Hvesp10OperationalStatus : 44|4@1+ (1,0) [0|15] "" Vector__XXX
 SG_ Hvesp10Status1Counter : 52|4@1+ (1,0) [0|15] "" Vector__XXX
 SG_ Hvesp10Status1Crc : 56|8@1+ (1,0) [0|250] "count" Vector__XXX
 SG_ Hvsp10HghVltgBsPstvCnttrStt : 0|2@1+ (1,0) [0|3] "" Vector__XXX
 SG_ Hvsp10HghVltgBsNgtvCnttrStt : 2|2@1+ (1,0) [0|3] "" Vector__XXX
 SG_ Hvsp10HghVltgBsDsnntFrwrnng : 4|4@1+ (1,0) [0|15] "" Vector__XXX
 SG_ Hvsp10HghVltgBsPrChrgRlStt : 8|2@1+ (1,0) [0|3] "" Vector__XXX
 SG_ Hvsp10CntrOfPkCnttrStt : 10|2@1+ (1,0) [0|3] "" Vector__XXX
 SG_ Hvsp10HghVltgBsAtvIsltnTstStts : 12|4@1+ (1,0) [0|15] "" Vector__XXX
 SG_ Hvsp10HghVltgBsPssvIsltnTstStts : 16|4@1+ (1,0) [0|15] "" Vector__XXX
 SG_ Hvsp10HghVltgBsCnntnStts : 40|4@1+ (1,0) [0|15] "" Vector__XXX

BO_ 2364688894 HVESP10D7: 8 Vector__XXX
 SG_ Hvesp10DischargeEnergyCapacity : 0|24@1+ (0.001,0) [0|16449.535] "kWh" Vector__XXX
 SG_ Hvesp10ChargeEnergyCapacity : 24|24@1+ (0.001,0) [0|16449.535] "kWh" Vector__XXX
 SG_ Hvsp10MxmmChrgVltgLmt : 48|16@1+ (0.05,0) [0|3212.75] "V" Vector__XXX

BO_ 2364689150 HVESP10MS1: 8 Vector__XXX
 SG_ Hvesp10Module1OperationalStatus : 0|2@1+ (1,0) [0|3] "" Vector__XXX
 SG_ Hvesp10Module2OperationalStatus : 2|2@1+ (1,0) [0|3] "" Vector__XXX
 SG_ Hvesp10Module3OperationalStatus : 4|2@1+ (1,0) [0|3] "" Vector__XXX
 SG_ Hvesp10Module4OperationalStatus : 6|2@1+ (1,0) [0|3] "" Vector__XXX
 SG_ Hvesp10Module5OperationalStatus : 8|2@1+ (1,0) [0|3] "" Vector__XXX
 SG_ Hvesp10Module6OperationalStatus : 10|2@1+ (1,0) [0|3] "" Vector__XXX
 SG_ Hvesp10Module7OperationalStatus : 12|2@1+ (1,0) [0|3] "" Vector__XXX
 SG_ Hvesp10Module8OperationalStatus : 14|2@1+ (1,0) [0|3] "" Vector__XXX
 SG_ Hvesp10Module9OperationalStatus : 16|2@1+ (1,0) [0|3] "" Vector__XXX
 SG_ Hvsp10Mdl10OprtnlStts : 18|2@1+ (1,0) [0|3] "" Vector__XXX
 SG_ Hvsp10Mdl11OprtnlStts : 20|2@1+ (1,0) [0|3] "" Vector__XXX
 SG_ Hvsp10Mdl12OprtnlStts : 22|2@1+ (1,0) [0|3] "" Vector__XXX
 SG_ Hvsp10Mdl13OprtnlStts : 24|2@1+ (1,0) [0|3] "" Vector__XXX
 SG_ Hvsp10Mdl14OprtnlStts : 26|2@1+ (1,0) [0|3] "" Vector__XXX
 SG_ Hvsp10Mdl15OprtnlStts : 28|2@1+ (1,0) [0|3] "" Vector__XXX
 SG_ Hvsp10Mdl16OprtnlStts : 30|2@1+ (1,0) [0|3] "" Vector__XXX
 SG_ Hvsp10Mdl17OprtnlStts : 32|2@1+ (1,0) [0|3] "" Vector__XXX
 SG_ Hvsp10Mdl18OprtnlStts : 34|2@1+ (1,0) [0|3] "" Vector__XXX
 SG_ Hvsp10Mdl19OprtnlStts : 36|2@1+ (1,0) [0|3] "" Vector__XXX
 SG_ Hvsp10Mdl20OprtnlStts : 38|2@1+ (1,0) [0|3] "" Vector__XXX
 SG_ Hvsp10Mdl21OprtnlStts : 40|2@1+ (1,0) [0|3] "" Vector__XXX
 SG_ Hvsp10Mdl22OprtnlStts : 42|2@1+ (1,0) [0|3] "" Vector__XXX
 SG_ Hvsp10Mdl23OprtnlStts : 44|2@1+ (1,0) [0|3] "" Vector__XXX
 SG_ Hvsp10Mdl24OprtnlStts : 46|2@1+ (1,0) [0|3] "" Vector__XXX
 SG_ Hvsp10Mdl25OprtnlStts : 48|2@1+ (1,0) [0|3] "" Vector__XXX
 SG_ Hvsp10Mdl26OprtnlStts : 50|2@1+ (1,0) [0|3] "" Vector__XXX
 SG_ Hvsp10Mdl27OprtnlStts : 52|2@1+ (1,0) [0|3] "" Vector__XXX
 SG_ Hvsp10Mdl28OprtnlStts : 54|2@1+ (1,0) [0|3] "" Vector__XXX
 SG_ Hvsp10Mdl29OprtnlStts : 56|2@1+ (1,0) [0|3] "" Vector__XXX
 SG_ Hvsp10Mdl30OprtnlStts : 58|2@1+ (1,0) [0|3] "" Vector__XXX
 SG_ Hvsp10Mdl31OprtnlStts : 60|2@1+ (1,0) [0|3] "" Vector__XXX
 SG_ Hvsp10Mdl32OprtnlStts : 62|2@1+ (1,0) [0|3] "" Vector__XXX

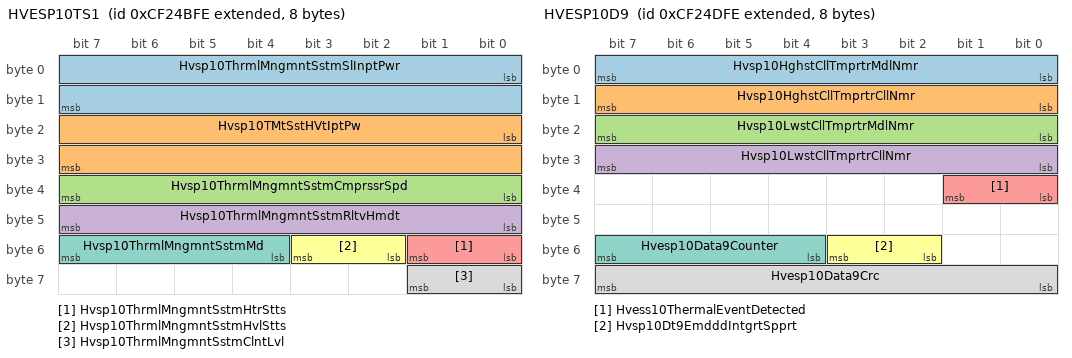
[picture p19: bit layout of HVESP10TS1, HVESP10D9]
BO_ 2364689406 HVESP10TS1: 8 Vector__XXX
 SG_ Hvsp10ThrmlMngmntSstmSlInptPwr : 0|16@1+ (0.5,0) [0|32127.5] "W" Vector__XXX
 SG_ Hvsp10TMtSstHVtIptPw : 16|16@1+ (0.5,0) [0|32127.5] "W" Vector__XXX
 SG_ Hvsp10ThrmlMngmntSstmCmprssrSpd : 32|8@1+ (32,0) [0|8000] "rpm" Vector__XXX
 SG_ Hvsp10ThrmlMngmntSstmRltvHmdt : 40|8@1+ (0.4,0) [0|100] "%" Vector__XXX
 SG_ Hvsp10ThrmlMngmntSstmHtrStts : 48|2@1+ (1,0) [0|3] "" Vector__XXX
 SG_ Hvsp10ThrmlMngmntSstmHvlStts : 50|2@1+ (1,0) [0|3] "" Vector__XXX
 SG_ Hvsp10ThrmlMngmntSstmMd : 52|4@1+ (1,0) [0|15] "" Vector__XXX
 SG_ Hvsp10ThrmlMngmntSstmClntLvl : 56|2@1+ (1,0) [0|3] "" Vector__XXX

BO_ 2364689662 HVESP10D8: 8 Vector__XXX
 SG_ Hvesp10AverageCellVoltage : 32|16@1+ (0.001,0) [0|64.255] "V" Vector__XXX
 SG_ Hvsp10HghstCllVltgMdlNmr : 0|8@1+ (1,0) [0|250] "count" Vector__XXX
 SG_ Hvsp10HghstCllVltgCllNmr : 8|8@1+ (1,0) [0|250] "count" Vector__XXX
 SG_ Hvsp10LwstCllVltgMdlNmr : 16|8@1+ (1,0) [0|250] "count" Vector__XXX
 SG_ Hvsp10LwstCllVltgCllNmr : 24|8@1+ (1,0) [0|250] "count" Vector__XXX

BO_ 2364689918 HVESP10D9: 8 Vector__XXX
 SG_ Hvsp10HghstCllTmprtrMdlNmr : 0|8@1+ (1,0) [0|250] "count" Vector__XXX
 SG_ Hvsp10HghstCllTmprtrCllNmr : 8|8@1+ (1,0) [0|250] "count" Vector__XXX
 SG_ Hvsp10LwstCllTmprtrMdlNmr : 16|8@1+ (1,0) [0|250] "count" Vector__XXX
 SG_ Hvsp10LwstCllTmprtrCllNmr : 24|8@1+ (1,0) [0|250] "count" Vector__XXX
 SG_ Hvess10ThermalEventDetected : 32|2@1+ (1,0) [0|3] "" Vector__XXX
 SG_ Hvsp10Dt9EmdddIntgrtSpprt : 50|2@1+ (1,0) [0|3] "" Vector__XXX
 SG_ Hvesp10Data9Counter : 52|4@1+ (1,0) [0|15] "" Vector__XXX
 SG_ Hvesp10Data9Crc : 56|8@1+ (1,0) [0|250] "count" Vector__XXX

BO_ 2364690174 HVESP10D10: 8 Vector__XXX
 SG_ Hvsp10HghstCllSttOfChrgMdlNmr : 0|8@1+ (1,0) [0|250] "count" Vector__XXX
 SG_ Hvsp10HghstCllSttOfChrgCllNmr : 8|8@1+ (1,0) [0|250] "count" Vector__XXX
 SG_ Hvsp10LwstCllSttOfChrgMdlNmr : 16|8@1+ (1,0) [0|250] "count" Vector__XXX
 SG_ Hvsp10LwstCllSttOfChrgCllNmr : 24|8@1+ (1,0) [0|250] "count" Vector__XXX
 SG_ Hvsp10HghVltgBsAtvIsltnTstRslts : 32|16@1+ (0.1,0) [0|6425.5] "OhmPerV" Vector__XXX
 SG_ Hvsp10HVtBsPssvIstTstRsts : 48|16@1+ (0.1,0) [0|6425.5] "OhmPerV" Vector__XXX

BO_ 2364690430 HVESP10D11: 8 Vector__XXX
 SG_ Hvesp10ActualChargeRate : 32|16@1+ (0.05,0) [0|3212.75] "kW" Vector__XXX
 SG_ Hvsp10BsVltgNgtvTChsssGrndVltg : 0|16@1+ (0.05,0) [0|3212.75] "V" Vector__XXX
 SG_ Hvsp10VltgLvlNgtvTChsssGrndVltg : 16|16@1+ (0.05,0) [0|3212.75] "V" Vector__XXX

BO_ 2566564862 HVESP10CFG: 19 Vector__XXX
 SG_ Hvesp10NominalVoltage : 0|16@1+ (0.05,0) [0|3212.75] "V" Vector__XXX
 SG_ Hvesp10CellMaximumVoltageLimit : 112|8@1+ (0.02044,0) [0|5.11] "V" Vector__XXX
 SG_ Hvesp10CellMinimumVoltageLimit : 120|8@1+ (0.02044,0) [0|5.11] "V" Vector__XXX
 SG_ Hvsp10RmmnddMnmmOprtngVltg : 16|16@1+ (0.05,0) [0|3212.75] "V" Vector__XXX
 SG_ Hvsp10RmmnddMxmmOprtngVltg : 32|16@1+ (0.05,0) [0|3212.75] "V" Vector__XXX
 SG_ Hvsp10RmmnddMnmmSttOfChrg : 48|16@1+ (0.0015625,0) [0|100.3984375] "%" Vector__XXX
 SG_ Hvsp10RmmnddMxmmSttOfChrg : 64|16@1+ (0.0015625,0) [0|100.3984375] "%" Vector__XXX
 SG_ Hvsp10RmmnddMxmmOprtngTmprtr : 80|16@1+ (0.03125,-273) [-273|1734.96875] "degC" Vector__XXX
 SG_ Hvsp10RmmnddMnmmOprtngTmprtr : 96|16@1+ (0.03125,-273) [-273|1734.96875] "degC" Vector__XXX

BO_ 2633673982 HVESP10HIST: 19 Vector__XXX
 SG_ Hvesp10StateOfHealth : 0|8@1+ (0.4,0) [0|100] "%" Vector__XXX
 SG_ Hvesp10TotalEnergyThroughput : 24|32@1+ (100,0) [0|421108121500] "Watt-hour" Vector__XXX
 SG_ Hvesp10TotalAccumulatedCharge : 56|32@1+ (100,0) [0|421108121500] "Ah" Vector__XXX
 SG_ Hvesp10TotalLifetimeEnergyInput : 88|32@1+ (1,0) [0|4211081215] "kWh" Vector__XXX
 SG_ Hvsp10CnttrOpnUndrLdCnt : 8|16@1+ (1,0) [0|64255] "count" Vector__XXX
 SG_ Hvsp10TtlLftmEnrgOtpt : 120|32@1+ (1,0) [0|4211081215] "kWh" Vector__XXX

BO_ 2566565374 HVESP9CFG: 19 Vector__XXX
 SG_ Hvesp9NominalVoltage : 0|16@1+ (0.05,0) [0|3212.75] "V" Vector__XXX
 SG_ Hvesp9CellMaximumVoltageLimit : 112|8@1+ (0.02044,0) [0|5.11] "V" Vector__XXX
 SG_ Hvesp9CellMinimumVoltageLimit : 120|8@1+ (0.02044,0) [0|5.11] "V" Vector__XXX
 SG_ Hvsp9RmmnddMnmmOprtngVltg : 16|16@1+ (0.05,0) [0|3212.75] "V" Vector__XXX
 SG_ Hvsp9RmmnddMxmmOprtngVltg : 32|16@1+ (0.05,0) [0|3212.75] "V" Vector__XXX
 SG_ Hvsp9RmmnddMnmmSttOfChrg : 48|16@1+ (0.0015625,0) [0|100.3984375] "%" Vector__XXX
 SG_ Hvsp9RmmnddMxmmSttOfChrg : 64|16@1+ (0.0015625,0) [0|100.3984375] "%" Vector__XXX
 SG_ Hvsp9RmmnddMxmmOprtngTmprtr : 80|16@1+ (0.03125,-273) [-273|1734.96875] "degC" Vector__XXX
 SG_ Hvsp9RmmnddMnmmOprtngTmprtr : 96|16@1+ (0.03125,-273) [-273|1734.96875] "degC" Vector__XXX

BO_ 2633674494 HVESP9HIST: 19 Vector__XXX
 SG_ Hvesp9StateOfHealth : 0|8@1+ (0.4,0) [0|100] "%" Vector__XXX
 SG_ Hvesp9TotalEnergyThroughput : 24|32@1+ (100,0) [0|421108121500] "Watt-hour" Vector__XXX
 SG_ Hvesp9TotalAccumulatedCharge : 56|32@1+ (100,0) [0|421108121500] "Ah" Vector__XXX
 SG_ Hvesp9TotalLifetimeEnergyInput : 88|32@1+ (1,0) [0|4211081215] "kWh" Vector__XXX
 SG_ Hvesp9TotalLifetimeEnergyOutput : 120|32@1+ (1,0) [0|4211081215] "kWh" Vector__XXX
 SG_ Hvsp9CnttrOpnUndrLdCnt : 8|16@1+ (1,0) [0|64255] "count" Vector__XXX

BO_ 2566565886 HVESP8CFG: 19 Vector__XXX
 SG_ Hvesp8NominalVoltage : 0|16@1+ (0.05,0) [0|3212.75] "V" Vector__XXX
 SG_ Hvesp8CellMaximumVoltageLimit : 112|8@1+ (0.02044,0) [0|5.11] "V" Vector__XXX
 SG_ Hvesp8CellMinimumVoltageLimit : 120|8@1+ (0.02044,0) [0|5.11] "V" Vector__XXX
 SG_ Hvsp8RmmnddMnmmOprtngVltg : 16|16@1+ (0.05,0) [0|3212.75] "V" Vector__XXX
 SG_ Hvsp8RmmnddMxmmOprtngVltg : 32|16@1+ (0.05,0) [0|3212.75] "V" Vector__XXX
 SG_ Hvsp8RmmnddMnmmSttOfChrg : 48|16@1+ (0.0015625,0) [0|100.3984375] "%" Vector__XXX
 SG_ Hvsp8RmmnddMxmmSttOfChrg : 64|16@1+ (0.0015625,0) [0|100.3984375] "%" Vector__XXX
 SG_ Hvsp8RmmnddMxmmOprtngTmprtr : 80|16@1+ (0.03125,-273) [-273|1734.96875] "degC" Vector__XXX
 SG_ Hvsp8RmmnddMnmmOprtngTmprtr : 96|16@1+ (0.03125,-273) [-273|1734.96875] "degC" Vector__XXX

BO_ 2633675006 HVESP8HIST: 19 Vector__XXX
 SG_ Hvesp8StateOfHealth : 0|8@1+ (0.4,0) [0|100] "%" Vector__XXX
 SG_ Hvesp8TotalEnergyThroughput : 24|32@1+ (100,0) [0|421108121500] "Watt-hour" Vector__XXX
 SG_ Hvesp8TotalAccumulatedCharge : 56|32@1+ (100,0) [0|421108121500] "Ah" Vector__XXX
 SG_ Hvesp8TotalLifetimeEnergyInput : 88|32@1+ (1,0) [0|4211081215] "kWh" Vector__XXX
 SG_ Hvesp8TotalLifetimeEnergyOutput : 120|32@1+ (1,0) [0|4211081215] "kWh" Vector__XXX
 SG_ Hvsp8CnttrOpnUndrLdCnt : 8|16@1+ (1,0) [0|64255] "count" Vector__XXX

BO_ 2566566398 HVESP7CFG: 19 Vector__XXX
 SG_ Hvesp7NominalVoltage : 0|16@1+ (0.05,0) [0|3212.75] "V" Vector__XXX
 SG_ Hvesp7CellMaximumVoltageLimit : 112|8@1+ (0.02044,0) [0|5.11] "V" Vector__XXX
 SG_ Hvesp7CellMinimumVoltageLimit : 120|8@1+ (0.02044,0) [0|5.11] "V" Vector__XXX
 SG_ Hvsp7RmmnddMnmmOprtngVltg : 16|16@1+ (0.05,0) [0|3212.75] "V" Vector__XXX
 SG_ Hvsp7RmmnddMxmmOprtngVltg : 32|16@1+ (0.05,0) [0|3212.75] "V" Vector__XXX
 SG_ Hvsp7RmmnddMnmmSttOfChrg : 48|16@1+ (0.0015625,0) [0|100.3984375] "%" Vector__XXX
 SG_ Hvsp7RmmnddMxmmSttOfChrg : 64|16@1+ (0.0015625,0) [0|100.3984375] "%" Vector__XXX
 SG_ Hvsp7RmmnddMxmmOprtngTmprtr : 80|16@1+ (0.03125,-273) [-273|1734.96875] "degC" Vector__XXX
 SG_ Hvsp7RmmnddMnmmOprtngTmprtr : 96|16@1+ (0.03125,-273) [-273|1734.96875] "degC" Vector__XXX

BA_DEF_ BO_  "VFrameFormat" ENUM  "StandardCAN","ExtendedCAN","reserved","J1939PG";
BA_DEF_DEF_  "VFrameFormat" "J1939PG";
